VERSION ""

NS_ :

BS_:

BU_: PowertrainControlModule AtmosphericSensor SafetyRestraintSystem2 Aftertreatment_2_GasOutlet Aftertreatment_2_GasIntake DieselParticulateFilterControl Turbocharger SafetyRestraintSystem1 CabDisplay2 Aftertreatment_1_GasOutlet Aftertreatment_1_GasIntake OnBoardDataLogger OffBoardDiagnosticTool2 OffBoardDiagnosticTool1 FileServer ParkingBrakeController SeatController2 FanDriveController SteeringColumnUnit CommunicationUnitRadio CommunicationUnitSatellite CommunicationUnitCellular PropulsionBatteryCharger ChassisController2 ChassisController1 EngineValveControl AuxiliaryHeater2 AuxiliaryHeater1 ClutchUnit RampControl InformationSystem1 SuspensionSystemController2 OilSensor VehicleDynamicStability ExhaustEmissionController TransmissionDisplay2 TransmissionDisplay1 ClimateControl2 WaterPumpController RearAxleSteeringController LightingOperatorControl SeatController1 IgnitionController2 IgnitionController1 TirePressureController CabController2 CabController1 PneumaticSystemController SuspensionSystemController1 HydraulicPumpController EnduranceBrakingSystem RetarderExhaustEngine2 OnBoardDiagnosticUnit HeadwayController RetarderExhaustEngine1 CabDisplay1 ManagementComputer VirtualTerminal OffVehicleGateway PowerTakeOffFront HitchControl AuxiliaryValveControl BodyController TractorTrailerBridge1 StarterSystem ElectricalSystem VehicleSecurity VehicleNavigation AerodynamicControl ElectricalChargingSystem ClimateControl1 TripRecorder InstrumentCluster SuspensionDriveAxle2 SuspensionDriveAxle1 SuspensionSteerAxle SteeringController FuelSystem CruiseControl RetarderDriveline RetarderEngine BrakesDriveAxle2 BrakesDriveAxle1 BrakesSystemController BrakesSteerAxle AxleDrive2 AxleDrive1 AxleSteering PowerTakeOff ShiftConsoleSecondary ShiftConsolePrimary Transmission2 Transmission1 Engine2 Engine1

BO_ 2365400318 BJM10: 8 Vector__XXX
 SG_ Joystick10Button9PressedStatus : 62|2@1+ (1,0) [0|3] "" Vector__XXX
 SG_ Joystick10Button10PressedStatus : 60|2@1+ (1,0) [0|3] "" Vector__XXX
 SG_ Joystick10Button11PressedStatus : 58|2@1+ (1,0) [0|3] "" Vector__XXX
 SG_ Joystick10Button12PressedStatus : 56|2@1+ (1,0) [0|3] "" Vector__XXX
 SG_ Joystick10Button5PressedStatus : 54|2@1+ (1,0) [0|3] "" Vector__XXX
 SG_ Joystick10Button6PressedStatus : 52|2@1+ (1,0) [0|3] "" Vector__XXX
 SG_ Joystick10Button7PressedStatus : 50|2@1+ (1,0) [0|3] "" Vector__XXX
 SG_ Joystick10Button8PressedStatus : 48|2@1+ (1,0) [0|3] "" Vector__XXX
 SG_ Joystick10Button1PressedStatus : 46|2@1+ (1,0) [0|3] "" Vector__XXX
 SG_ Joystick10Button2PressedStatus : 44|2@1+ (1,0) [0|3] "" Vector__XXX
 SG_ Joystick10Button3PressedStatus : 42|2@1+ (1,0) [0|3] "" Vector__XXX
 SG_ Joystick10Button4PressedStatus : 40|2@1+ (1,0) [0|3] "" Vector__XXX
 SG_ Joystick10XAxisDetentPosStatus : 38|2@1+ (1,0) [0|3] "" Vector__XXX
 SG_ Joystick10YAxisDetentPosStatus : 36|2@1+ (1,0) [0|3] "" Vector__XXX
 SG_ Joystick10YAxisPos : 22|10@1+ (0.1,0) [0|102] "%" Vector__XXX
 SG_ Jystck10YAxsLvrFrwrdPstvPsStatus : 20|2@1+ (1,0) [0|3] "" Vector__XXX
 SG_ Jystck10YAxsLvrBckNgtvePosStatus : 18|2@1+ (1,0) [0|3] "" Vector__XXX
 SG_ Joystick10YAxisNeutralPosStatus : 16|2@1+ (1,0) [0|3] "" Vector__XXX
 SG_ Joystick10XAxisPos : 6|10@1+ (0.1,0) [0|102] "%" Vector__XXX
 SG_ Jystck10XAxsLvrRghtPstvPosStatus : 4|2@1+ (1,0) [0|3] "" Vector__XXX
 SG_ Jystck10XAxsLvrLftNgtvePosStatus : 2|2@1+ (1,0) [0|3] "" Vector__XXX
 SG_ Joystick10XAxisNeutralPosStatus : 0|2@1+ (1,0) [0|3] "" Vector__XXX

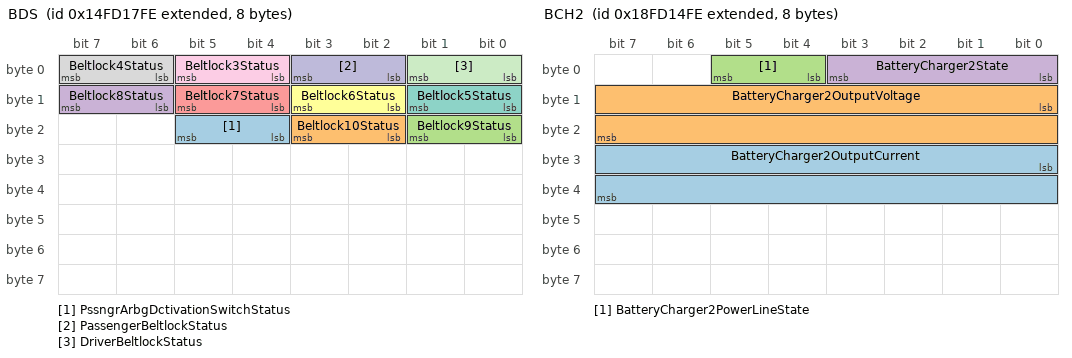
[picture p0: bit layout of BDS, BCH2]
BO_ 2499614718 BDS: 8 Vector__XXX
 SG_ PssngrArbgDctivationSwitchStatus : 20|2@1+ (1,0) [0|3] "" Vector__XXX
 SG_ Beltlock10Status : 18|2@1+ (1,0) [0|3] "" Vector__XXX
 SG_ Beltlock9Status : 16|2@1+ (1,0) [0|3] "" Vector__XXX
 SG_ Beltlock8Status : 14|2@1+ (1,0) [0|3] "" Vector__XXX
 SG_ Beltlock7Status : 12|2@1+ (1,0) [0|3] "" Vector__XXX
 SG_ Beltlock6Status : 10|2@1+ (1,0) [0|3] "" Vector__XXX
 SG_ Beltlock5Status : 8|2@1+ (1,0) [0|3] "" Vector__XXX
 SG_ Beltlock4Status : 6|2@1+ (1,0) [0|3] "" Vector__XXX
 SG_ Beltlock3Status : 4|2@1+ (1,0) [0|3] "" Vector__XXX
 SG_ PassengerBeltlockStatus : 2|2@1+ (1,0) [0|3] "" Vector__XXX
 SG_ DriverBeltlockStatus : 0|2@1+ (1,0) [0|3] "" Vector__XXX

BO_ 2566722814 BCH2: 8 Vector__XXX
 SG_ BatteryCharger2OutputCurrent : 24|16@1+ (0.05,-1600) [-1600|1612.75] "A" Vector__XXX
 SG_ BatteryCharger2OutputVoltage : 8|16@1+ (0.05,0) [0|3212.75] "V" Vector__XXX
 SG_ BatteryCharger2PowerLineState : 4|2@1+ (1,0) [0|3] "" Vector__XXX
 SG_ BatteryCharger2State : 0|4@1+ (1,0) [0|15] "" Vector__XXX

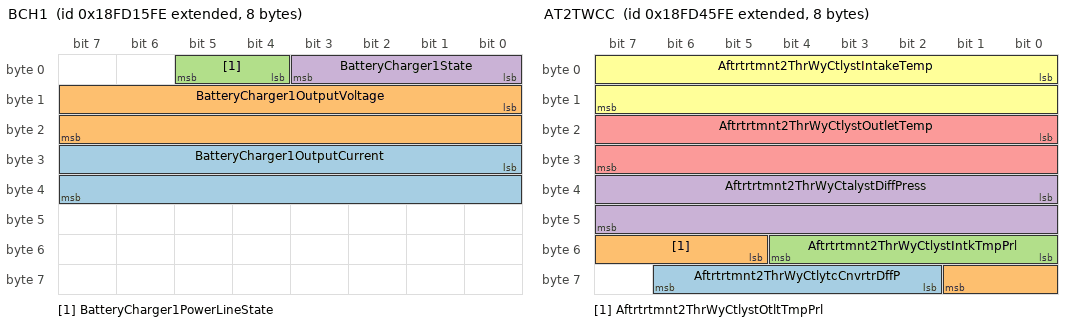
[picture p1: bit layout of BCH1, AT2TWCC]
BO_ 2566723070 BCH1: 8 Vector__XXX
 SG_ BatteryCharger1OutputCurrent : 24|16@1+ (0.05,-1600) [-1600|1612.75] "A" Vector__XXX
 SG_ BatteryCharger1OutputVoltage : 8|16@1+ (0.05,0) [0|3212.75] "V" Vector__XXX
 SG_ BatteryCharger1PowerLineState : 4|2@1+ (1,0) [0|3] "" Vector__XXX
 SG_ BatteryCharger1State : 0|4@1+ (1,0) [0|15] "" Vector__XXX

BO_ 2566725118 ATDT2: 8 Vector__XXX
 SG_ Aftrtrtmnt2ThrWyCtlystDffGasTemp : 16|16@1+ (0.03125,-273) [-273|1734.96875] "°C" Vector__XXX
 SG_ Aftrtrtmnt1ThrWyCtlystDffGasTemp : 0|16@1+ (0.03125,-273) [-273|1734.96875] "°C" Vector__XXX

BO_ 2566725374 ATDT1: 8 Vector__XXX
 SG_ Aftrtrtmnt2GsOxdtnCtlystDffGsTmp : 16|16@1+ (0.03125,-273) [-273|1734.96875] "°C" Vector__XXX
 SG_ Aftrtrtmnt1GsOxdtnCtlystDffGsTmp : 0|16@1+ (0.03125,-273) [-273|1734.96875] "°C" Vector__XXX

BO_ 2566712830 AT2WUDOC: 8 Vector__XXX
 SG_ Aftrtrtmnt2WrmUpDslOxdtnCtlystOt : 16|16@1+ (0.03125,-273) [-273|1734.96875] "°C" Vector__XXX
 SG_ Aftrtrtmnt2WrmUpDslOxdtnCtlystIn : 0|16@1+ (0.03125,-273) [-273|1734.96875] "°C" Vector__XXX

BO_ 2566735358 AT2TWCC: 8 Vector__XXX
 SG_ Aftrtrtmnt2ThrWyCtlytcCnvrtrDffP : 58|5@1+ (1,0) [0|31] "" Vector__XXX
 SG_ Aftrtrtmnt2ThrWyCtlystOtltTmpPrl : 53|5@1+ (1,0) [0|31] "" Vector__XXX
 SG_ Aftrtrtmnt2ThrWyCtlystIntkTmpPrl : 48|5@1+ (1,0) [0|31] "" Vector__XXX
 SG_ Aftrtrtmnt2ThrWyCtalystDiffPress : 32|16@1+ (0.1,0) [0|6425.5] "kPa" Vector__XXX
 SG_ Aftrtrtmnt2ThrWyCtlystOutletTemp : 16|16@1+ (0.03125,-273) [-273|1734.96875] "°C" Vector__XXX
 SG_ Aftrtrtmnt2ThrWyCtlystIntakeTemp : 0|16@1+ (0.03125,-273) [-273|1734.96875] "°C" Vector__XXX

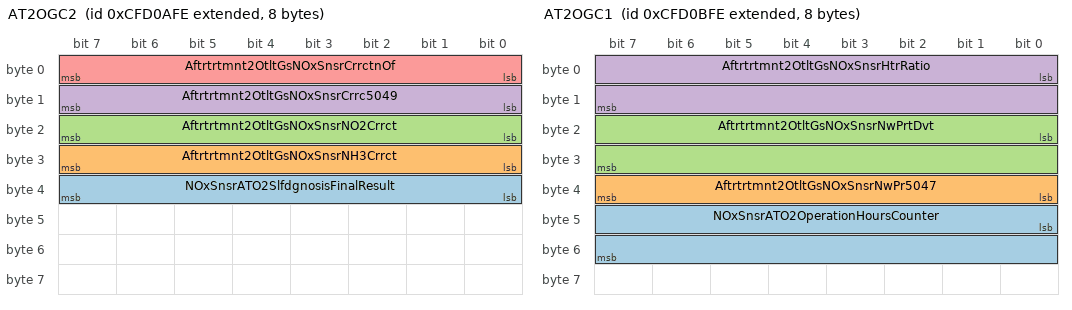
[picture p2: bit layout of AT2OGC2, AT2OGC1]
BO_ 2365393662 AT2OGC2: 8 Vector__XXX
 SG_ NOxSnsrATO2SlfdgnosisFinalResult : 32|8@1+ (1,0) [0|250] "" Vector__XXX
 SG_ Aftrtrtmnt2OtltGsNOxSnsrNH3Crrct : 24|8@1+ (0.5,0) [0|125] "%" Vector__XXX
 SG_ Aftrtrtmnt2OtltGsNOxSnsrNO2Crrct : 16|8@1+ (0.5,0) [0|125] "%" Vector__XXX
 SG_ Aftrtrtmnt2OtltGsNOxSnsrCrrc5049 : 8|8@1+ (0.5,0) [0|125] "%/bar" Vector__XXX
 SG_ Aftrtrtmnt2OtltGsNOxSnsrCrrctnOf : 0|8@1+ (0.5,0) [0|125] "%/bar" Vector__XXX

BO_ 2365393918 AT2OGC1: 8 Vector__XXX
 SG_ NOxSnsrATO2OperationHoursCounter : 40|16@1+ (1,0) [0|64255] "h" Vector__XXX
 SG_ Aftrtrtmnt2OtltGsNOxSnsrNwPr5047 : 32|8@1+ (1,-125) [-125|125] "ppm" Vector__XXX
 SG_ Aftrtrtmnt2OtltGsNOxSnsrNwPrtDvt : 16|16@1+ (0.1,-100) [-100|100] "%" Vector__XXX
 SG_ Aftrtrtmnt2OtltGsNOxSnsrHtrRatio : 0|16@1+ (0.001,0) [0|64.255] "" Vector__XXX

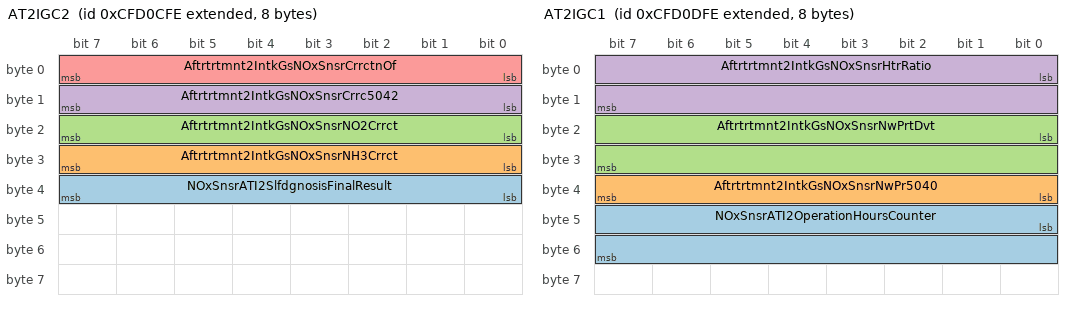
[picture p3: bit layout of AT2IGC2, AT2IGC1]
BO_ 2365394174 AT2IGC2: 8 Vector__XXX
 SG_ NOxSnsrATI2SlfdgnosisFinalResult : 32|8@1+ (1,0) [0|250] "" Vector__XXX
 SG_ Aftrtrtmnt2IntkGsNOxSnsrNH3Crrct : 24|8@1+ (0.5,0) [0|125] "%" Vector__XXX
 SG_ Aftrtrtmnt2IntkGsNOxSnsrNO2Crrct : 16|8@1+ (0.5,0) [0|125] "%" Vector__XXX
 SG_ Aftrtrtmnt2IntkGsNOxSnsrCrrc5042 : 8|8@1+ (0.5,0) [0|125] "%/bar" Vector__XXX
 SG_ Aftrtrtmnt2IntkGsNOxSnsrCrrctnOf : 0|8@1+ (0.5,0) [0|125] "%/bar" Vector__XXX

BO_ 2365394430 AT2IGC1: 8 Vector__XXX
 SG_ NOxSnsrATI2OperationHoursCounter : 40|16@1+ (1,0) [0|64255] "h" Vector__XXX
 SG_ Aftrtrtmnt2IntkGsNOxSnsrNwPr5040 : 32|8@1+ (1,-125) [-125|125] "ppm" Vector__XXX
 SG_ Aftrtrtmnt2IntkGsNOxSnsrNwPrtDvt : 16|16@1+ (0.1,-100) [-100|100] "%" Vector__XXX
 SG_ Aftrtrtmnt2IntkGsNOxSnsrHtrRatio : 0|16@1+ (0.001,0) [0|64.255] "" Vector__XXX

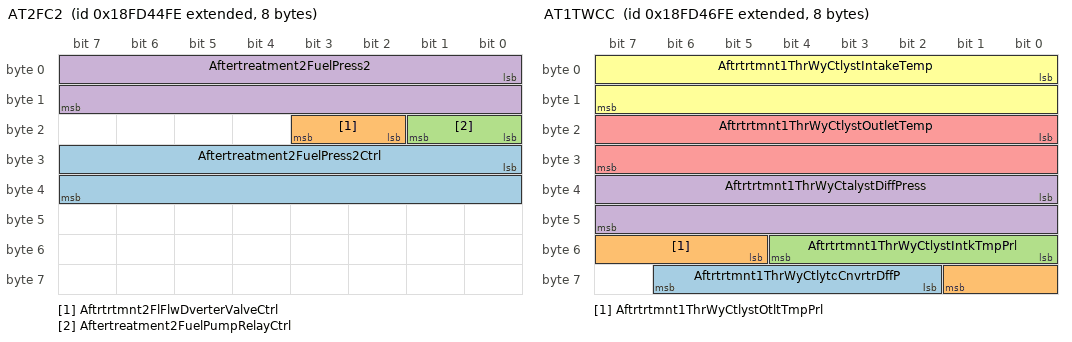
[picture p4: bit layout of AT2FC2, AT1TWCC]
BO_ 2566735102 AT2FC2: 8 Vector__XXX
 SG_ Aftertreatment2FuelPress2Ctrl : 24|16@1+ (0.0025,0) [0|160.6375] "%" Vector__XXX
 SG_ Aftrtrtmnt2FlFlwDverterValveCtrl : 18|2@1+ (1,0) [0|3] "" Vector__XXX
 SG_ Aftertreatment2FuelPumpRelayCtrl : 16|2@1+ (1,0) [0|3] "" Vector__XXX
 SG_ Aftertreatment2FuelPress2 : 0|16@1+ (0.1,0) [0|6425.5] "kPa" Vector__XXX

BO_ 2157313790 AT2DPFSSC: 8 Vector__XXX
 SG_ Aftrtrtmnt2DslPrtcltFltrStStndrd : 16|16@1+ (0.0025,0) [0|160.6375] "%" Vector__XXX
 SG_ Aftrtrtmnt2DslPrtcltFltrStMnClbO : 0|16@1+ (0.0025,0) [0|160.6375] "%" Vector__XXX

BO_ 2566724350 AT1WUDOC: 8 Vector__XXX
 SG_ Aftrtrtmnt1WrmUpDslOxdtnCtlystOt : 16|16@1+ (0.03125,-273) [-273|1734.96875] "°C" Vector__XXX
 SG_ Aftrtrtmnt1WrmUpDslOxdtnCtlystIn : 0|16@1+ (0.03125,-273) [-273|1734.96875] "°C" Vector__XXX

BO_ 2566735614 AT1TWCC: 8 Vector__XXX
 SG_ Aftrtrtmnt1ThrWyCtlytcCnvrtrDffP : 58|5@1+ (1,0) [0|31] "" Vector__XXX
 SG_ Aftrtrtmnt1ThrWyCtlystOtltTmpPrl : 53|5@1+ (1,0) [0|31] "" Vector__XXX
 SG_ Aftrtrtmnt1ThrWyCtlystIntkTmpPrl : 48|5@1+ (1,0) [0|31] "" Vector__XXX
 SG_ Aftrtrtmnt1ThrWyCtalystDiffPress : 32|16@1+ (0.1,0) [0|6425.5] "kPa" Vector__XXX
 SG_ Aftrtrtmnt1ThrWyCtlystOutletTemp : 16|16@1+ (0.03125,-273) [-273|1734.96875] "°C" Vector__XXX
 SG_ Aftrtrtmnt1ThrWyCtlystIntakeTemp : 0|16@1+ (0.03125,-273) [-273|1734.96875] "°C" Vector__XXX

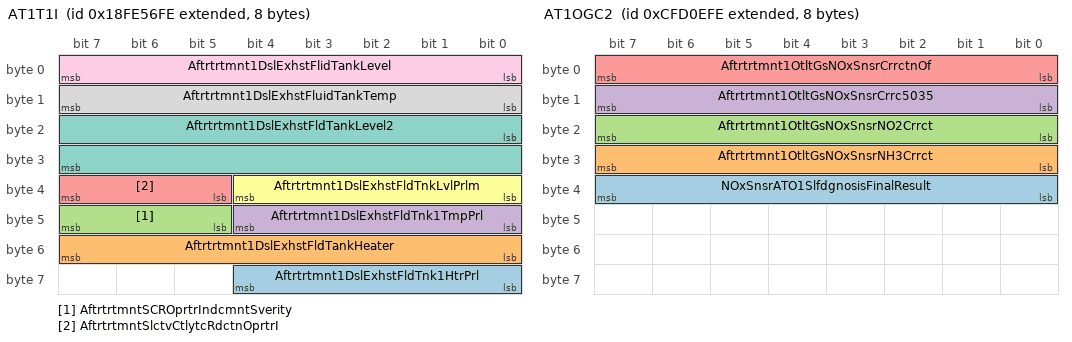
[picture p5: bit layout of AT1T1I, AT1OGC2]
BO_ 2566805246 AT1T1I: 8 Vector__XXX
 SG_ Aftrtrtmnt1DslExhstFldTnk1HtrPrl : 56|5@1+ (1,0) [0|31] "" Vector__XXX
 SG_ Aftrtrtmnt1DslExhstFldTankHeater : 48|8@1+ (0.4,0) [0|100] "%" Vector__XXX
 SG_ AftrtrtmntSCROprtrIndcmntSverity : 45|3@1+ (1,0) [0|7] "" Vector__XXX
 SG_ Aftrtrtmnt1DslExhstFldTnk1TmpPrl : 40|5@1+ (1,0) [0|31] "" Vector__XXX
 SG_ AftrtrtmntSlctvCtlytcRdctnOprtrI : 37|3@1+ (1,0) [0|7] "" Vector__XXX
 SG_ Aftrtrtmnt1DslExhstFldTnkLvlPrlm : 32|5@1+ (1,0) [0|31] "" Vector__XXX
 SG_ Aftrtrtmnt1DslExhstFldTankLevel2 : 16|16@1+ (0.1,0) [0|6425.5] "mm" Vector__XXX
 SG_ Aftrtrtmnt1DslExhstFluidTankTemp : 8|8@1+ (1,-40) [-40|210] "°C" Vector__XXX
 SG_ Aftrtrtmnt1DslExhstFlidTankLevel : 0|8@1+ (0.4,0) [0|100] "%" Vector__XXX

BO_ 2365394686 AT1OGC2: 8 Vector__XXX
 SG_ NOxSnsrATO1SlfdgnosisFinalResult : 32|8@1+ (1,0) [0|250] "" Vector__XXX
 SG_ Aftrtrtmnt1OtltGsNOxSnsrNH3Crrct : 24|8@1+ (0.5,0) [0|125] "%" Vector__XXX
 SG_ Aftrtrtmnt1OtltGsNOxSnsrNO2Crrct : 16|8@1+ (0.5,0) [0|125] "%" Vector__XXX
 SG_ Aftrtrtmnt1OtltGsNOxSnsrCrrc5035 : 8|8@1+ (0.5,0) [0|125] "%/bar" Vector__XXX
 SG_ Aftrtrtmnt1OtltGsNOxSnsrCrrctnOf : 0|8@1+ (0.5,0) [0|125] "%/bar" Vector__XXX

BO_ 2365394942 AT1OGC1: 8 Vector__XXX
 SG_ NOxSnsrATO1OperationHoursCounter : 40|16@1+ (1,0) [0|64255] "h" Vector__XXX
 SG_ Aftrtrtmnt1OtltGsNOxSnsrNwPr5033 : 32|8@1+ (1,-125) [-125|125] "ppm" Vector__XXX
 SG_ Aftrtrtmnt1OtltGsNOxSnsrNwPrtDvt : 16|16@1+ (0.1,-100) [-100|100] "%" Vector__XXX
 SG_ Aftrtrtmnt1OtltGsNOxSnsrHtrRatio : 0|16@1+ (0.001,0) [0|64.255] "" Vector__XXX

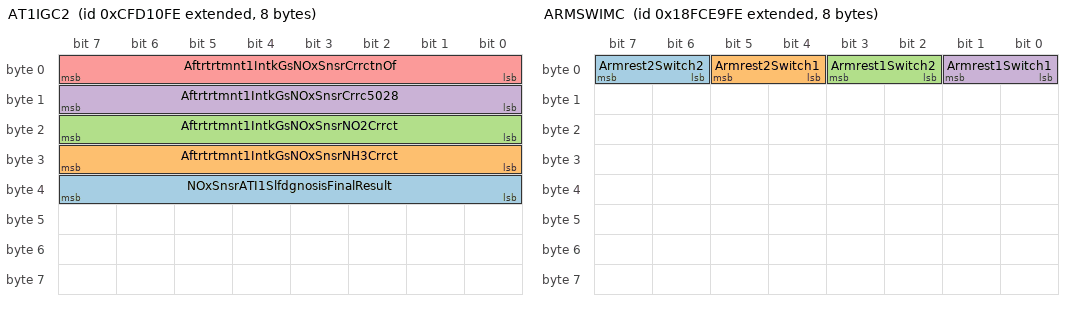
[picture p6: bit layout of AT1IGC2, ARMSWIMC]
BO_ 2365395198 AT1IGC2: 8 Vector__XXX
 SG_ NOxSnsrATI1SlfdgnosisFinalResult : 32|8@1+ (1,0) [0|250] "" Vector__XXX
 SG_ Aftrtrtmnt1IntkGsNOxSnsrNH3Crrct : 24|8@1+ (0.5,0) [0|125] "%" Vector__XXX
 SG_ Aftrtrtmnt1IntkGsNOxSnsrNO2Crrct : 16|8@1+ (0.5,0) [0|125] "%" Vector__XXX
 SG_ Aftrtrtmnt1IntkGsNOxSnsrCrrc5028 : 8|8@1+ (0.5,0) [0|125] "%/bar" Vector__XXX
 SG_ Aftrtrtmnt1IntkGsNOxSnsrCrrctnOf : 0|8@1+ (0.5,0) [0|125] "%/bar" Vector__XXX

BO_ 2365395454 AT1IGC1: 8 Vector__XXX
 SG_ NOxSnsrATI1OperationHoursCounter : 40|16@1+ (1,0) [0|64255] "h" Vector__XXX
 SG_ Aftrtrtmnt1IntkGsNOxSnsrNwPr5026 : 32|8@1+ (1,-125) [-125|125] "ppm" Vector__XXX
 SG_ Aftrtrtmnt1IntkGsNOxSnsrNwPrtDvt : 16|16@1+ (0.1,-100) [-100|100] "%" Vector__XXX
 SG_ Aftrtrtmnt1IntkGsNOxSnsrHtrRatio : 0|16@1+ (0.001,0) [0|64.255] "" Vector__XXX

BO_ 2157248254 AT1DPFSSC: 8 Vector__XXX
 SG_ Aftrtrtmnt1DslPrtcltFltrStStndrd : 16|16@1+ (0.0025,0) [0|160.6375] "%" Vector__XXX
 SG_ Aftrtrtmnt1DslPrtcltFltrStMnClbO : 0|16@1+ (0.0025,0) [0|160.6375] "%" Vector__XXX

BO_ 2566711806 ARMSWIMC: 8 Vector__XXX
 SG_ Armrest2Switch2 : 6|2@1+ (1,0) [0|3] "" Vector__XXX
 SG_ Armrest2Switch1 : 4|2@1+ (1,0) [0|3] "" Vector__XXX
 SG_ Armrest1Switch2 : 2|2@1+ (1,0) [0|3] "" Vector__XXX
 SG_ Armrest1Switch1 : 0|2@1+ (1,0) [0|3] "" Vector__XXX

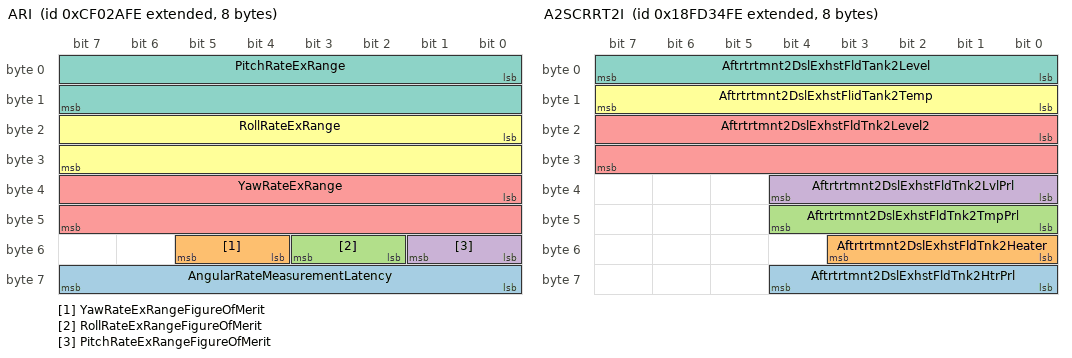
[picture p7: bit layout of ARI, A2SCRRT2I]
BO_ 2364549886 ARI: 8 Vector__XXX
 SG_ AngularRateMeasurementLatency : 56|8@1+ (0.5,0) [0|125] "ms" Vector__XXX
 SG_ YawRateExRangeFigureOfMerit : 52|2@1+ (1,0) [0|3] "" Vector__XXX
 SG_ RollRateExRangeFigureOfMerit : 50|2@1+ (1,0) [0|3] "" Vector__XXX
 SG_ PitchRateExRangeFigureOfMerit : 48|2@1+ (1,0) [0|3] "" Vector__XXX
 SG_ YawRateExRange : 32|16@1+ (0.0078125,-250) [-250|250.992] "deg/sec" Vector__XXX
 SG_ RollRateExRange : 16|16@1+ (0.0078125,-250) [-250|250.992] "deg/sec" Vector__XXX
 SG_ PitchRateExRange : 0|16@1+ (0.0078125,-250) [-250|250.992] "deg/sec" Vector__XXX

BO_ 2566712318 AFT2NAI: 8 Vector__XXX
 SG_ Aftrtrtmnt2NOxAdsrbrDSOxRgnrtnSt : 2|2@1+ (1,0) [0|3] "" Vector__XXX
 SG_ Aftrtrtmnt2NOxAdsrbrDNOxRgnrtnSt : 0|2@1+ (1,0) [0|3] "" Vector__XXX

BO_ 2566712574 AFT1NAI: 8 Vector__XXX
 SG_ Aftrtrtmnt1NOxAdsrbrDSOxRgnrtnSt : 2|2@1+ (1,0) [0|3] "" Vector__XXX
 SG_ Aftrtrtmnt1NOxAdsrbrDNOxRgnrtnSt : 0|2@1+ (1,0) [0|3] "" Vector__XXX

BO_ 2164078590 A2SCRSI: 8 Vector__XXX
 SG_ Aftrtrtmnt2SCRCnvrsionEfficiency : 32|8@1+ (0.4,0) [0|100] "%" Vector__XXX
 SG_ Aftrtrtmnt2SCRCmmnddCtlystDslExh : 16|16@1+ (0.05,0) [0|3212.75] "L/h" Vector__XXX
 SG_ Aftrtrtmnt2DslExhstFldAvrgCnsmpt : 0|16@1+ (0.05,0) [0|3212.75] "L/h" Vector__XXX

BO_ 2566731006 A2SCRRT2I: 8 Vector__XXX
 SG_ Aftrtrtmnt2DslExhstFldTnk2HtrPrl : 56|5@1+ (1,0) [0|31] "" Vector__XXX
 SG_ Aftrtrtmnt2DslExhstFldTnk2Heater : 48|4@1+ (1,0) [0|15] "" Vector__XXX
 SG_ Aftrtrtmnt2DslExhstFldTnk2TmpPrl : 40|5@1+ (1,0) [0|31] "" Vector__XXX
 SG_ Aftrtrtmnt2DslExhstFldTnk2LvlPrl : 32|5@1+ (1,0) [0|31] "" Vector__XXX
 SG_ Aftrtrtmnt2DslExhstFldTnk2Level2 : 16|16@1+ (0.1,0) [0|6425.5] "mm" Vector__XXX
 SG_ Aftrtrtmnt2DslExhstFlidTank2Temp : 8|8@1+ (1,-40) [-40|210] "°C" Vector__XXX
 SG_ Aftrtrtmnt2DslExhstFldTank2Level : 0|8@1+ (0.4,0) [0|100] "%" Vector__XXX

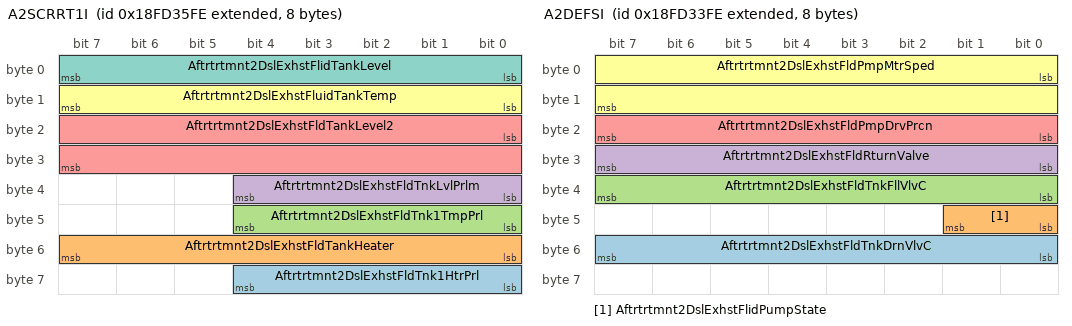
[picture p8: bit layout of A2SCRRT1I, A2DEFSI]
BO_ 2566731262 A2SCRRT1I: 8 Vector__XXX
 SG_ Aftrtrtmnt2DslExhstFldTnk1HtrPrl : 56|5@1+ (1,0) [0|31] "" Vector__XXX
 SG_ Aftrtrtmnt2DslExhstFldTankHeater : 48|8@1+ (0.4,0) [0|100] "%" Vector__XXX
 SG_ Aftrtrtmnt2DslExhstFldTnk1TmpPrl : 40|5@1+ (1,0) [0|31] "" Vector__XXX
 SG_ Aftrtrtmnt2DslExhstFldTnkLvlPrlm : 32|5@1+ (1,0) [0|31] "" Vector__XXX
 SG_ Aftrtrtmnt2DslExhstFldTankLevel2 : 16|16@1+ (0.1,0) [0|6425.5] "mm" Vector__XXX
 SG_ Aftrtrtmnt2DslExhstFluidTankTemp : 8|8@1+ (1,-40) [-40|210] "°C" Vector__XXX
 SG_ Aftrtrtmnt2DslExhstFlidTankLevel : 0|8@1+ (0.4,0) [0|100] "%" Vector__XXX

BO_ 2566730750 A2DEFSI: 8 Vector__XXX
 SG_ Aftrtrtmnt2DslExhstFldTnkDrnVlvC : 48|8@1+ (0.4,0) [0|100] "%" Vector__XXX
 SG_ Aftrtrtmnt2DslExhstFlidPumpState : 40|2@1+ (1,0) [0|3] "" Vector__XXX
 SG_ Aftrtrtmnt2DslExhstFldTnkFllVlvC : 32|8@1+ (0.4,0) [0|100] "%" Vector__XXX
 SG_ Aftrtrtmnt2DslExhstFldRturnValve : 24|8@1+ (0.4,0) [0|100] "%" Vector__XXX
 SG_ Aftrtrtmnt2DslExhstFldPmpDrvPrcn : 16|8@1+ (0.4,0) [0|100] "%" Vector__XXX
 SG_ Aftrtrtmnt2DslExhstFldPmpMtrSped : 0|16@1+ (0.5,0) [0|32127.5] "rpm" Vector__XXX

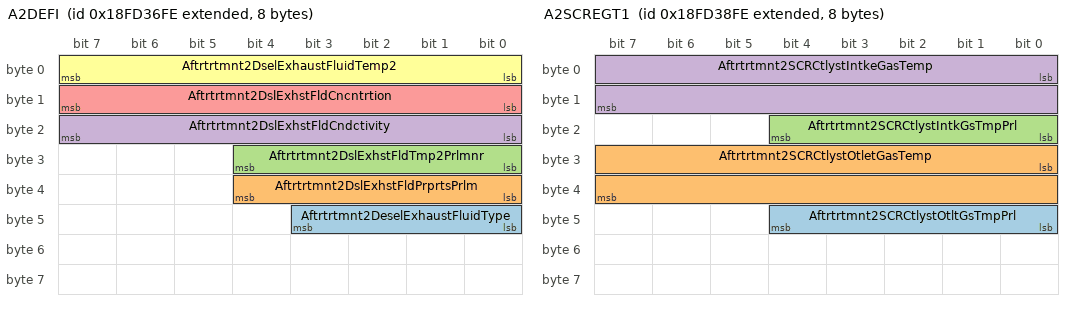
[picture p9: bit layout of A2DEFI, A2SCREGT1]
BO_ 2566731518 A2DEFI: 8 Vector__XXX
 SG_ Aftrtrtmnt2DeselExhaustFluidType : 40|4@1+ (1,0) [0|15] "" Vector__XXX
 SG_ Aftrtrtmnt2DslExhstFldPrprtsPrlm : 32|5@1+ (1,0) [0|31] "" Vector__XXX
 SG_ Aftrtrtmnt2DslExhstFldTmp2Prlmnr : 24|5@1+ (1,0) [0|31] "" Vector__XXX
 SG_ Aftrtrtmnt2DslExhstFldCndctivity : 16|8@1+ (5,0) [0|1250] "microSiemens/mm" Vector__XXX
 SG_ Aftrtrtmnt2DslExhstFldCncntrtion : 8|8@1+ (0.25,0) [0|62.5] "%" Vector__XXX
 SG_ Aftrtrtmnt2DselExhaustFluidTemp2 : 0|8@1+ (1,-40) [-40|210] "°C" Vector__XXX

BO_ 2566732030 A2SCREGT1: 8 Vector__XXX
 SG_ Aftrtrtmnt2SCRCtlystOtltGsTmpPrl : 40|5@1+ (1,0) [0|31] "" Vector__XXX
 SG_ Aftrtrtmnt2SCRCtlystOtletGasTemp : 24|16@1+ (0.03125,-273) [-273|1734.96875] "°C" Vector__XXX
 SG_ Aftrtrtmnt2SCRCtlystIntkGsTmpPrl : 16|5@1+ (1,0) [0|31] "" Vector__XXX
 SG_ Aftrtrtmnt2SCRCtlystIntkeGasTemp : 0|16@1+ (0.03125,-273) [-273|1734.96875] "°C" Vector__XXX

BO_ 2566732286 A2SCREGP: 8 Vector__XXX
 SG_ Aftertreatment2SCRIntakePress : 24|16@1+ (0.1,-3212.7) [-3212.7|3212.8] "kPa" Vector__XXX
 SG_ Aftrtrtmnt2SCRExhstGsDffPrssPrlm : 16|5@1+ (1,0) [0|31] "" Vector__XXX
 SG_ Aftrtrtmnt2SCRExhustGasDiffPress : 0|16@1+ (0.1,0) [0|6425.5] "kPa" Vector__XXX

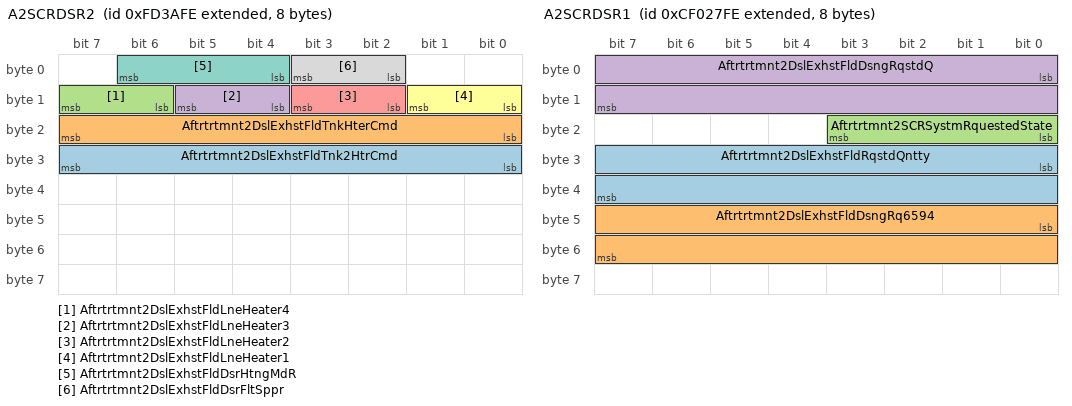
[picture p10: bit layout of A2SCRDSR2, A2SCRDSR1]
BO_ 2164079358 A2SCRDSR2: 8 Vector__XXX
 SG_ Aftrtrtmnt2DslExhstFldTnk2HtrCmd : 24|8@1+ (0.4,0) [0|100] "%" Vector__XXX
 SG_ Aftrtrtmnt2DslExhstFldTnkHterCmd : 16|8@1+ (0.4,0) [0|100] "%" Vector__XXX
 SG_ Aftrtrtmnt2DslExhstFldLneHeater4 : 14|2@1+ (1,0) [0|3] "" Vector__XXX
 SG_ Aftrtrtmnt2DslExhstFldLneHeater3 : 12|2@1+ (1,0) [0|3] "" Vector__XXX
 SG_ Aftrtrtmnt2DslExhstFldLneHeater2 : 10|2@1+ (1,0) [0|3] "" Vector__XXX
 SG_ Aftrtrtmnt2DslExhstFldLneHeater1 : 8|2@1+ (1,0) [0|3] "" Vector__XXX
 SG_ Aftrtrtmnt2DslExhstFldDsrHtngMdR : 4|3@1+ (1,0) [0|7] "" Vector__XXX
 SG_ Aftrtrtmnt2DslExhstFldDsrFltSppr : 2|2@1+ (1,0) [0|3] "" Vector__XXX

BO_ 2364549118 A2SCRDSR1: 8 Vector__XXX
 SG_ Aftrtrtmnt2DslExhstFldRqstdQntty : 24|16@1+ (0.1,0) [0|6425.5] "g" Vector__XXX
 SG_ Aftrtrtmnt2DslExhstFldDsngRq6594 : 40|16@1+ (0.05,0) [0|3212.75] "g/min" Vector__XXX
 SG_ Aftrtrtmnt2SCRSystmRquestedState : 16|4@1+ (1,0) [0|15] "" Vector__XXX
 SG_ Aftrtrtmnt2DslExhstFldDsngRqstdQ : 0|16@1+ (0.3,0) [0|19276.5] "g/h" Vector__XXX

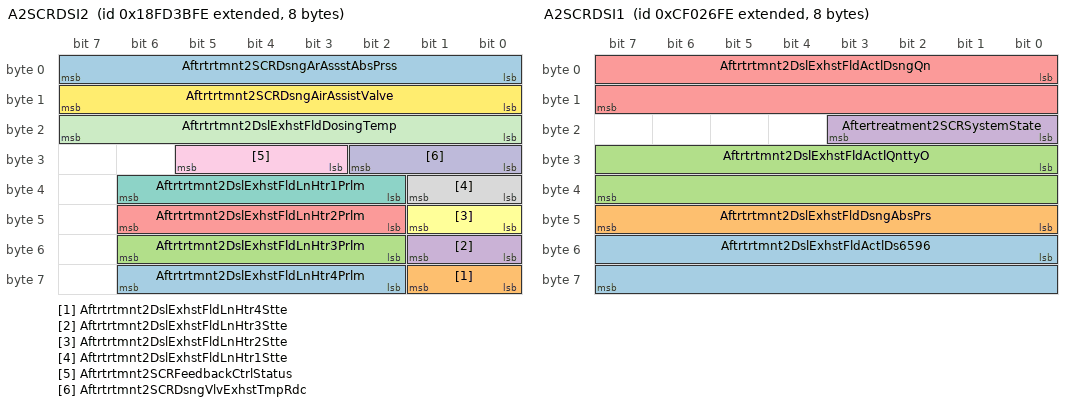
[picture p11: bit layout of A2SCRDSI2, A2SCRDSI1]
BO_ 2566732798 A2SCRDSI2: 8 Vector__XXX
 SG_ Aftrtrtmnt2DslExhstFldLnHtr4Prlm : 58|5@1+ (1,0) [0|31] "" Vector__XXX
 SG_ Aftrtrtmnt2DslExhstFldLnHtr4Stte : 56|2@1+ (1,0) [0|3] "" Vector__XXX
 SG_ Aftrtrtmnt2DslExhstFldLnHtr3Prlm : 50|5@1+ (1,0) [0|31] "" Vector__XXX
 SG_ Aftrtrtmnt2DslExhstFldLnHtr3Stte : 48|2@1+ (1,0) [0|3] "" Vector__XXX
 SG_ Aftrtrtmnt2DslExhstFldLnHtr2Prlm : 42|5@1+ (1,0) [0|31] "" Vector__XXX
 SG_ Aftrtrtmnt2DslExhstFldLnHtr2Stte : 40|2@1+ (1,0) [0|3] "" Vector__XXX
 SG_ Aftrtrtmnt2DslExhstFldLnHtr1Prlm : 34|5@1+ (1,0) [0|31] "" Vector__XXX
 SG_ Aftrtrtmnt2DslExhstFldLnHtr1Stte : 32|2@1+ (1,0) [0|3] "" Vector__XXX
 SG_ Aftrtrtmnt2SCRFeedbackCtrlStatus : 27|3@1+ (1,0) [0|7] "" Vector__XXX
 SG_ Aftrtrtmnt2SCRDsngVlvExhstTmpRdc : 24|3@1+ (1,0) [0|7] "" Vector__XXX
 SG_ Aftrtrtmnt2DslExhstFldDosingTemp : 16|8@1+ (1,-40) [-40|210] "°C" Vector__XXX
 SG_ Aftrtrtmnt2SCRDsngAirAssistValve : 8|8@1+ (0.4,0) [0|100] "%" Vector__XXX
 SG_ Aftrtrtmnt2SCRDsngArAssstAbsPrss : 0|8@1+ (8,0) [0|2000] "kPa" Vector__XXX

BO_ 2364548862 A2SCRDSI1: 8 Vector__XXX
 SG_ Aftrtrtmnt2DslExhstFldActlDs6596 : 48|16@1+ (0.05,0) [0|3212.75] "g/min" Vector__XXX
 SG_ Aftrtrtmnt2DslExhstFldDsngAbsPrs : 40|8@1+ (8,0) [0|2000] "kPa" Vector__XXX
 SG_ Aftrtrtmnt2DslExhstFldActlQnttyO : 24|16@1+ (0.1,0) [0|6425.5] "g" Vector__XXX
 SG_ Aftertreatment2SCRSystemState : 16|4@1+ (1,0) [0|15] "" Vector__XXX
 SG_ Aftrtrtmnt2DslExhstFldActlDsngQn : 0|16@1+ (0.3,0) [0|19276.5] "g/h" Vector__XXX

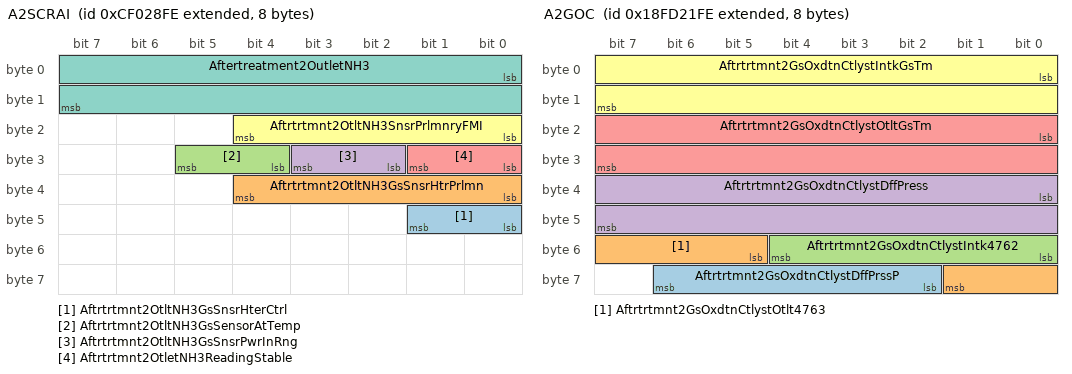
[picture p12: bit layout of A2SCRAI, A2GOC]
BO_ 2364549374 A2SCRAI: 8 Vector__XXX
 SG_ Aftrtrtmnt2OtltNH3GsSnsrHterCtrl : 40|2@1+ (1,0) [0|3] "" Vector__XXX
 SG_ Aftrtrtmnt2OtltNH3GsSnsrHtrPrlmn : 32|5@1+ (1,0) [0|31] "" Vector__XXX
 SG_ Aftrtrtmnt2OtltNH3GsSensorAtTemp : 28|2@1+ (1,0) [0|3] "" Vector__XXX
 SG_ Aftrtrtmnt2OtltNH3GsSnsrPwrInRng : 26|2@1+ (1,0) [0|3] "" Vector__XXX
 SG_ Aftrtrtmnt2OtletNH3ReadingStable : 24|2@1+ (1,0) [0|3] "" Vector__XXX
 SG_ Aftrtrtmnt2OtltNH3SnsrPrlmnryFMI : 16|5@1+ (1,0) [0|31] "" Vector__XXX
 SG_ Aftertreatment2OutletNH3 : 0|16@1+ (0.05,-200) [-200|3012.75] "ppm" Vector__XXX

BO_ 2566726142 A2GOC: 8 Vector__XXX
 SG_ Aftrtrtmnt2GsOxdtnCtlystDffPrssP : 58|5@1+ (1,0) [0|31] "" Vector__XXX
 SG_ Aftrtrtmnt2GsOxdtnCtlystOtlt4763 : 53|5@1+ (1,0) [0|31] "" Vector__XXX
 SG_ Aftrtrtmnt2GsOxdtnCtlystIntk4762 : 48|5@1+ (1,0) [0|31] "" Vector__XXX
 SG_ Aftrtrtmnt2GsOxdtnCtlystDffPress : 32|16@1+ (0.1,0) [0|6425.5] "kPa" Vector__XXX
 SG_ Aftrtrtmnt2GsOxdtnCtlystOtltGsTm : 16|16@1+ (0.03125,-273) [-273|1734.96875] "°C" Vector__XXX
 SG_ Aftrtrtmnt2GsOxdtnCtlystIntkGsTm : 0|16@1+ (0.03125,-273) [-273|1734.96875] "°C" Vector__XXX

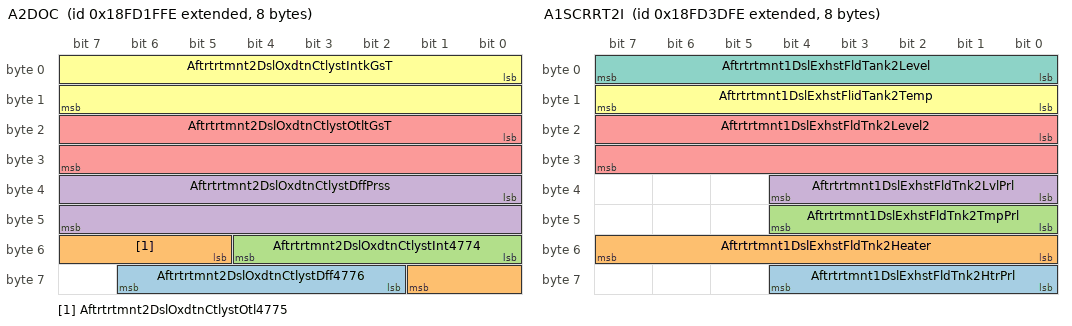
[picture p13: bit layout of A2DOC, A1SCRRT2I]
BO_ 2566725630 A2DOC: 8 Vector__XXX
 SG_ Aftrtrtmnt2DslOxdtnCtlystDff4776 : 58|5@1+ (1,0) [0|31] "" Vector__XXX
 SG_ Aftrtrtmnt2DslOxdtnCtlystOtl4775 : 53|5@1+ (1,0) [0|31] "" Vector__XXX
 SG_ Aftrtrtmnt2DslOxdtnCtlystInt4774 : 48|5@1+ (1,0) [0|31] "" Vector__XXX
 SG_ Aftrtrtmnt2DslOxdtnCtlystDffPrss : 32|16@1+ (0.5,0) [0|32127.5] "kPa" Vector__XXX
 SG_ Aftrtrtmnt2DslOxdtnCtlystOtltGsT : 16|16@1+ (0.03125,-273) [-273|1734.96875] "°C" Vector__XXX
 SG_ Aftrtrtmnt2DslOxdtnCtlystIntkGsT : 0|16@1+ (0.03125,-273) [-273|1734.96875] "°C" Vector__XXX

BO_ 2566733310 A1SCRRT2I: 8 Vector__XXX
 SG_ Aftrtrtmnt1DslExhstFldTnk2HtrPrl : 56|5@1+ (1,0) [0|31] "" Vector__XXX
 SG_ Aftrtrtmnt1DslExhstFldTnk2Heater : 48|8@1+ (0.4,0) [0|100] "%" Vector__XXX
 SG_ Aftrtrtmnt1DslExhstFldTnk2TmpPrl : 40|5@1+ (1,0) [0|31] "" Vector__XXX
 SG_ Aftrtrtmnt1DslExhstFldTnk2LvlPrl : 32|5@1+ (1,0) [0|31] "" Vector__XXX
 SG_ Aftrtrtmnt1DslExhstFldTnk2Level2 : 16|16@1+ (0.1,0) [0|6425.5] "mm" Vector__XXX
 SG_ Aftrtrtmnt1DslExhstFlidTank2Temp : 8|8@1+ (1,-40) [-40|210] "°C" Vector__XXX
 SG_ Aftrtrtmnt1DslExhstFldTank2Level : 0|8@1+ (0.4,0) [0|100] "%" Vector__XXX

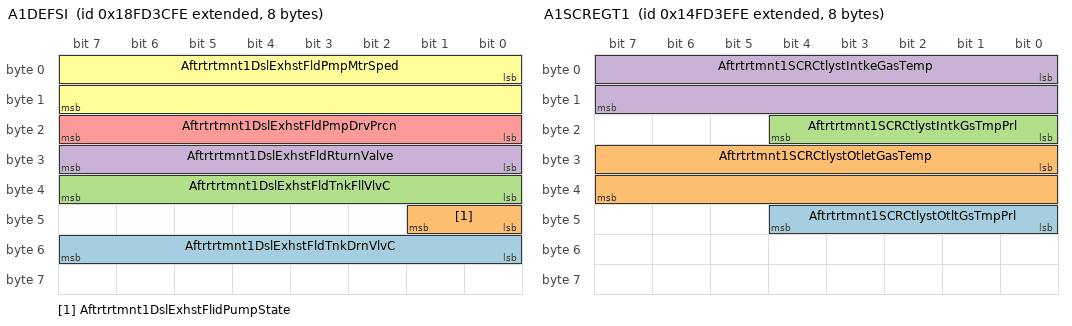
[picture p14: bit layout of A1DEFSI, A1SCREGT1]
BO_ 2566733054 A1DEFSI: 8 Vector__XXX
 SG_ Aftrtrtmnt1DslExhstFldTnkDrnVlvC : 48|8@1+ (0.4,0) [0|100] "%" Vector__XXX
 SG_ Aftrtrtmnt1DslExhstFlidPumpState : 40|2@1+ (1,0) [0|3] "" Vector__XXX
 SG_ Aftrtrtmnt1DslExhstFldTnkFllVlvC : 32|8@1+ (0.4,0) [0|100] "%" Vector__XXX
 SG_ Aftrtrtmnt1DslExhstFldRturnValve : 24|8@1+ (0.4,0) [0|100] "%" Vector__XXX
 SG_ Aftrtrtmnt1DslExhstFldPmpDrvPrcn : 16|8@1+ (0.4,0) [0|100] "%" Vector__XXX
 SG_ Aftrtrtmnt1DslExhstFldPmpMtrSped : 0|16@1+ (0.5,0) [0|32127.5] "rpm" Vector__XXX

BO_ 2499624702 A1SCREGT1: 8 Vector__XXX
 SG_ Aftrtrtmnt1SCRCtlystOtltGsTmpPrl : 40|5@1+ (1,0) [0|31] "" Vector__XXX
 SG_ Aftrtrtmnt1SCRCtlystOtletGasTemp : 24|16@1+ (0.03125,-273) [-273|1734.96875] "°C" Vector__XXX
 SG_ Aftrtrtmnt1SCRCtlystIntkGsTmpPrl : 16|5@1+ (1,0) [0|31] "" Vector__XXX
 SG_ Aftrtrtmnt1SCRCtlystIntkeGasTemp : 0|16@1+ (0.03125,-273) [-273|1734.96875] "°C" Vector__XXX

BO_ 2566733822 A1SCREGP: 8 Vector__XXX
 SG_ Aftertreatment1SCRIntakePress : 24|16@1+ (0.1,-3212.7) [-3212.7|3212.8] "kPa" Vector__XXX
 SG_ Aftrtrtmnt1SCRExhstGsDffPrssPrlm : 16|5@1+ (1,0) [0|31] "" Vector__XXX
 SG_ Aftrtrtmnt1SCRExhustGasDiffPress : 0|16@1+ (0.1,0) [0|6425.5] "kPa" Vector__XXX

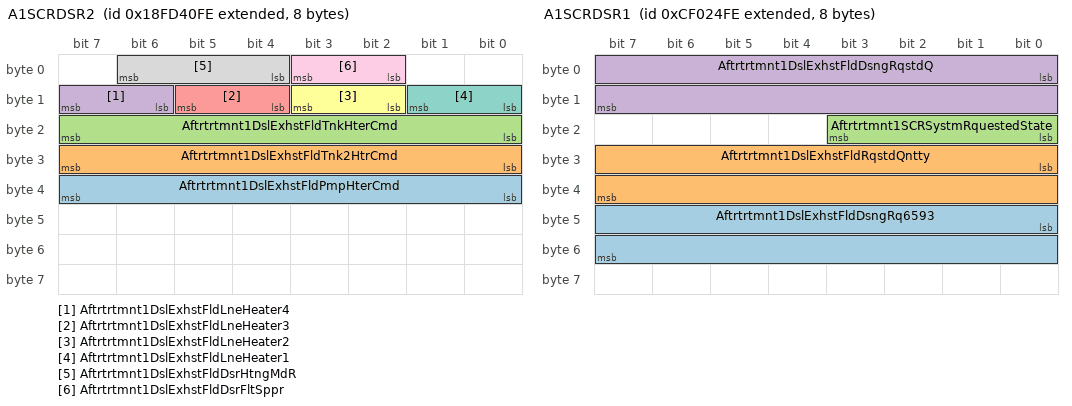
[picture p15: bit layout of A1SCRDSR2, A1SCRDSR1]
BO_ 2566734078 A1SCRDSR2: 8 Vector__XXX
 SG_ Aftrtrtmnt1DslExhstFldPmpHterCmd : 32|8@1+ (0.4,0) [0|100] "%" Vector__XXX
 SG_ Aftrtrtmnt1DslExhstFldTnk2HtrCmd : 24|8@1+ (0.4,0) [0|100] "%" Vector__XXX
 SG_ Aftrtrtmnt1DslExhstFldTnkHterCmd : 16|8@1+ (0.4,0) [0|100] "%" Vector__XXX
 SG_ Aftrtrtmnt1DslExhstFldLneHeater4 : 14|2@1+ (1,0) [0|3] "" Vector__XXX
 SG_ Aftrtrtmnt1DslExhstFldLneHeater3 : 12|2@1+ (1,0) [0|3] "" Vector__XXX
 SG_ Aftrtrtmnt1DslExhstFldLneHeater2 : 10|2@1+ (1,0) [0|3] "" Vector__XXX
 SG_ Aftrtrtmnt1DslExhstFldLneHeater1 : 8|2@1+ (1,0) [0|3] "" Vector__XXX
 SG_ Aftrtrtmnt1DslExhstFldDsrHtngMdR : 4|3@1+ (1,0) [0|7] "" Vector__XXX
 SG_ Aftrtrtmnt1DslExhstFldDsrFltSppr : 2|2@1+ (1,0) [0|3] "" Vector__XXX

BO_ 2364548350 A1SCRDSR1: 8 Vector__XXX
 SG_ Aftrtrtmnt1DslExhstFldDsngRq6593 : 40|16@1+ (0.05,0) [0|3212.75] "g/min" Vector__XXX
 SG_ Aftrtrtmnt1DslExhstFldRqstdQntty : 24|16@1+ (0.1,0) [0|6425.5] "g" Vector__XXX
 SG_ Aftrtrtmnt1SCRSystmRquestedState : 16|4@1+ (1,0) [0|15] "" Vector__XXX
 SG_ Aftrtrtmnt1DslExhstFldDsngRqstdQ : 0|16@1+ (0.3,0) [0|19276.5] "g/h" Vector__XXX

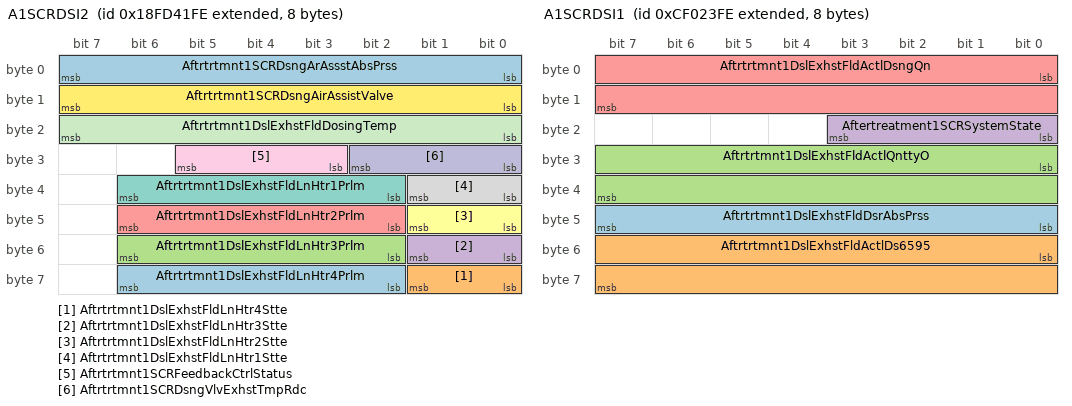
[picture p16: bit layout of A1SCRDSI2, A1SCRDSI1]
BO_ 2566734334 A1SCRDSI2: 8 Vector__XXX
 SG_ Aftrtrtmnt1DslExhstFldLnHtr4Prlm : 58|5@1+ (1,0) [0|31] "" Vector__XXX
 SG_ Aftrtrtmnt1DslExhstFldLnHtr4Stte : 56|2@1+ (1,0) [0|3] "" Vector__XXX
 SG_ Aftrtrtmnt1DslExhstFldLnHtr3Prlm : 50|5@1+ (1,0) [0|31] "" Vector__XXX
 SG_ Aftrtrtmnt1DslExhstFldLnHtr3Stte : 48|2@1+ (1,0) [0|3] "" Vector__XXX
 SG_ Aftrtrtmnt1DslExhstFldLnHtr2Prlm : 42|5@1+ (1,0) [0|31] "" Vector__XXX
 SG_ Aftrtrtmnt1DslExhstFldLnHtr2Stte : 40|2@1+ (1,0) [0|3] "" Vector__XXX
 SG_ Aftrtrtmnt1DslExhstFldLnHtr1Prlm : 34|5@1+ (1,0) [0|31] "" Vector__XXX
 SG_ Aftrtrtmnt1DslExhstFldLnHtr1Stte : 32|2@1+ (1,0) [0|3] "" Vector__XXX
 SG_ Aftrtrtmnt1SCRFeedbackCtrlStatus : 27|3@1+ (1,0) [0|7] "" Vector__XXX
 SG_ Aftrtrtmnt1SCRDsngVlvExhstTmpRdc : 24|3@1+ (1,0) [0|7] "" Vector__XXX
 SG_ Aftrtrtmnt1DslExhstFldDosingTemp : 16|8@1+ (1,-40) [-40|210] "°C" Vector__XXX
 SG_ Aftrtrtmnt1SCRDsngAirAssistValve : 8|8@1+ (0.4,0) [0|100] "%" Vector__XXX
 SG_ Aftrtrtmnt1SCRDsngArAssstAbsPrss : 0|8@1+ (8,0) [0|2000] "kPa" Vector__XXX

BO_ 2364548094 A1SCRDSI1: 8 Vector__XXX
 SG_ Aftrtrtmnt1DslExhstFldDsrAbsPrss : 40|8@1+ (8,0) [0|2000] "kPa" Vector__XXX
 SG_ Aftrtrtmnt1DslExhstFldActlDs6595 : 48|16@1+ (0.05,0) [0|3212.75] "g/min" Vector__XXX
 SG_ Aftrtrtmnt1DslExhstFldActlQnttyO : 24|16@1+ (0.1,0) [0|6425.5] "g" Vector__XXX
 SG_ Aftertreatment1SCRSystemState : 16|4@1+ (1,0) [0|15] "" Vector__XXX
 SG_ Aftrtrtmnt1DslExhstFldActlDsngQn : 0|16@1+ (0.3,0) [0|19276.5] "g/h" Vector__XXX

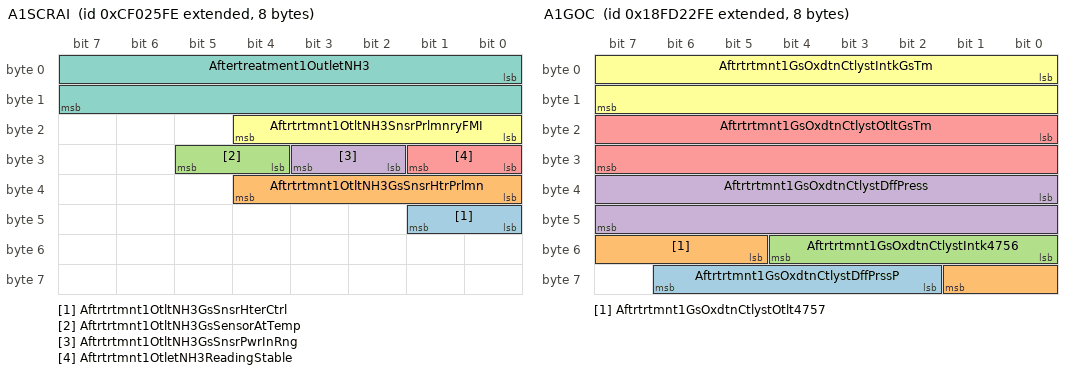
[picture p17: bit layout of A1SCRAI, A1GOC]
BO_ 2364548606 A1SCRAI: 8 Vector__XXX
 SG_ Aftrtrtmnt1OtltNH3GsSnsrHterCtrl : 40|2@1+ (1,0) [0|3] "" Vector__XXX
 SG_ Aftrtrtmnt1OtltNH3GsSnsrHtrPrlmn : 32|5@1+ (1,0) [0|31] "" Vector__XXX
 SG_ Aftrtrtmnt1OtltNH3GsSensorAtTemp : 28|2@1+ (1,0) [0|3] "" Vector__XXX
 SG_ Aftrtrtmnt1OtltNH3GsSnsrPwrInRng : 26|2@1+ (1,0) [0|3] "" Vector__XXX
 SG_ Aftrtrtmnt1OtletNH3ReadingStable : 24|2@1+ (1,0) [0|3] "" Vector__XXX
 SG_ Aftrtrtmnt1OtltNH3SnsrPrlmnryFMI : 16|5@1+ (1,0) [0|31] "" Vector__XXX
 SG_ Aftertreatment1OutletNH3 : 0|16@1+ (0.05,-200) [-200|3012.75] "ppm" Vector__XXX

BO_ 2566726398 A1GOC: 8 Vector__XXX
 SG_ Aftrtrtmnt1GsOxdtnCtlystDffPrssP : 58|5@1+ (1,0) [0|31] "" Vector__XXX
 SG_ Aftrtrtmnt1GsOxdtnCtlystOtlt4757 : 53|5@1+ (1,0) [0|31] "" Vector__XXX
 SG_ Aftrtrtmnt1GsOxdtnCtlystIntk4756 : 48|5@1+ (1,0) [0|31] "" Vector__XXX
 SG_ Aftrtrtmnt1GsOxdtnCtlystDffPress : 32|16@1+ (0.1,0) [0|6425.5] "kPa" Vector__XXX
 SG_ Aftrtrtmnt1GsOxdtnCtlystOtltGsTm : 16|16@1+ (0.03125,-273) [-273|1734.96875] "°C" Vector__XXX
 SG_ Aftrtrtmnt1GsOxdtnCtlystIntkGsTm : 0|16@1+ (0.03125,-273) [-273|1734.96875] "°C" Vector__XXX

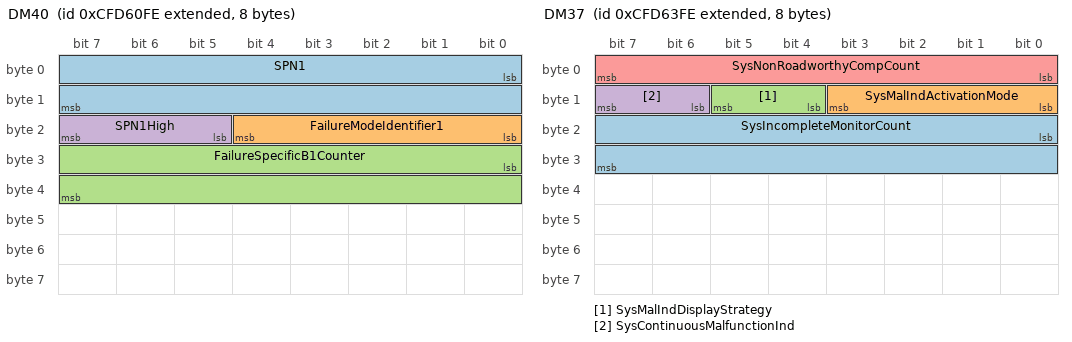
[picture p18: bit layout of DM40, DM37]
BO_ 2365415678 DM40: 8 Vector__XXX
 SG_ SPN1 : 0|16@1+ (1,0) [0|65536] "" Vector__XXX
 SG_ FailureModeIdentifier1 : 16|5@1+ (1,0) [0|0] "" Vector__XXX
 SG_ FailureSpecificB1Counter : 24|16@1+ (0.1,0) [0|6425.5] "hr" Vector__XXX
 SG_ SPN1High : 21|3@1+ (1,0) [0|7] "" Vector__XXX

BO_ 2365415934 DM39: 8 Vector__XXX
 SG_ SysGreatestB1Counter : 32|16@1+ (0.1,0) [0|6425.5] "hr" Vector__XXX
 SG_ SysCumulativeContinuousMITime : 0|32@1+ (0.05,0) [0|210554060.75] "hr" Vector__XXX

BO_ 2365416190 DM38: 8 Vector__XXX
 SG_ RegulationDescription : 0|8@1+ (1,0) [0|255] "" Vector__XXX

BO_ 2365416446 DM37: 8 Vector__XXX
 SG_ SysIncompleteMonitorCount : 16|16@1+ (1,0) [0|64512] "" Vector__XXX
 SG_ SysMalIndActivationMode : 8|4@1+ (1,0) [0|15] "" Vector__XXX
 SG_ SysMalIndDisplayStrategy : 12|2@1+ (1,0) [0|3] "" Vector__XXX
 SG_ SysContinuousMalfunctionInd : 14|2@1+ (1,0) [0|3] "" Vector__XXX
 SG_ SysNonRoadworthyCompCount : 0|8@1+ (1,0) [0|250] "" Vector__XXX

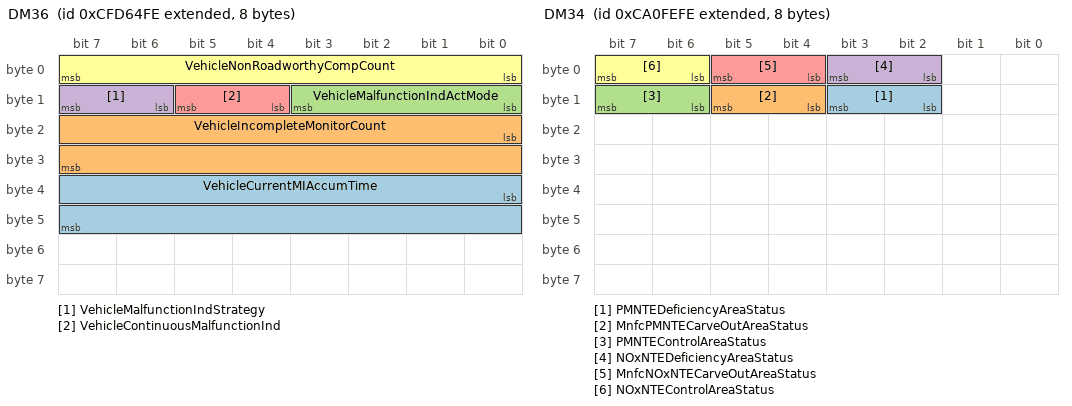
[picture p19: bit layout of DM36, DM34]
BO_ 2365416702 DM36: 8 Vector__XXX
 SG_ VehicleCurrentMIAccumTime : 32|16@1+ (1,0) [0|64255] "min" Vector__XXX
 SG_ VehicleIncompleteMonitorCount : 16|16@1+ (1,0) [0|64255] "" Vector__XXX
 SG_ VehicleMalfunctionIndActMode : 8|4@1+ (1,0) [0|15] "" Vector__XXX
 SG_ VehicleMalfunctionIndStrategy : 14|2@1+ (1,0) [0|3] "" Vector__XXX
 SG_ VehicleContinuousMalfunctionInd : 12|2@1+ (1,0) [0|3] "" Vector__XXX
 SG_ VehicleNonRoadworthyCompCount : 0|8@1+ (1,0) [0|250] "" Vector__XXX

BO_ 2359361278 DM34: 8 Vector__XXX
 SG_ PMNTEDeficiencyAreaStatus : 10|2@1+ (1,0) [0|3] "" Vector__XXX
 SG_ MnfcPMNTECarveOutAreaStatus : 12|2@1+ (1,0) [0|3] "" Vector__XXX
 SG_ PMNTEControlAreaStatus : 14|2@1+ (1,0) [0|3] "" Vector__XXX
 SG_ NOxNTEDeficiencyAreaStatus : 2|2@1+ (1,0) [0|3] "" Vector__XXX
 SG_ MnfcNOxNTECarveOutAreaStatus : 4|2@1+ (1,0) [0|3] "" Vector__XXX
 SG_ NOxNTEControlAreaStatus : 6|2@1+ (1,0) [0|3] "" Vector__XXX

BO_ 2292317950 DM33: 9 Vector__XXX
 SG_ AECDEngineHours1Timer2 : 40|32@1+ (1,0) [0|4294967295] "min" Vector__XXX
 SG_ AECDEngineHours1Timer1 : 8|32@1+ (1,0) [0|4294967295] "min" Vector__XXX
 SG_ AECDNumber1 : 0|8@1+ (1,0) [0|250] "" Vector__XXX

BO_ 2566809342 BM: 8 Vector__XXX
 SG_ BatteryMainSwitchHoldState : 0|2@1+ (1,0) [0|3] "" Vector__XXX

BO_ 2365446910 BJM3: 8 Vector__XXX
 SG_ Joystick3XAxisDetentPosStatus : 38|2@1+ (1,0) [0|3] "" Vector__XXX
 SG_ Joystick3Button9PressedStatus : 62|2@1+ (1,0) [0|3] "" Vector__XXX
 SG_ Joystick3Button10PressedStatus : 60|2@1+ (1,0) [0|3] "" Vector__XXX
 SG_ Joystick3Button11PressedStatus : 58|2@1+ (1,0) [0|3] "" Vector__XXX
 SG_ Joystick3Button12PressedStatus : 56|2@1+ (1,0) [0|3] "" Vector__XXX
 SG_ Joystick3YAxisDetentPosStatus : 36|2@1+ (1,0) [0|3] "" Vector__XXX
 SG_ Joystick3YAxisPos : 22|10@1+ (0.1,0) [0|100] "%" Vector__XXX
 SG_ Jystck3YAxsLvrFrwrdPstvPosStatus : 20|2@1+ (1,0) [0|3] "" Vector__XXX
 SG_ Jystck3YAxsLvrBckNgtivePosStatus : 18|2@1+ (1,0) [0|3] "" Vector__XXX
 SG_ Joystick3YAxisNeutralPosStatus : 16|2@1+ (1,0) [0|3] "" Vector__XXX
 SG_ Joystick3XAxisPos : 6|10@1+ (0.1,0) [0|100] "%" Vector__XXX
 SG_ Jystck3XAxsLvrRghtPstvePosStatus : 4|2@1+ (1,0) [0|3] "" Vector__XXX
 SG_ Jystck3XAxsLvrLftNgtivePosStatus : 2|2@1+ (1,0) [0|3] "" Vector__XXX
 SG_ Joystick3XAxisNeutralPosStatus : 0|2@1+ (1,0) [0|3] "" Vector__XXX
 SG_ Joystick3Button5PressedStatus : 54|2@1+ (1,0) [0|3] "" Vector__XXX
 SG_ Joystick3Button6PressedStatus : 52|2@1+ (1,0) [0|3] "" Vector__XXX
 SG_ Joystick3Button7PressedStatus : 50|2@1+ (1,0) [0|3] "" Vector__XXX
 SG_ Joystick3Button8PressedStatus : 48|2@1+ (1,0) [0|3] "" Vector__XXX
 SG_ Joystick3Button1PressedStatus : 46|2@1+ (1,0) [0|3] "" Vector__XXX
 SG_ Joystick3Button2PressedStatus : 44|2@1+ (1,0) [0|3] "" Vector__XXX
 SG_ Joystick3Button3PressedStatus : 42|2@1+ (1,0) [0|3] "" Vector__XXX
 SG_ Joystick3Button4PressedStatus : 40|2@1+ (1,0) [0|3] "" Vector__XXX

BO_ 2365446398 BJM2: 8 Vector__XXX
 SG_ Joystick2XAxisDetentPosStatus : 38|2@1+ (1,0) [0|3] "" Vector__XXX
 SG_ Joystick2YAxisDetentPosStatus : 36|2@1+ (1,0) [0|3] "" Vector__XXX
 SG_ Joystick2YAxisPos : 22|10@1+ (0.1,0) [0|100] "%" Vector__XXX
 SG_ Jystck2YAxsLvrFrwrdPstvPosStatus : 20|2@1+ (1,0) [0|3] "" Vector__XXX
 SG_ Jystck2YAxsLvrBckNgtivePosStatus : 18|2@1+ (1,0) [0|3] "" Vector__XXX
 SG_ Joystick2YAxisNeutralPosStatus : 16|2@1+ (1,0) [0|3] "" Vector__XXX
 SG_ Joystick2XAxisPos : 6|10@1+ (0.1,0) [0|100] "%" Vector__XXX
 SG_ Jystck2XAxsLvrRghtPstvePosStatus : 4|2@1+ (1,0) [0|3] "" Vector__XXX
 SG_ Jystck2XAxsLvrLftNgtivePosStatus : 2|2@1+ (1,0) [0|3] "" Vector__XXX
 SG_ Joystick2XAxisNeutralPosStatus : 0|2@1+ (1,0) [0|3] "" Vector__XXX
 SG_ Joystick2Button9PressedStatus : 62|2@1+ (1,0) [0|3] "" Vector__XXX
 SG_ Joystick2Button10PressedStatus : 60|2@1+ (1,0) [0|3] "" Vector__XXX
 SG_ Joystick2Button11PressedStatus : 58|2@1+ (1,0) [0|3] "" Vector__XXX
 SG_ Joystick2Button12PressedStatus : 56|2@1+ (1,0) [0|3] "" Vector__XXX
 SG_ Joystick2Button5PressedStatus : 54|2@1+ (1,0) [0|3] "" Vector__XXX
 SG_ Joystick2Button6PressedStatus : 52|2@1+ (1,0) [0|3] "" Vector__XXX
 SG_ Joystick2Button7PressedStatus : 50|2@1+ (1,0) [0|3] "" Vector__XXX
 SG_ Joystick2Button8PressedStatus : 48|2@1+ (1,0) [0|3] "" Vector__XXX
 SG_ Joystick2Button1PressedStatus : 46|2@1+ (1,0) [0|3] "" Vector__XXX
 SG_ Joystick2Button2PressedStatus : 44|2@1+ (1,0) [0|3] "" Vector__XXX
 SG_ Joystick2Button3PressedStatus : 42|2@1+ (1,0) [0|3] "" Vector__XXX
 SG_ Joystick2Button4PressedStatus : 40|2@1+ (1,0) [0|3] "" Vector__XXX

BO_ 2365445886 BJM1: 8 Vector__XXX
 SG_ Joystick1XAxisDetentPosStatus : 38|2@1+ (1,0) [0|3] "" Vector__XXX
 SG_ Joystick1YAxisDetentPosStatus : 36|2@1+ (1,0) [0|3] "" Vector__XXX
 SG_ Joystick1YAxisPos : 22|10@1+ (0.1,0) [0|100] "%" Vector__XXX
 SG_ Jystck1YAxsLvrFrwrdPstvPosStatus : 20|2@1+ (1,0) [0|3] "" Vector__XXX
 SG_ Jystck1YAxsLvrBckNgtivePosStatus : 18|2@1+ (1,0) [0|3] "" Vector__XXX
 SG_ Joystick1YAxisNeutralPosStatus : 16|2@1+ (1,0) [0|3] "" Vector__XXX
 SG_ Joystick1XAxisPos : 6|10@1+ (0.1,0) [0|100] "%" Vector__XXX
 SG_ Joystick1Button9PressedStatus : 62|2@1+ (1,0) [0|3] "" Vector__XXX
 SG_ Joystick1Button10PressedStatus : 60|2@1+ (1,0) [0|3] "" Vector__XXX
 SG_ Joystick1Button11PressedStatus : 58|2@1+ (1,0) [0|3] "" Vector__XXX
 SG_ Joystick1Button12PressedStatus : 56|2@1+ (1,0) [0|3] "" Vector__XXX
 SG_ Joystick1Button5PressedStatus : 54|2@1+ (1,0) [0|3] "" Vector__XXX
 SG_ Joystick1Button6PressedStatus : 52|2@1+ (1,0) [0|3] "" Vector__XXX
 SG_ Joystick1Button7PressedStatus : 50|2@1+ (1,0) [0|3] "" Vector__XXX
 SG_ Joystick1Button8PressedStatus : 48|2@1+ (1,0) [0|3] "" Vector__XXX
 SG_ Joystick1Button1PressedStatus : 46|2@1+ (1,0) [0|3] "" Vector__XXX
 SG_ Joystick1Button2PressedStatus : 44|2@1+ (1,0) [0|3] "" Vector__XXX
 SG_ Joystick1Button3PressedStatus : 42|2@1+ (1,0) [0|3] "" Vector__XXX
 SG_ Joystick1Button4PressedStatus : 40|2@1+ (1,0) [0|3] "" Vector__XXX
 SG_ Jystck1XAxsLvrRghtPstvePosStatus : 4|2@1+ (1,0) [0|3] "" Vector__XXX
 SG_ Jystck1XAxsLvrLftNgtivePosStatus : 2|2@1+ (1,0) [0|3] "" Vector__XXX
 SG_ Joystick1XAxisNeutralPosStatus : 0|2@1+ (1,0) [0|3] "" Vector__XXX

CM_ BO_ 2365400318 "Used to transfer information about the measured status of the 1st 2 axes and up to 12 buttons of a joystick.  Additional handle information is available in the Expanded Joystick Message.
10-bit position parameters are broadcast over 2 bytes.  The ...";
CM_ SG_ 2365400318 Joystick10Button9PressedStatus "Reports when the joystick button has been pressed.

00 Button not pressed
01 Button pressed
10 Error Indicator
11 Not Available";
CM_ SG_ 2365400318 Joystick10Button10PressedStatus "Reports when the joystick button has been pressed.

00 Button not pressed
01 Button pressed
10 Error Indicator
11 Not Available";
CM_ SG_ 2365400318 Joystick10Button11PressedStatus "Reports when the joystick button has been pressed.

00 Button not pressed
01 Button pressed
10 Error Indicator
11 Not Available";
CM_ SG_ 2365400318 Joystick10Button12PressedStatus "Reports when the joystick button has been pressed.

00 Button not pressed
01 Button pressed
10 Error Indicator
11 Not Available";
CM_ SG_ 2365400318 Joystick10Button5PressedStatus "Reports when the joystick button has been pressed.

00 Button not pressed
01 Button pressed
10 Error Indicator
11 Not Available";
CM_ SG_ 2365400318 Joystick10Button6PressedStatus "Reports when the joystick button has been pressed.

00 Button not pressed
01 Button pressed
10 Error Indicator
11 Not Available";
CM_ SG_ 2365400318 Joystick10Button7PressedStatus "Reports when the joystick button has been pressed.

00 Button not pressed
01 Button pressed
10 Error Indicator
11 Not Available";
CM_ SG_ 2365400318 Joystick10Button8PressedStatus "Reports when the joystick button has been pressed.

00 Button not pressed
01 Button pressed
10 Error Indicator
11 Not Available";
CM_ SG_ 2365400318 Joystick10Button1PressedStatus "Reports when the joystick button has been pressed.

00 Button not pressed
01 Button pressed
10 Error Indicator
11 Not Available";
CM_ SG_ 2365400318 Joystick10Button2PressedStatus "Reports when the joystick button has been pressed.

00 Button not pressed
01 Button pressed
10 Error Indicator
11 Not Available";
CM_ SG_ 2365400318 Joystick10Button3PressedStatus "Reports when the joystick button has been pressed.

00 Button not pressed
01 Button pressed
10 Error Indicator
11 Not Available";
CM_ SG_ 2365400318 Joystick10Button4PressedStatus "Reports when the joystick button has been pressed.

00 Button not pressed
01 Button pressed
10 Error Indicator
11 Not Available";
CM_ SG_ 2365400318 Joystick10XAxisDetentPosStatus "Reports when the current joystick position is in the detent position for that axis of travel.

00 Not in the Detent Position
01 In the Detent Position
10 Error Indicator
11 Not Available";
CM_ SG_ 2365400318 Joystick10YAxisDetentPosStatus "Reports when the current joystick position is in the detent position for that axis of travel.

00 Not in the Detent Position
01 In the Detent Position
10 Error Indicator
11 Not Available";
CM_ SG_ 2365400318 Joystick10YAxisPos "The position of the joystick in the relative motion of travel from the neutral position.  Position value of 0 is Neutral and position value 1000 (100%) is the end of linear zone.  Value of 1022 indicates an error has occurred.";
CM_ SG_ 2365400318 Jystck10YAxsLvrFrwrdPstvPsStatus "Reports when the current joystick position is on the positive travel side (forward, right, clockwise, up) relative to the neutral position for that axis of travel.
00 Not on Positive side of Neutral
01 On positive side of Neutral
10 Error ...";
CM_ SG_ 2365400318 Jystck10YAxsLvrBckNgtvePosStatus "Reports when the current joystick position is on the negative travel side (back, left, counterclockwise, down) relative to the neutral position for that axis of travel.
00 Not on negative side of Neutral
01 On negative side of Neutral
10 Error ...";
CM_ SG_ 2365400318 Joystick10YAxisNeutralPosStatus "Reports when the current joystick position is in the neutral position for that axis of travel.  The neutral position measurement must be determined from some mechanism other than the axis position measurement device.
00 Not in Neutral Position
01 ...";
CM_ SG_ 2365400318 Joystick10XAxisPos "The position of the joystick in the relative motion of travel from the neutral position.  Position value of 0 is Neutral and position value 1000 (100%) is the end of linear zone.  Value of 1022 indicates an error has occurred.";
CM_ SG_ 2365400318 Jystck10XAxsLvrRghtPstvPosStatus "Reports when the current joystick position is on the positive travel side (forward, right, clockwise, up) relative to the neutral position for that axis of travel.
00 Not on Positive side of Neutral
01 On positive side of Neutral
10 Error ...";
CM_ SG_ 2365400318 Jystck10XAxsLvrLftNgtvePosStatus "Reports when the current joystick position is on the negative travel side (back, left, counterclockwise, down) relative to the neutral position for that axis of travel.
00 Not on negative side of Neutral
01 On negative side of Neutral
10 Error ...";
CM_ SG_ 2365400318 Joystick10XAxisNeutralPosStatus "Reports when the current joystick position is in the neutral position for that axis of travel.  The neutral position measurement must be determined from some mechanism other than the axis position measurement device.
00 Not in Neutral Position
01 ...";
CM_ BO_ 2499614718 "Message containing Beltlock States and the Passener Airbag Deactivation Switch State.";
CM_ SG_ 2499614718 PssngrArbgDctivationSwitchStatus "State of switch used to deactivate Passenger Airbag manually.

00 = passenger airbag activated
01 = passenger airbag deactivated
10 = Error - State of deactivation switch cannot be determined
11 = not available";
CM_ SG_ 2499614718 Beltlock10Status "State of switch used to determine if Beltlock 10 is buckled.

00 = unlocked
01 = locked
10 = Error - Beltlock state cannot be determined
11 = not available";
CM_ SG_ 2499614718 Beltlock9Status "State of switch used to determine if Beltlock 9 is buckled.

00 = unlocked
01 = locked
10 = Error - Beltlock state cannot be determined
11 = not available";
CM_ SG_ 2499614718 Beltlock8Status "State of switch used to determine if Beltlock 8 is buckled.

00 = unlocked
01 = locked
10 = Error - Beltlock state cannot be determined
11 = not available";
CM_ SG_ 2499614718 Beltlock7Status "State of switch used to determine if Beltlock 7 is buckled.

00 = unlocked
01 = locked
10 = Error - Beltlock state cannot be determined
11 = not available";
CM_ SG_ 2499614718 Beltlock6Status "State of switch used to determine if Beltlock 6 is buckled.

00 = unlocked
01 = locked
10 = Error - Beltlock state cannot be determined
11 = not available";
CM_ SG_ 2499614718 Beltlock5Status "State of switch used to determine if Beltlock 5 is buckled.

00 = unlocked
01 = locked
10 = Error - Beltlock state cannot be determined
11 = not available";
CM_ SG_ 2499614718 Beltlock4Status "State of switch used to determine if Beltlock 4 is buckled.

00 = unlocked
01 = locked
10 = Error - Beltlock state cannot be determined
11 = not available";
CM_ SG_ 2499614718 Beltlock3Status "State of switch used to determine if Beltlock 3 is buckled.

00 = unlocked
01 = locked
10 = Error - Beltlock state cannot be determined
11 = not available";
CM_ SG_ 2499614718 PassengerBeltlockStatus "State of switch used to determine if Passenger Beltlock is buckled.

00 = unlocked
01 = locked
10 = Error - Beltlock state cannot be determined
11 = not available";
CM_ SG_ 2499614718 DriverBeltlockStatus "State of switch used to determine if Driver Beltlock is buckled.

00 = unlocked
01 = locked
10 = Error - Beltlock state cannot be determined
11 = not available";
CM_ BO_ 2566722814 "Parameters for the battery charger connected to the auxiliary battery.";
CM_ SG_ 2566722814 BatteryCharger2OutputCurrent "Output current of the battery charger connected to the main battery. If positive, this parameter shows the charging current of the battery charger connected to the main battery.  Otherwise, if the charger hardware permits, this parameter represents ...";
CM_ SG_ 2566722814 BatteryCharger2OutputVoltage "Output voltage measured on the battery terminals of the offline battery charger connected to the auxiliary battery.";
CM_ SG_ 2566722814 BatteryCharger2PowerLineState "A state of the battery charger connection to the power line for the charger connected to the auxiliary battery.
0 - Disconnected. The power line is disconnected from the charger.
1 - Connected. The power line is connected to the charger.
2 - ...";
CM_ SG_ 2566722814 BatteryCharger2State "A state of the offline battery charger connected to the auxiliary battery.
0 - Idling. The power line or the battery is disconnected from the charger.
1 - Charging the battery.
2 - Stand-by or maintaining the battery charge.
3 to 12 - Reserved
 ...";
CM_ BO_ 2566723070 "Parameters for the battery charger connected to the main battery.";
CM_ SG_ 2566723070 BatteryCharger1OutputCurrent "Output current of the battery charger connected to the main battery. If positive, this parameter shows the charging current of the battery charger connected to the main battery.  Otherwise, if the charger hardware permits, this parameter represents ...";
CM_ SG_ 2566723070 BatteryCharger1OutputVoltage "Output voltage measured on the battery terminals of the battery charger connected to the main battery.";
CM_ SG_ 2566723070 BatteryCharger1PowerLineState "A state of the battery charger connection to the power line for the charger connected to the main battery.
0 - Disconnected. The power line is disconnected from the charger.
1 - Connected. The power line is connected to the charger.
2 - Error
3 ...";
CM_ SG_ 2566723070 BatteryCharger1State "A state of the battery charger connected to the main battery.
0 - Idling. The power line or the battery is disconnected from the charger.
1 - Charging the battery.
2 - Stand-by or maintaining the battery charge.
3 to 12 - Reserved
13 - Battery ...";
CM_ BO_ 2566725118 "The purpose of this PGN is to group the aftertreatment differential temperature data. These values include the differential temperature measure between the intake and outlet of aftertreatment components.";
CM_ SG_ 2566725118 Aftrtrtmnt2ThrWyCtlystDffGasTemp "The differential engine combustion byproducts gas temperature measured between the intake and outlet of the three way catalyst for exhaust bank 2.";
CM_ SG_ 2566725118 Aftrtrtmnt1ThrWyCtlystDffGasTemp "The differential engine combustion byproducts gas temperature measured between the intake and outlet of the three way catalyst for exhaust bank 1.";
CM_ BO_ 2566725374 "The purpose of this PGN is to group the aftertreatment differential temperature data. These values include the differential temperature measure between the intake and outlet of aftertreatment components.";
CM_ SG_ 2566725374 Aftrtrtmnt2GsOxdtnCtlystDffGsTmp "The differential engine combustion byproducts gas temperature measured between the intake and outlet of the gas oxidation catalyst for exhaust bank 2.  This parameter should be used with engine fueled by gaseous fuel like natural gas or propane ...";
CM_ SG_ 2566725374 Aftrtrtmnt1GsOxdtnCtlystDffGsTmp "The differential engine combustion byproducts gas temperature measured between the intake and outlet of the gas oxidation catalyst for exhaust bank 1.  This parameter should be used with engine fueled by gaseous fuel like natural gas or propane ...";
CM_ BO_ 2566712830 "This PGN contains information for the warm up oxidation catalytic converter in exhaust bank 2.";
CM_ SG_ 2566712830 Aftrtrtmnt2WrmUpDslOxdtnCtlystOt "Temperature of engine combustion byproducts leaving the warm up Diesel Oxidation Catalyst in exhaust bank 2.  This diesel parameter should be used with engines fueled by diesel fuel (not gaseous fuel like natural gas or propane).  A separate ...";
CM_ SG_ 2566712830 Aftrtrtmnt2WrmUpDslOxdtnCtlystIn "Temperature of engine combustion byproducts entering the warm up Diesel Oxidation Catalyst in exhaust bank 2.  This diesel parameter should be used with engines fueled by diesel fuel (not gaseous fuel like natural gas or propane).  A separate ...";
CM_ BO_ 2566735358 "The purpose of this PGN is to group the aftertreatment Three Way Catalyst data for bank 2. These values include the intake temperature, outlet temperature and differential pressure as well as the associated preliminary FMIs.
Note: The 5 bits of SPN ...";
CM_ SG_ 2566735358 Aftrtrtmnt2ThrWyCtlytcCnvrtrDffP "Used to identify the applicable J1939-73 FMI detected in the Three Way Catalytic Converter differential pressure sensor by the manufacturer’s sensor control software in exhaust bank 2. When there is no failure FMI 31 is sent. In the case of multiple ...";
CM_ SG_ 2566735358 Aftrtrtmnt2ThrWyCtlystOtltTmpPrl "Used to identify the applicable J1939-73 FMI detected in the Three Way Catalyst outlet temperature sensor by the manufacturer’s sensor control software in exhaust bank 2. When there is no failure FMI 31 is sent. In the case of multiple failures the ...";
CM_ SG_ 2566735358 Aftrtrtmnt2ThrWyCtlystIntkTmpPrl "Used to identify the applicable J1939-73 FMI detected in the Three Way Catalyst intake temperature sensor by the manufacturer’s sensor control software in exhaust bank 2. When there is no failure FMI 31 is sent. In the case of multiple failures the ...";
CM_ SG_ 2566735358 Aftrtrtmnt2ThrWyCtalystDiffPress "Exhaust differential pressure measured between the intake and exhaust of a Three Way Catalyst in exhaust bank 2.

(For a single exhaust bank system, refer to parameters in PGN 64838.)";
CM_ SG_ 2566735358 Aftrtrtmnt2ThrWyCtlystOutletTemp "Temperature of engine combustion byproducts leaving the Three Way Catalyst in exhaust bank 2. 
 
(For a single exhaust bank system, refer to parameters in PGN 64838.)";
CM_ SG_ 2566735358 Aftrtrtmnt2ThrWyCtlystIntakeTemp "Temperature of engine combustion byproducts entering the Three Way Catalyst in exhaust bank 2.

(For a single exhaust bank system, refer to parameters in PGN 64838.)";
CM_ SG_ 2365393662 NOxSnsrATO2SlfdgnosisFinalResult "Self-diagnosis result for NOx sensor ATO2 (Aftertreatment Outlet Bank 2) as a ratio of detected value to reference value defined by supplier.
This result is used to determine if the signal resulting from the self-diagnosis test (as represented as a ...";
CM_ SG_ 2365393662 Aftrtrtmnt2OtltGsNOxSnsrNH3Crrct "Correction of NH3 at the NOx-signal to correct (recalculate) sensor signal on the Engine ECU side.";
CM_ SG_ 2365393662 Aftrtrtmnt2OtltGsNOxSnsrNO2Crrct "Correction of NO2 at the NOx-signal to correct (recalculate) sensor signal on the Engine ECU side.";
CM_ SG_ 2365393662 Aftrtrtmnt2OtltGsNOxSnsrCrrc5049 "Correction of pressure NOx-signal to correct (recalculate) sensor signal on the Engine ECU side.";
CM_ SG_ 2365393662 Aftrtrtmnt2OtltGsNOxSnsrCrrctnOf "Correction of pressure Lambda-signal to correct (recalculate) sensor signal on the Engine ECU side.";
CM_ SG_ 2365393918 NOxSnsrATO2OperationHoursCounter "Counted hours that the NOx-sensor was operated with status \"dewpoint reached\"";
CM_ SG_ 2365393918 Aftrtrtmnt2OtltGsNOxSnsrNwPr5047 "New part deviation NOx_Offset to correct (recalculate) sensor signal on the Engine ECU side.";
CM_ SG_ 2365393918 Aftrtrtmnt2OtltGsNOxSnsrNwPrtDvt "New part deviation NOx_Gain to correct (recalculate) sensor signal on the Engine ECU side.";
CM_ SG_ 2365393918 Aftrtrtmnt2OtltGsNOxSnsrHtrRatio "Heater ratio to determine temperature at sensor tip.";
CM_ SG_ 2365394174 NOxSnsrATI2SlfdgnosisFinalResult "Self-diagnosis result for NOx sensor ATI2 (Aftertreatment Intake Bank 2) as a ratio of detected value to reference value defined by supplier.
This result is used to determine if the signal resulting from the self-diagnosis test (as represented as a ...";
CM_ SG_ 2365394174 Aftrtrtmnt2IntkGsNOxSnsrNH3Crrct "Correction of NH3 at the NOx-signal to correct (recalculate) sensor signal on the Engine ECU side.";
CM_ SG_ 2365394174 Aftrtrtmnt2IntkGsNOxSnsrNO2Crrct "Correction of NO2 at the NOx-signal to correct (recalculate) sensor signal on the Engine ECU side.";
CM_ SG_ 2365394174 Aftrtrtmnt2IntkGsNOxSnsrCrrc5042 "Correction of pressure NOx-signal to correct (recalculate) sensor signal on the Engine ECU side.";
CM_ SG_ 2365394174 Aftrtrtmnt2IntkGsNOxSnsrCrrctnOf "Correction of pressure Lambda-signal to correct (recalculate) sensor signal on the Engine ECU side.";
CM_ SG_ 2365394430 NOxSnsrATI2OperationHoursCounter "Counted hours that the NOx-sensor was operated with status \"dewpoint reached\"";
CM_ SG_ 2365394430 Aftrtrtmnt2IntkGsNOxSnsrNwPr5040 "New part deviation NOx_Offset to correct (recalculate) sensor signal on the Engine ECU side.";
CM_ SG_ 2365394430 Aftrtrtmnt2IntkGsNOxSnsrNwPrtDvt "New part deviation NOx_Gain to correct (recalculate) sensor signal on the Engine ECU side.";
CM_ SG_ 2365394430 Aftrtrtmnt2IntkGsNOxSnsrHtrRatio "Heater ratio to determine temperature at sensor tip.";
CM_ BO_ 2566735102 "Contains information about the aftertreatment 2 fuel system. See also PGN 64928.";
CM_ SG_ 2566735102 Aftertreatment2FuelPress2Ctrl "Indicates how the device is controlling the aftertreatment 2 fuel pressure 2 regulating control valve.   0% = fully closed, 100%=fully open.";
CM_ SG_ 2566735102 Aftrtrtmnt2FlFlwDverterValveCtrl "Indicates how the device is controlling the aftertreatment 2 fuel flow diverter valve. When this valve is on it diverts fuel flow from the Aftertreatment 2 Regeneration Device.

00 off
01 on
10 reserved for SAE assignment
11 not available";
CM_ SG_ 2566735102 Aftertreatment2FuelPumpRelayCtrl "Indicates how the device is controlling the aftertreatment 2 fuel pump relay.

00 off
01 on
10 reserved for SAE assignment
11 not available";
CM_ SG_ 2566735102 Aftertreatment2FuelPress2 "Second fuel pressure measurement for the aftertreatment 2 system.";
CM_ BO_ 2157313790 "The purpose of this PGN is to group the Aftertreatment 2 DPF soot measurement calibration parameters. These values include soot sensor signal mean and standard deviation calibration levels. These calibration levels are associated with Diesel ...";
CM_ SG_ 2157313790 Aftrtrtmnt2DslPrtcltFltrStStndrd "Calibration offset for the soot standard deviation for Aftertreatment 2 Diesel Particulate Filter soot sensor.";
CM_ SG_ 2157313790 Aftrtrtmnt2DslPrtcltFltrStMnClbO "Calibration offset for the soot Mean for Aftertreatment 2 Diesel Particulate Filter soot sensor.";
CM_ BO_ 2566724350 "This PGN contains information for the warm up oxidation catalytic converter in exhaust bank 1.";
CM_ SG_ 2566724350 Aftrtrtmnt1WrmUpDslOxdtnCtlystOt "This is the temperature measured at the outlet of the warm up oxidation catalytic converter in exhaust bank 1.";
CM_ SG_ 2566724350 Aftrtrtmnt1WrmUpDslOxdtnCtlystIn "This is the temperature measured at the intake of the warm up oxidation catalytic converter in exhaust bank 1.";
CM_ BO_ 2566735614 "The purpose of this PGN is to group the aftertreatment Three Way Catalyst data for bank 1. These values include the intake temperature, outlet temperature and differential pressure as well as the associated preliminary FMIs.
Note: The 5 bits of SPN ...";
CM_ SG_ 2566735614 Aftrtrtmnt1ThrWyCtlytcCnvrtrDffP "Used to identify the applicable J1939-73 FMI detected in the Three Way Catalytic Converter differential pressure sensor by the manufacturer’s sensor control software in exhaust bank 1. When there is no failure FMI 31 is sent. In the case of multiple ...";
CM_ SG_ 2566735614 Aftrtrtmnt1ThrWyCtlystOtltTmpPrl "Used to identify the applicable J1939-73 FMI detected in the Three Way Catalyst outlet temperature sensor by the manufacturer’s sensor control software in exhaust bank 1. When there is no failure FMI 31 is sent. In the case of multiple failures the ...";
CM_ SG_ 2566735614 Aftrtrtmnt1ThrWyCtlystIntkTmpPrl "Used to identify the applicable J1939-73 FMI detected in the Three Way Catalyst intake temperature sensor by the manufacturer’s sensor control software in exhaust bank 1. When there is no failure FMI 31 is sent. In the case of multiple failures the ...";
CM_ SG_ 2566735614 Aftrtrtmnt1ThrWyCtalystDiffPress "Exhaust differential pressure measured between the intake and exhaust of a Three Way Catalyst in exhaust bank 1.";
CM_ SG_ 2566735614 Aftrtrtmnt1ThrWyCtlystOutletTemp "Temperature of engine combustion byproducts leaving the Three Way Catalyst in exhaust bank 1.";
CM_ SG_ 2566735614 Aftrtrtmnt1ThrWyCtlystIntakeTemp "Temperature of engine combustion byproducts entering the Three Way Catalyst in exhaust bank 1.";
CM_ BO_ 2566805246 "Contains information on various tank levels";
CM_ SG_ 2566805246 Aftrtrtmnt1DslExhstFldTnk1HtrPrl "Used to identify the applicable J1939-73 FMI detected in the diesel exhaust fluid tank 1 heater, by the manufacturer’s control software in exhaust bank 1. When there is no failure FMI 31 is sent. In the case of multiple failures the most severe is ...";
CM_ SG_ 2566805246 Aftrtrtmnt1DslExhstFldTankHeater "Percentage of heating applied to the aftertreatment 1 diesel exhaust fluid tank heater.  A value of 0% means no heating applied, a value of 100% means full heating applied.  The diesel exhaust fluid tank heater warms the diesel exhaust fluid in the ...";
CM_ SG_ 2566805246 AftrtrtmntSCROprtrIndcmntSverity "Severity status of the operator inducement system for anomalies with the SCR system, such as tampering, low DEF quality, and DEF tank level.  Higher numerical levels indicate more severe levels of inducement.  Level 1 is the least severe.
000 - ...";
CM_ SG_ 2566805246 Aftrtrtmnt1DslExhstFldTnk1TmpPrl "Used to identify the applicable J1939-73 FMI detected in the diesel exhaust fluid tank 1 temperature, by the manufacturer’s control software in exhaust bank 1. When there is no failure FMI 31 is sent. In the case of multiple failures the most severe ...";
CM_ SG_ 2566805246 AftrtrtmntSlctvCtlytcRdctnOprtrI "The desired illumination of the driver's warning indicator for diesel exhaust fluid (DEF) tank low level.
000 - Off -  indicates adequate DEF level
e.g., for Euro VI this is used to indicate the driver warning system is non-active for diesel ...";
CM_ SG_ 2566805246 Aftrtrtmnt1DslExhstFldTnkLvlPrlm "Used to identify the applicable J1939-73 FMI detected in the diesel exhaust fluid tank level sensor by the manufacturer's sensor control software.  This FMI is applicable to either the diesel exhaust fluid tank level 1 or diesel exhaust fluid tank ...";
CM_ SG_ 2566805246 Aftrtrtmnt1DslExhstFldTankLevel2 "The measure of the diesel exhaust fluid level in the diesel exhaust fluid tank.

Parameter Specific Indicator:
A value of 0xFB indicates conditions are not acceptable for a valid measurement.";
CM_ SG_ 2566805246 Aftrtrtmnt1DslExhstFluidTankTemp "Temperature of the diesel exhaust fluid in the storage tank.";
CM_ SG_ 2566805246 Aftrtrtmnt1DslExhstFlidTankLevel "Ratio of volume of diesel exhaust fluid to the total volume of diesel exhaust fluid storage container. 

0 % = Empty
100% = Full

Parameter Specific Indicator:
A value of 0xFB indicates conditions are not acceptable for a valid measurement.";
CM_ SG_ 2365394686 NOxSnsrATO1SlfdgnosisFinalResult "Self-diagnosis result for NOx sensor ATO1 (Aftertreatment Outlet Bank 1) as a ratio of detected value to reference value defined by supplier.
This result is used to determine if the signal resulting from the self-diagnosis test (as represented as a ...";
CM_ SG_ 2365394686 Aftrtrtmnt1OtltGsNOxSnsrNH3Crrct "Correction of NH3 at the NOx-signal to correct (recalculate) sensor signal on the Engine ECU side.";
CM_ SG_ 2365394686 Aftrtrtmnt1OtltGsNOxSnsrNO2Crrct "Correction of NO2 at the NOx-signal to correct (recalculate) sensor signal on the Engine ECU side.";
CM_ SG_ 2365394686 Aftrtrtmnt1OtltGsNOxSnsrCrrc5035 "Correction of pressure NOx-signal to correct (recalculate) sensor signal on the Engine ECU side.";
CM_ SG_ 2365394686 Aftrtrtmnt1OtltGsNOxSnsrCrrctnOf "Correction of pressure Lambda-signal to correct (recalculate) sensor signal on the Engine ECU side.";
CM_ SG_ 2365394942 NOxSnsrATO1OperationHoursCounter "Counted hours that the NOx-sensor was operated with status \"dewpoint reached\"";
CM_ SG_ 2365394942 Aftrtrtmnt1OtltGsNOxSnsrNwPr5033 "New part deviation NOx_Offset to correct (recalculate) sensor signal on the Engine ECU side.";
CM_ SG_ 2365394942 Aftrtrtmnt1OtltGsNOxSnsrNwPrtDvt "New part deviation NOx_Gain to correct (recalculate) sensor signal on the Engine ECU side.";
CM_ SG_ 2365394942 Aftrtrtmnt1OtltGsNOxSnsrHtrRatio "Heater ratio to determine temperature at sensor tip.";
CM_ SG_ 2365395198 NOxSnsrATI1SlfdgnosisFinalResult "Self-diagnosis result for NOx sensor ATI1 (Aftertreatment Intake Bank 1) as a ratio of detected value to reference value defined by supplier.
This result is used to determine if the signal resulting from the self-diagnosis test (as represented as a ...";
CM_ SG_ 2365395198 Aftrtrtmnt1IntkGsNOxSnsrNH3Crrct "Correction of NH3 at the NOx-signal to correct (recalculate) sensor signal on the Engine ECU side.";
CM_ SG_ 2365395198 Aftrtrtmnt1IntkGsNOxSnsrNO2Crrct "Correction of NO2 at the NOx-signal to correct (recalculate) sensor signal on the Engine ECU side.";
CM_ SG_ 2365395198 Aftrtrtmnt1IntkGsNOxSnsrCrrc5028 "Correction of pressure NOx-signal to correct (recalculate) sensor signal on the Engine ECU side.";
CM_ SG_ 2365395198 Aftrtrtmnt1IntkGsNOxSnsrCrrctnOf "Correction of pressure Lambda-signal to correct (recalculate) sensor signal on the Engine ECU side.";
CM_ SG_ 2365395454 NOxSnsrATI1OperationHoursCounter "Counted hours that the NOx-sensor was operated with status \"dewpoint reached\"";
CM_ SG_ 2365395454 Aftrtrtmnt1IntkGsNOxSnsrNwPr5026 "New part deviation NOx_Offset to correct (recalculate) sensor signal on the Engine ECU side.";
CM_ SG_ 2365395454 Aftrtrtmnt1IntkGsNOxSnsrNwPrtDvt "New part deviation NOx_Gain to correct (recalculate) sensor signal on the Engine ECU side.";
CM_ SG_ 2365395454 Aftrtrtmnt1IntkGsNOxSnsrHtrRatio "Heater ratio to determine temperature at sensor tip.";
CM_ BO_ 2157248254 "The purpose of this PGN is to group the Aftertreatment 1 DPF soot measurement calibration parameters. These values include soot sensor signal mean and standard deviation calibration levels. These calibration levels are associated with Diesel ...";
CM_ SG_ 2157248254 Aftrtrtmnt1DslPrtcltFltrStStndrd "Calibration offset for the soot standard deviation for Aftertreatment 1 Diesel Particulate Filter soot sensor.";
CM_ SG_ 2157248254 Aftrtrtmnt1DslPrtcltFltrStMnClbO "Calibration offset for the soot Mean for Aftertreatment 1 Diesel Particulate Filter soot sensor.";
CM_ BO_ 2566711806 "Operator commands sent via the Armrest Switch Matrices.";
CM_ SG_ 2566711806 Armrest2Switch2 "Status of the second switch located in armrest 2.

00: Off
01: On
10: Reserved
11: Don't care/take no action";
CM_ SG_ 2566711806 Armrest2Switch1 "Status of the first switch located in armrest 2.

00: Off
01: On
10: Reserved
11: Don't care/take no action";
CM_ SG_ 2566711806 Armrest1Switch2 "Status of the second switch located in armrest 1.

00: Off
01: On
10: Reserved
11: Don't care/take no action";
CM_ SG_ 2566711806 Armrest1Switch1 "Status of the first switch located in armrest 1.

00: Off
01: On
10: Reserved
11: Don't care/take no action";
CM_ BO_ 2364549886 "The Angular Rate Information message shall provide a measurement of the vehicle's pitch rate, roll rate, and yaw rate measurements.  The vehicle dynamics measurements in this message shall be according to a Z-Down axis system as referenced in SAE ...";
CM_ SG_ 2364549886 AngularRateMeasurementLatency "The estimated measurement latency of the measurement.
NOTE: This is only the sensor latency and does not include any additional latencies that might exist because of the CAN Bus or overall system implementation. Latency is the time from sensor ...";
CM_ SG_ 2364549886 YawRateExRangeFigureOfMerit "Figure of merit for yaw angle measurement.

00 = Yaw rate fully functional. Data is within sensor specification.
01 = Yaw rate degraded. Data is suspect due to environmental conditions.
10 = Error
11 = Not available";
CM_ SG_ 2364549886 RollRateExRangeFigureOfMerit "Figure of merit for roll rate measurement.

00 = Roll rate fully functional. Data is within sensor specification.
01 = Roll rate degraded. Data is suspect due to environmental conditions.
10 = Error
11 = Not available";
CM_ SG_ 2364549886 PitchRateExRangeFigureOfMerit "Figure of merit for pitch rate measurement.

00 = Pitch rate fully functional. Data is within sensor specification.
01 = Pitch rate degraded. Data is suspect due to environmental conditions.
10 = Error
11 = Not available";
CM_ SG_ 2364549886 YawRateExRange "Yaw rate is the rate-of-change of the yaw angle over time.  A positive yaw rate signal results when the object turns clockwise.  This parameter is defined according to a Z-Down axis system and the sign of the value is in accordance to the right-hand ...";
CM_ SG_ 2364549886 RollRateExRange "Roll rate is the rate-of-change of the roll angle over time.  The roll rate for increasing roll to the right is reported with a positive value. Roll angle is the same for both Z-Down and Z-Up axis systems, since both systems have positive X axis ...";
CM_ SG_ 2364549886 PitchRateExRange "Pitch rate is the rate-of-change of the pitch angle over time, where the pitch angle vector is in the direction of travel of the vehicle. The pitch rate for increasing ascent over time is reported with a positive value. This parameter is defined ...";
CM_ BO_ 2566712318 "This message contains NOx adsorber information for aftertreatment system 2 (or bank 2).";
CM_ SG_ 2566712318 Aftrtrtmnt2NOxAdsrbrDSOxRgnrtnSt "Indicates whether the NOx adsorber desulfation regeneration in the second aftertreatment system is active or inactive

00  Inactive
01  Active
10  Error indicator
11  Not available";
CM_ SG_ 2566712318 Aftrtrtmnt2NOxAdsrbrDNOxRgnrtnSt "Indicates whether the NOx adsorber regeneration in the second aftertreatment system is active or inactive

00  Inactive
01  Active
10  Error indicator
11  Not available";
CM_ BO_ 2566712574 "This message contains NOx adsorber information for aftertreatment system 1 (or bank 1).";
CM_ SG_ 2566712574 Aftrtrtmnt1NOxAdsrbrDSOxRgnrtnSt "Indicates whether the NOx adsorber desulfation regeneration in the first aftertreatment system is active or inactive

00  Inactive
01  Active
10  Error indicator
11  Not available";
CM_ SG_ 2566712574 Aftrtrtmnt1NOxAdsrbrDNOxRgnrtnSt "Indicates whether the NOx adsorber regeneration in the first aftertreatment system is active or inactive

00  Inactive
01  Active
10  Error indicator
11  Not available";
CM_ BO_ 2164078590 "This message contains SCR service information for aftertreatment system 2 (or bank 2).";
CM_ SG_ 2164078590 Aftrtrtmnt2SCRCnvrsionEfficiency "The SCR conversion efficiency percentage.  Calculated as 100 times the catalyst intake NOx minus the catalyst outlet NOx divided by the catalyst intake NOx.  The catalyst conversion efficiency number in itself does not imply emissions compliance or ...";
CM_ SG_ 2164078590 Aftrtrtmnt2SCRCmmnddCtlystDslExh "This parameter transmits the amount of diesel exhaust fluid that the emissions control system has requested to be used, averaged over the past 15 hours of engine operation.
Used to determine whether the SCR system is using an appropriate amount of ...";
CM_ SG_ 2164078590 Aftrtrtmnt2DslExhstFldAvrgCnsmpt "Measured use of diesel exhaust fluid by a Selective Catalytic Reduction system for exhaust emission control, averaged over the previous 15 hours of engine operation.
Used to determine whether the SCR system is using an appropriate amount of diesel ...";
CM_ BO_ 2566731006 "This message contains SCR reagent tank 2 information for aftertreatment system 2 (or bank 2).  The second tank for the aftertreatment system is usually a smaller quick-thaw reagent tank located in series with tank 1.";
CM_ SG_ 2566731006 Aftrtrtmnt2DslExhstFldTnk2HtrPrl "Used to identify the applicable J1939-73 FMI detected in the diesel exhaust fluid tank 2 heater by the manufacturer’s control software in exhaust bank 2. When there is no failure FMI 31 is sent. In the case of multiple failures the most severe is ...";
CM_ SG_ 2566731006 Aftrtrtmnt2DslExhstFldTnk2Heater "The diesel exhaust fluid tank 2 heater percentage for aftertreatment system 1 (exhaust bank 1). 0% is off.  See SPN 5415 for the command for this tank heater.";
CM_ SG_ 2566731006 Aftrtrtmnt2DslExhstFldTnk2TmpPrl "Used to identify the applicable J1939-73 FMI detected in the diesel exhaust fluid tank 2 temperature, by the manufacturer’s control software in exhaust bank 2. When there is no failure FMI 31 is sent. In the case of multiple failures the most severe ...";
CM_ SG_ 2566731006 Aftrtrtmnt2DslExhstFldTnk2LvlPrl "Used to identify the applicable J1939-73 FMI detected in the diesel exhaust fluid tank 2 level, by the manufacturer’s control software in exhaust bank 2. When there is no failure FMI 31 is sent. In the case of multiple failures the most severe is ...";
CM_ SG_ 2566731006 Aftrtrtmnt2DslExhstFldTnk2Level2 "The diesel exhaust fluid tank 2 level height in mm for aftertreatment system 2 (exhaust bank 2).  Tank 2 is used as a quick thaw diesel exhaust fluid tank.";
CM_ SG_ 2566731006 Aftrtrtmnt2DslExhstFlidTank2Temp "The diesel exhaust fluid tank 2 temperature for aftertreatment system 2 (exhaust bank 2).  Tank 2 is used as a quick thaw diesel exhaust fluid tank.";
CM_ SG_ 2566731006 Aftrtrtmnt2DslExhstFldTank2Level "The diesel exhaust fluid tank 2 level percentage for aftertreatment system 2 (exhaust bank 2).  0% is empty and 100% is full.  Tank 2 is used as a quick thaw diesel exhaust fluid tank.";
CM_ BO_ 2566731262 "This message contains SCR reagent tank 1 information for aftertreatment system 2 (or bank 2).  The first tank for the aftertreatment sytem is primary reagent storage tank.";
CM_ SG_ 2566731262 Aftrtrtmnt2DslExhstFldTnk1HtrPrl "Used to identify the applicable J1939-73 FMI detected in the diesel exhaust fluid tank 1 heater, by the manufacturer’s control software in exhaust bank 2. When there is no failure FMI 31 is sent. In the case of multiple failures the most severe is ...";
CM_ SG_ 2566731262 Aftrtrtmnt2DslExhstFldTankHeater "Percentage of heating applied to the aftertreatment 2 diesel exhaust fluid tank heater.  A value of 0% means no heating applied, a value of 100% means full heating applied.  The diesel exhaust fluid tank heater warms the diesel exhaust fluid in the ...";
CM_ SG_ 2566731262 Aftrtrtmnt2DslExhstFldTnk1TmpPrl "Used to identify the applicable J1939-73 FMI detected in the diesel exhaust fluid tank 1 temperature by the manufacturer’s control software in exhaust bank 2.  When there is no failure FMI 31 is sent. In the case of multiple failures the most severe ...";
CM_ SG_ 2566731262 Aftrtrtmnt2DslExhstFldTnkLvlPrlm "Used to identify the applicable J1939-73 FMI detected in the diesel exhaust fluid tank level sensor by the manufacturer's sensor control software.  This FMI is applicable to either the diesel exhaust fluid tank level 1 or diesel exhaust fluid tank ...";
CM_ SG_ 2566731262 Aftrtrtmnt2DslExhstFldTankLevel2 "The measure of the diesel exhaust fluid level in the diesel exhaust fluid tank.

Parameter Specific Indicator:
A value of 0xFB indicates conditions are not acceptable for a valid measurement.";
CM_ SG_ 2566731262 Aftrtrtmnt2DslExhstFluidTankTemp "Temperature of the diesel exhaust fluid in the storage tank.";
CM_ SG_ 2566731262 Aftrtrtmnt2DslExhstFlidTankLevel "Ratio of volume of diesel exhaust fluid to the total volume of diesel exhaust fluid storage container.

0 % = Empty
100% = Full

Parameter Specific Indicator:
A value of 0xFB indicates conditions are not acceptable for a valid measurement.";
CM_ BO_ 2566730750 "This message contains diesel exhaust fluid supply information for aftertreatment system 2 (or bank 2).";
CM_ SG_ 2566730750 Aftrtrtmnt2DslExhstFldTnkDrnVlvC "Commanded percentage of maximum Aftertreatment 2 Diesel Exhaust Fluid Tank Drain Valve opening. 100% means the the drain valve is fully open providing maximum flow of diesel exhaust fluid out of  the diesel exhaust fluid tank.";
CM_ SG_ 2566730750 Aftrtrtmnt2DslExhstFlidPumpState "State of Aftertreatment 2 Diesel Exhaust Fluid dosing pump.

00  pump operational
01  pump error
10  reserved for SAE assignment
11 not available";
CM_ SG_ 2566730750 Aftrtrtmnt2DslExhstFldTnkFllVlvC "Commanded percentage of maximum Aftertreatment 2 Diesel Exhaust Fluid Tank Fill Valve opening. 100% means the fill valve is fully open providing maximum flow of diesel exhaust fluid into the diesel exhaust fluid tank.";
CM_ SG_ 2566730750 Aftrtrtmnt2DslExhstFldRturnValve "Command to the valve which determines whether the diesel exhaust fluid is delivered to the injector or is routed back to the diesel exhaust fluid tank. Zero directs all diesel exhaust fluid flow  to the injector, 100% sends all diesel exhaust fluid ...";
CM_ SG_ 2566730750 Aftrtrtmnt2DslExhstFldPmpDrvPrcn "The percent (command) sent to the motor to control the speed of  the diesel exhaust fluid pump.";
CM_ SG_ 2566730750 Aftrtrtmnt2DslExhstFldPmpMtrSped "Rotational speed of the motor driving a pump for diesel exhaust fluid used in an aftertreatment system.";
CM_ BO_ 2566731518 "Sensor Information which measures temperature, concentration, and conductivity of the diesel exhaust fluid of the aftertreatment 2 system.";
CM_ SG_ 2566731518 Aftrtrtmnt2DeselExhaustFluidType "This parameter indicates the property of the fluid compound in the tank.  A value of 0011 indicates uncontaminated Diesel Exhaust Fluid.
0000 - Urea concentration too high
0001 - Urea concentration too low
0010 - Fluid is diesel
0011 - Diesel ...";
CM_ SG_ 2566731518 Aftrtrtmnt2DslExhstFldPrprtsPrlm "Used to identify the applicable J1939-73 FMI that applies to the most significant failure of the diesel exhaust fluid properties sensor.  This may be used for indicating failures of the diesel exhaust fluid concentration, diesel exhaust fluid ...";
CM_ SG_ 2566731518 Aftrtrtmnt2DslExhstFldTmp2Prlmnr "Used to identify the applicable J1939-73 FMI that applies to the most significant failure of the diesel exhaust fluid temperature sensor.  When there is no failure FMI 31 is sent. In the case of multiple failures the most severe is communicated.";
CM_ SG_ 2566731518 Aftrtrtmnt2DslExhstFldCndctivity "A measure of the conductivity of the diesel exhaust fluid at the sensor.  The conductivity is an indication of the diesel exhaust fluid's chemical make up.";
CM_ SG_ 2566731518 Aftrtrtmnt2DslExhstFldCncntrtion "A measure of the concentration of urea in water.  Zero percent means that the tank contains no urea.  A 32.5% value indicates that the reagent is of the proper concentration.  The 32.5% value indicates that the concentration is highest quality.
 ...";
CM_ SG_ 2566731518 Aftrtrtmnt2DselExhaustFluidTemp2 "Temperature of the diesel exhaust fluid at the device measuring diesel exhaust fluid quality";
CM_ BO_ 2566732030 "This message contains SCR catalyst intake and outlet exhaust gas temperature information for aftertreatment system 2 (or bank 2).";
CM_ SG_ 2566732030 Aftrtrtmnt2SCRCtlystOtltGsTmpPrl "Used to identify the applicable J1939-73 FMI detected in the SCR outlet temperature sensor by the manufacturer’s sensor control software in exhaust bank 2. When there is no failure FMI 31 is sent. In the case of multiple failures the most severe is ...";
CM_ SG_ 2566732030 Aftrtrtmnt2SCRCtlystOtletGasTemp "Temperature of engine combustion byproducts leaving the SCR exhaust in exhaust bank 2.";
CM_ SG_ 2566732030 Aftrtrtmnt2SCRCtlystIntkGsTmpPrl "Used to identify the applicable J1939-73 FMI detected in the SCR intake temperature sensor by the manufacturer’s sensor control software in exhaust bank 2. When there is no failure FMI 31 is sent. In the case of multiple failures the most severe is ...";
CM_ SG_ 2566732030 Aftrtrtmnt2SCRCtlystIntkeGasTemp "Temperature of engine combustion byproducts entering the SCR in exhaust bank 2.";
CM_ BO_ 2566732286 "This message contains SCR catalyst exhaust gas pressure information for aftertreatment system 2 (or bank 2).";
CM_ SG_ 2566732286 Aftertreatment2SCRIntakePress "The gage pressure at the intake of the selective catalytic reduction system of Aftertreatment 2.";
CM_ SG_ 2566732286 Aftrtrtmnt2SCRExhstGsDffPrssPrlm "Used to identify the applicable J1939-73 FMI detected in the SCR differential pressure sensor by the manufacturer’s sensor control software in exhaust bank 2. When there is no failure FMI 31 is sent. In the case of multiple failures the most severe ...";
CM_ SG_ 2566732286 Aftrtrtmnt2SCRExhustGasDiffPress "Differential pressure measured between the intake and exhaust of an SCR component in exhaust bank 2.";
CM_ BO_ 2164079358 "This message contains SCR dosing system request information for aftertreatment system 2 (or bank 2).";
CM_ SG_ 2164079358 Aftrtrtmnt2DslExhstFldTnk2HtrCmd "This is the command for the Aftertreatment 2 Diesel Exhaust Fluid Tank 2 Heater.  See SPN 4438 for the measured value of the Aftertreatment 2 Diesel Exhaust Fluid Tank 2 Heater.";
CM_ SG_ 2164079358 Aftrtrtmnt2DslExhstFldTnkHterCmd "Command for the Aftertreatment 2 Diesel Exhaust Fluid Tank Heater.  A value of 0% means no heating applied, a value of 100% means full heating applied.  See SPN 4431 for the measured value of the Aftertreatment 2 Diesel Exhaust Fluid Tank Heater.";
CM_ SG_ 2164079358 Aftrtrtmnt2DslExhstFldLneHeater4 "The diesel exhaust fluid line heater 4 request for aftertreatment system 2 (exhaust bank 2). 
 
00 request for heater to be inactive 
01 request for heater to be active 
10 reserved for future assignment by SAE 
11 not available";
CM_ SG_ 2164079358 Aftrtrtmnt2DslExhstFldLneHeater3 "The diesel exhaust fluid line heater 3 request for aftertreatment system 2 (exhaust bank 2). 

00 request for heater to be inactive 
01 request for heater to be active 
10 reserved for future assignment by SAE 
11 not available";
CM_ SG_ 2164079358 Aftrtrtmnt2DslExhstFldLneHeater2 "The diesel exhaust fluid line heater 2 request for aftertreatment system 2 (exhaust bank 2). 

00 request for heater to be inactive 
01 request for heater to be active 
10 reserved for future assignment by SAE 
11 not available";
CM_ SG_ 2164079358 Aftrtrtmnt2DslExhstFldLneHeater1 "The diesel exhaust fluid line heater 1 request for aftertreatment system 2 (exhaust bank 2). 

00 request for heater to be inactive 
01 request for heater to be active 
10 reserved for future assignment by SAE 
11 not available";
CM_ SG_ 2164079358 Aftrtrtmnt2DslExhstFldDsrHtngMdR "Used if multiple heater modes are available in the Doser.

000   Heater off
001   Heater economy mode
010   Heater automatic mode
011   Heater on
100 - 110    Reserved
111   Not available";
CM_ SG_ 2164079358 Aftrtrtmnt2DslExhstFldDsrFltSppr "Used if external devices can warn of conditions that require suppression of potential faults in the doser due to environmental conditions.

00    Error suppression off
01    Error suppression on
10    Reserved
11    Not available";
CM_ BO_ 2364549118 "This message contains SCR dosing system request information for aftertreatment system 2 (or bank 2).";
CM_ SG_ 2364549118 Aftrtrtmnt2DslExhstFldRqstdQntty "Represents the command for the diesel exhaust fluid quantity integrator in the dosing control unit";
CM_ SG_ 2364549118 Aftrtrtmnt2DslExhstFldDsngRq6594 "Requested dosing quantity of diesel exhaust fluid. This SPN is a high range measurement. See SPN 4401 if high range is not needed.";
CM_ SG_ 2364549118 Aftrtrtmnt2SCRSystmRquestedState "Requested state of SCR system for aftertreatment system 2 (exhaust bank 2).
0000 Dormant (sleep mode)
0001 Preparing dosing readiness (wake up; prepare to operate; wait for start)
0010 Normal dosing operation
0011 System error pending
0100 ...";
CM_ SG_ 2364549118 Aftrtrtmnt2DslExhstFldDsngRqstdQ "Actual requested dosing quantity of diesel exhaust fluid.";
CM_ BO_ 2566732798 "This message contains SCR dosing system information for aftertreatment system 2 (or bank 2).  See PGN 61478 for more information.";
CM_ SG_ 2566732798 Aftrtrtmnt2DslExhstFldLnHtr4Prlm "Used to identify the applicable J1939-73 FMI detected in the diesel exhaust fluid line heater 4, by the manufacturer’s control software in exhaust bank 2. When there is no failure FMI 31 is sent. In the case of multiple failures the most severe is ...";
CM_ SG_ 2566732798 Aftrtrtmnt2DslExhstFldLnHtr4Stte "The diesel exhaust fluid line heater 4 state for aftertreatment system 2 (exhaust bank 2).

00 heater inactive 
01 heater active 
10 error 
11 not available";
CM_ SG_ 2566732798 Aftrtrtmnt2DslExhstFldLnHtr3Prlm "Used to identify the applicable J1939-73 FMI detected in the diesel exhaust fluid line heater 3, by the manufacturer’s control software in exhaust bank 2. When there is no failure FMI 31 is sent. In the case of multiple failures the most severe is ...";
CM_ SG_ 2566732798 Aftrtrtmnt2DslExhstFldLnHtr3Stte "The diesel exhaust fluid line heater 3 state for aftertreatment system 2 (exhaust bank 2).

00 heater inactive 
01 heater active 
10 error 
11 not available";
CM_ SG_ 2566732798 Aftrtrtmnt2DslExhstFldLnHtr2Prlm "Used to identify the applicable J1939-73 FMI detected in the diesel exhaust fluid line heater 2, by the manufacturer’s control software in exhaust bank 2. When there is no failure FMI 31 is sent. In the case of multiple failures the most severe is ...";
CM_ SG_ 2566732798 Aftrtrtmnt2DslExhstFldLnHtr2Stte "The diesel exhaust fluid line heater 2 state for aftertreatment system 2 (exhaust bank 2).

00 heater inactive 
01 heater active 
10 error 
11 not available";
CM_ SG_ 2566732798 Aftrtrtmnt2DslExhstFldLnHtr1Prlm "Used to identify the applicable J1939-73 FMI detected in the diesel exhaust fluid line heater 1, by the manufacturer’s control software in exhaust bank 2. When there is no failure FMI 31 is sent. In the case of multiple failures the most severe is ...";
CM_ SG_ 2566732798 Aftrtrtmnt2DslExhstFldLnHtr1Stte "The diesel exhaust fluid line heater 1 state for aftertreatment system 2 (exhaust bank 2).

00 heater inactive 
01 heater active 
10 error 
11 not available";
CM_ SG_ 2566732798 Aftrtrtmnt2SCRFeedbackCtrlStatus "The SCR feedback control status (open/closed loop) for aftertreatment system 2 (exhaust bank 2).
000 open loop control active
001 closed loop control active
010 reserved for future assignment by SAE
011 reserved for future assignment by SAE
100 ...";
CM_ SG_ 2566732798 Aftrtrtmnt2SCRDsngVlvExhstTmpRdc "Protection request for the dosing valve of the SCR-system to prevent overheating
000:    no request
001:    reduction request stage 1
010:    reduction request stage 2
011:    reserved for future assignment by SAE
100:    reserved for future ...";
CM_ SG_ 2566732798 Aftrtrtmnt2DslExhstFldDosingTemp "The diesel exhaust fluid dosing temperature (measured closest to dosing valve) for aftertreatment system 2 (exhaust bank 2).";
CM_ SG_ 2566732798 Aftrtrtmnt2SCRDsngAirAssistValve "The position of the valve used to regulate the air supply of an air assist SCR dosing system for an engine. 0% represents no supply and 100% is full supply.";
CM_ SG_ 2566732798 Aftrtrtmnt2SCRDsngArAssstAbsPrss "The SCR dosing system air assist absolute pressure for aftertreatment system 2 (exhaust bank 2).  The air assist system is used to improve the dosed reagent atomization.";
CM_ BO_ 2364548862 "This message contains SCR dosing system information for aftertreatment system 2 (or bank 2).  See PGN 64827 for more information.";
CM_ SG_ 2364548862 Aftrtrtmnt2DslExhstFldActlDs6596 "Actual dosing quantity of diesel exhaust fluid. See SPN 4384 if high range measurement is not needed.";
CM_ SG_ 2364548862 Aftrtrtmnt2DslExhstFldDsngAbsPrs "The SCR dosing diesel exhaust fluid absolute pressure (measured closest to dosing valve) for aftertreatment system 2 (exhaust bank 2).";
CM_ SG_ 2364548862 Aftrtrtmnt2DslExhstFldActlQnttyO "The SCR requested diesel exhaust fluid integrator total quantity for aftertreatment system 2 (exhaust bank 2).";
CM_ SG_ 2364548862 Aftertreatment2SCRSystemState "Actual state of SCR system
0000    Dormant (sleep mode)
0001    Preparing dosing readiness (wake up; prepare to operate; wait for start)
0010    Normal dosing operation
0011    System error pending
0100    Reserved for future assignment by SAE
 ...";
CM_ SG_ 2364548862 Aftrtrtmnt2DslExhstFldActlDsngQn "Actual reducing agent quantity of SCR system.";
CM_ BO_ 2364549374 "This message contains outlet ammonia information for aftertreatment system 2 (or bank 2).";
CM_ SG_ 2364549374 Aftrtrtmnt2OtltNH3GsSnsrHterCtrl "Indicates the heater status in the warm-up process. Upon receiving a power-up command, the NH3 gas sensor ramps up according to a manufacturer defined profile. The Preheat 1, Preheat 2, and Automatic messages are regions within this profile in ...";
CM_ SG_ 2364549374 Aftrtrtmnt2OtltNH3GsSnsrHtrPrlmn "Used to identify the applicable J1939-73 FMI detected in the heater of the outlet NH3 exhaust gas sensor by the manufacturer’s sensor control software in exhaust bank 2. When there is no failure FMI 31 is sent. In the case of multiple failures the ...";
CM_ SG_ 2364549374 Aftrtrtmnt2OtltNH3GsSensorAtTemp "Indicates that the heater element of the aftertreatment outlet NH3 gas sensor is within the manufacturer’s specified range for accurate measurements in exhaust bank 2.
00 - Heater element is not in range
01 - Heater element is in range
10 - Error
 ...";
CM_ SG_ 2364549374 Aftrtrtmnt2OtltNH3GsSnsrPwrInRng "Indicates that the power supplied to the aftertreatment outlet NH3 gas sensor is within the manufacturer’s specification in exhaust bank 2.

00 - Heater element is not in range
01 - Heater element is in range
10 - Error
11 - Not available";
CM_ SG_ 2364549374 Aftrtrtmnt2OtletNH3ReadingStable "Indicates that the NH3 reading of the aftertreatment outlet NH3 sensor is stable as determined by the manufacturer’s control software in exhaust bank 2.

00 - Reading is not stable
01 - Reading is stable
10 - Error
11 - Not available";
CM_ SG_ 2364549374 Aftrtrtmnt2OtltNH3SnsrPrlmnryFMI "Used to identify the applicable J1939-73 FMI detected in the aftertreatment outlet NH3 sensor by the manufacturer’s sensor control software in exhaust bank 2. When there is no failure FMI 31 is sent. In the case of multiple failures the most severe ...";
CM_ SG_ 2364549374 Aftertreatment2OutletNH3 "The amount of NH3 in the exhaust exiting the aftertreatment system measured by a NH3 sensor at the aftertreatment outlet, represented in NH3 molecule parts per million non-NH3 molecules in exhaust bank 2.";
CM_ BO_ 2566726142 "The purpose of this PGN is to group the aftertreatment gas oxidation catalyst data for bank 2. These values include the intake temperature, outlet temperature and differential pressure as well as the associated preliminary FMIs.  The gas parameters ...";
CM_ SG_ 2566726142 Aftrtrtmnt2GsOxdtnCtlystDffPrssP "Used to identify the applicable J1939-73 FMI detected in the gas oxidation catalyst differential pressure sensor by the manufacturer’s sensor control software in exhaust bank 2. When there is no failure FMI 31 is sent. In the case of multiple ...";
CM_ SG_ 2566726142 Aftrtrtmnt2GsOxdtnCtlystOtlt4763 "Used to identify the applicable J1939-73 FMI detected in the gas oxidation catalyst outlet gas temperature sensor by the manufacturer’s sensor control software in exhaust bank 2. When there is no failure FMI 31 is sent. In the case of multiple ...";
CM_ SG_ 2566726142 Aftrtrtmnt2GsOxdtnCtlystIntk4762 "Used to identify the applicable J1939-73 FMI detected in the gas oxidation catalyst intake gas temperature sensor by the manufacturer’s sensor control software in exhaust bank 2. When there is no failure FMI 31 is sent. In the case of multiple ...";
CM_ SG_ 2566726142 Aftrtrtmnt2GsOxdtnCtlystDffPress "Exhaust differential pressure measured between the intake and exhaust of the gas oxidation catalyst in exhaust bank 2.  This parameter should be used with engines fueled by gaseous fuel like natural gas or propane.  A separate parameter has been ...";
CM_ SG_ 2566726142 Aftrtrtmnt2GsOxdtnCtlystOtltGsTm "Temperature of engine combustion byproducts leaving the gas oxidation catalyst in exhaust bank 2.  This parameter should be used with engines fueled by gaseous fuel like natural gas or propane.  A separate parameter has been defined for diesel ...";
CM_ SG_ 2566726142 Aftrtrtmnt2GsOxdtnCtlystIntkGsTm "Temperature of engine combustion byproducts entering the gas oxidation catalyst in exhaust bank 2.  This parameter should be used with engines fueled by gaseous fuel like natural gas or propane.  A separate parameter has been defined for diesel ...";
CM_ BO_ 2566725630 "The purpose of this PGN is to group the aftertreatment diesel oxidation catalyst data for bank 2. These values include the intake temperature, outlet temperature and differential pressure as well as the associated preliminary FMIs.  The diesel ...";
CM_ SG_ 2566725630 Aftrtrtmnt2DslOxdtnCtlystDff4776 "Used to identify the applicable J1939-73 FMI detected in the diesel oxidation catalyst differential pressure sensor by the manufacturer’s sensor control software in exhaust bank 2. When there is no failure FMI 31 is sent. In the case of multiple ...";
CM_ SG_ 2566725630 Aftrtrtmnt2DslOxdtnCtlystOtl4775 "Used to identify the applicable J1939-73 FMI detected in the diesel oxidation catalyst outlet gas temperature sensor by the manufacturer’s sensor control software in exhaust bank 2. When there is no failure FMI 31 is sent. In the case of multiple ...";
CM_ SG_ 2566725630 Aftrtrtmnt2DslOxdtnCtlystInt4774 "Used to identify the applicable J1939-73 FMI detected in the diesel oxidation catalyst intake temperature sensor by the manufacturer’s sensor control software in exhaust bank 2. When there is no failure FMI 31 is sent. In the case of multiple ...";
CM_ SG_ 2566725630 Aftrtrtmnt2DslOxdtnCtlystDffPrss "Exhaust differential pressure measured between the intake and exhaust of a diesel oxidation catalyst in exhaust bank 2.  This parameter should be used with engines fueled by diesel fuel (not gaseous fuel like natural gas or propane).  A separate ...";
CM_ SG_ 2566725630 Aftrtrtmnt2DslOxdtnCtlystOtltGsT "Temperature of engine combustion byproducts leaving the diesel oxidation catalyst exhaust in exhaust bank 2.  This parameter should be used with engines fueled by diesel fuel (not gaseous fuel like natural gas or propane).  A separate parameter has ...";
CM_ SG_ 2566725630 Aftrtrtmnt2DslOxdtnCtlystIntkGsT "Temperature of engine combustion byproducts entering the diesel oxidation catalyst in exhaust bank 2.  This parameter should be used with engines fueled by diesel fuel (not gaseous fuel like natural gas or propane).  A separate parameter has been ...";
CM_ BO_ 2566733310 "This message contains SCR reagent tank 2 information for aftertreatment system 1 (or bank 1).  The second tank for the aftertreatment system is usually a smaller quick-thaw reagent tank located in series with tank 1.";
CM_ SG_ 2566733310 Aftrtrtmnt1DslExhstFldTnk2HtrPrl "Used to identify the applicable J1939-73 FMI detected in the diesel exhaust fluid tank 2 heater, by the manufacturer’s control software in exhaust bank 1. When there is no failure FMI 31 is sent. In the case of multiple failures the most severe is ...";
CM_ SG_ 2566733310 Aftrtrtmnt1DslExhstFldTnk2Heater "The diesel exhaust fluid tank 2 heater percentage for aftertreatment system 1 (exhaust bank 1).  0% is off.  See SPN 5414 for the command for this tank heater.";
CM_ SG_ 2566733310 Aftrtrtmnt1DslExhstFldTnk2TmpPrl "Used to identify the applicable J1939-73 FMI detected in the diesel exhaust fluid tank 2 temperature, by the manufacturer’s control software in exhaust bank 1. When there is no failure FMI 31 is sent. In the case of multiple failures the most severe ...";
CM_ SG_ 2566733310 Aftrtrtmnt1DslExhstFldTnk2LvlPrl "Used to identify the applicable J1939-73 FMI detected in the diesel exhaust fluid tank 2 level, by the manufacturer’s control software in exhaust bank 1. When there is no failure FMI 31 is sent. In the case of multiple failures the most severe is ...";
CM_ SG_ 2566733310 Aftrtrtmnt1DslExhstFldTnk2Level2 "The diesel exhaust fluid tank 2 level height in mm for aftertreatment system 1 (exhaust bank 1).  Tank 2 is used as a quick thaw diesel exhaust fluid tank.";
CM_ SG_ 2566733310 Aftrtrtmnt1DslExhstFlidTank2Temp "The diesel exhaust fluid tank 2 temperature for aftertreatment system 1 (exhaust bank 1).  Tank 2 is used as a quick thaw diesel exhaust fluid tank.";
CM_ SG_ 2566733310 Aftrtrtmnt1DslExhstFldTank2Level "The diesel exhaust fluid tank 2 level percentage for aftertreatment system 1 (exhaust bank 1).  0% is empty and 100% is full.  Tank 2 is used as a quick thaw diesel exhaust fluid tank.";
CM_ BO_ 2566733054 "This message contains diesel exhaust fluid supply information for aftertreatment system 1 (or bank 1).";
CM_ SG_ 2566733054 Aftrtrtmnt1DslExhstFldTnkDrnVlvC "Commanded percentage of maximum Aftertreatment 1 Diesel Exhaust Fluid Tank Drain Valve opening. 100% means the drain valve is fully open providing maximum flow of diesel exhaust fluid out of the diesel exhaust fluid tank.";
CM_ SG_ 2566733054 Aftrtrtmnt1DslExhstFlidPumpState "State of Aftertreatment 1 Diesel Exhaust Fluid dosing pump.

00  pump operational
01  pump error
10  reserved for SAE assignment
11 not available";
CM_ SG_ 2566733054 Aftrtrtmnt1DslExhstFldTnkFllVlvC "Commanded percentage of maximum Aftertreatment 1 Diesel Exhaust Fluid Tank Fill Valve opening. 100% means the fill valve is fully open providing maximum flow of diesel exhaust fluid into the diesel exhaust fluid tank.";
CM_ SG_ 2566733054 Aftrtrtmnt1DslExhstFldRturnValve "Command to the valve which determines whether the diesel exhaust fluid is delivered to the injector or is routed back to the diesel exhaust fluid tank. Zero directs all diesel exhaust fluid flow  to the injector, 100% sends all diesel exhaust fluid ...";
CM_ SG_ 2566733054 Aftrtrtmnt1DslExhstFldPmpDrvPrcn "The percent (command) sent to the motor to control the speed of the diesel exhaust fluid pump.";
CM_ SG_ 2566733054 Aftrtrtmnt1DslExhstFldPmpMtrSped "Rotational speed of the motor driving a pump for diesel exhaust fluid used in an aftertreatment system.";
CM_ BO_ 2499624702 "This message contains SCR catalyst intake and outlet exhaust gas temperature information for aftertreatment system 1 (or bank 1).";
CM_ SG_ 2499624702 Aftrtrtmnt1SCRCtlystOtltGsTmpPrl "Used to identify the applicable J1939-73 FMI detected in the SCR outlet temperature sensor by the manufacturer’s sensor control software in exhaust bank 1. When there is no failure FMI 31 is sent. In the case of multiple failures the most severe is ...";
CM_ SG_ 2499624702 Aftrtrtmnt1SCRCtlystOtletGasTemp "Temperature of engine combustion byproducts leaving the SCR outlet in exhaust bank 1.";
CM_ SG_ 2499624702 Aftrtrtmnt1SCRCtlystIntkGsTmpPrl "Used to identify the applicable J1939-73 FMI detected in the SCR intake temperature sensor by the manufacturer’s sensor control software in exhaust bank 1. When there is no failure FMI 31 is sent. In the case of multiple failures the most severe is ...";
CM_ SG_ 2499624702 Aftrtrtmnt1SCRCtlystIntkeGasTemp "Temperature of engine combustion byproducts entering the SCR in exhaust bank 1.";
CM_ BO_ 2566733822 "This message contains SCR catalyst exhaust gas pressure information for aftertreatment system 1 (or bank 1).";
CM_ SG_ 2566733822 Aftertreatment1SCRIntakePress "The gage pressure at the intake of the selective catalytic reduction system of Aftertreatment 1.";
CM_ SG_ 2566733822 Aftrtrtmnt1SCRExhstGsDffPrssPrlm "Used to identify the applicable J1939-73 FMI detected in the SCR differential pressure sensor by the manufacturer’s sensor control software in exhaust bank 1. When there is no failure FMI 31 is sent. In the case of multiple failures the most severe ...";
CM_ SG_ 2566733822 Aftrtrtmnt1SCRExhustGasDiffPress "Differential pressure measured between the intake and outlet of an SCR component in exhaust bank 1.";
CM_ BO_ 2566734078 "This message contains SCR dosing system request information for aftertreatment system 1 (or bank 1).  See PGN 61476 for more information.";
CM_ SG_ 2566734078 Aftrtrtmnt1DslExhstFldPmpHterCmd "Command for the Aftertreatment 1 Diesel Exhaust Fluid Pump Heater. A value of 0% means no heating commanded, a value of 100% means full heating commanded. See SPN 5706 for the measured value of the Aftertreatment 1 Diesel Exhaust Fluid Heater.";
CM_ SG_ 2566734078 Aftrtrtmnt1DslExhstFldTnk2HtrCmd "This is the command for the Aftertreatment 1 Diesel Exhaust Fluid Tank 2 Heater.  See SPN 4372 for the measured value of the Aftertreatment 1 Diesel Exhaust Fluid Tank 2 Heater.";
CM_ SG_ 2566734078 Aftrtrtmnt1DslExhstFldTnkHterCmd "Command for the Aftertreatment 1 Diesel Exhaust Fluid Tank Heater.  A value of 0% means no heating applied, a value of 100% means full heating applied.  See SPN 3363 for the measured value of the Aftertreatment 1 Diesel Exhaust Fluid Tank Heater.";
CM_ SG_ 2566734078 Aftrtrtmnt1DslExhstFldLneHeater4 "The diesel exhaust fluid line heater 4 request for aftertreatment system 1 (exhaust bank 1).
 
00 request for heater to be inactive 
01 request for heater to be active 
10 reserved for future assignment by SAE 
11 not available";
CM_ SG_ 2566734078 Aftrtrtmnt1DslExhstFldLneHeater3 "The diesel exhaust fluid line heater 3 request for aftertreatment system 1 (exhaust bank 1).
 
00 request for heater to be inactive 
01 request for heater to be active 
10 reserved for future assignment by SAE 
11 not available";
CM_ SG_ 2566734078 Aftrtrtmnt1DslExhstFldLneHeater2 "The diesel exhaust fluid line heater 2 request for aftertreatment system 1 (exhaust bank 1).
 
00 request for heater to be inactive 
01 request for heater to be active 
10 reserved for future assignment by SAE 
11 not available";
CM_ SG_ 2566734078 Aftrtrtmnt1DslExhstFldLneHeater1 "The diesel exhaust fluid line heater 1 request for aftertreatment system 1 (exhaust bank 1).
 
00 request for heater to be inactive 
01 request for heater to be active 
10 reserved for future assignment by SAE 
11 not available";
CM_ SG_ 2566734078 Aftrtrtmnt1DslExhstFldDsrHtngMdR "Used if multiple heater modes are available in the Doser.

000   Heater off
001   Heater economy mode
010   Heater automatic mode
011   Heater on
100 - 110    Reserved
111   Not available";
CM_ SG_ 2566734078 Aftrtrtmnt1DslExhstFldDsrFltSppr "Used if external devices can warn of conditions that require suppression of potential faults in the doser due to environmental conditions.

00    Error suppression off
01    Error suppression on
10    Reserved
11    Not available";
CM_ BO_ 2364548350 "This message contains SCR dosing system request information for aftertreatment system 1 (or bank 1).  See PGN 64832 for more information.";
CM_ SG_ 2364548350 Aftrtrtmnt1DslExhstFldDsngRq6593 "Requested dosing quantity of diesel exhaust fluid. This SPN is a high range measurement. See SPN 4348 if high range is not needed.";
CM_ SG_ 2364548350 Aftrtrtmnt1DslExhstFldRqstdQntty "Represents the command for the diesel exhaust fluid quantity integrator in the dosing control unit";
CM_ SG_ 2364548350 Aftrtrtmnt1SCRSystmRquestedState "Requested state of SCR system for aftertreatment system 1 (exhaust bank 1).
0000 Dormant (sleep mode)
0001 Preparing dosing readiness (wake up; prepare to operate; wait for start)
0010 Normal dosing operation
0011 System error pending
0100 ...";
CM_ SG_ 2364548350 Aftrtrtmnt1DslExhstFldDsngRqstdQ "Actual requested dosing quantity of diesel exhaust fluid.";
CM_ BO_ 2566734334 "This message contains SCR dosing system information for aftertreatment system 1 (or bank 1).  See PGN 61475 for more information.";
CM_ SG_ 2566734334 Aftrtrtmnt1DslExhstFldLnHtr4Prlm "Used to identify the applicable J1939-73 FMI detected in the diesel exhaust fluid line heater 4, by the manufacturer’s control software in exhaust bank 1. When there is no failure FMI 31 is sent. In the case of multiple failures the most severe is ...";
CM_ SG_ 2566734334 Aftrtrtmnt1DslExhstFldLnHtr4Stte "The diesel exhaust fluid line heater 4 state for aftertreatment system 1 (exhaust bank 1). 

00 heater inactive 
01 heater active 
10 error 
11 not available";
CM_ SG_ 2566734334 Aftrtrtmnt1DslExhstFldLnHtr3Prlm "Used to identify the applicable J1939-73 FMI detected in the diesel exhaust fluid line heater 3, by the manufacturer’s control software in exhaust bank 1. When there is no failure FMI 31 is sent. In the case of multiple failures the most severe is ...";
CM_ SG_ 2566734334 Aftrtrtmnt1DslExhstFldLnHtr3Stte "The diesel exhaust fluid line heater 3 state for aftertreatment system 1 (exhaust bank 1). 

00 heater inactive 
01 heater active 
10 error 
11 not available";
CM_ SG_ 2566734334 Aftrtrtmnt1DslExhstFldLnHtr2Prlm "Used to identify the applicable J1939-73 FMI detected in the diesel exhaust fluid line heater 2, by the manufacturer’s control software in exhaust bank 1. When there is no failure FMI 31 is sent. In the case of multiple failures the most severe is ...";
CM_ SG_ 2566734334 Aftrtrtmnt1DslExhstFldLnHtr2Stte "The diesel exhaust fluid line heater 2 state for aftertreatment system 1 (exhaust bank 1). 
 
00 heater inactive 
01 heater active 
10 error 
11 not available";
CM_ SG_ 2566734334 Aftrtrtmnt1DslExhstFldLnHtr1Prlm "Used to identify the applicable J1939-73 FMI detected in the diesel exhaust fluid line heater 1, by the manufacturer’s control software in exhaust bank 1. When there is no failure FMI 31 is sent. In the case of multiple failures the most severe is ...";
CM_ SG_ 2566734334 Aftrtrtmnt1DslExhstFldLnHtr1Stte "The diesel exhaust fluid line heater 1 state for aftertreatment system 1 (exhaust bank 1). 

00 heater inactive 
01 heater active 
10 error 
11 not available";
CM_ SG_ 2566734334 Aftrtrtmnt1SCRFeedbackCtrlStatus "The SCR feedback control status (open/closed loop) for aftertreatment system 1 (exhaust bank 1).
000 open loop control active
001 closed loop control active
010 reserved for future assignment by SAE
011 reserved for future assignment by SAE
100 ...";
CM_ SG_ 2566734334 Aftrtrtmnt1SCRDsngVlvExhstTmpRdc "Protection request for the dosing valve of the SCR-system to prevent overheating
000:    no request
001:    reduction request stage 1
010:    reduction request stage 2
011:    reserved for future assignment by SAE
100:    reserved for future ...";
CM_ SG_ 2566734334 Aftrtrtmnt1DslExhstFldDosingTemp "The diesel exhaust fluid dosing temperature (measured closest to dosing valve) for aftertreatment system 1 (exhaust bank 1).";
CM_ SG_ 2566734334 Aftrtrtmnt1SCRDsngAirAssistValve "The position of the valve used to regulate the air supply of an air assist SCR dosing system for an engine. 0% represents no supply and 100% is full supply.";
CM_ SG_ 2566734334 Aftrtrtmnt1SCRDsngArAssstAbsPrss "The SCR dosing system air assist absolute pressure for aftertreatment system 1 (exhaust bank 1).  The air assist system is used to improve the dosed reagent atomization.";
CM_ BO_ 2364548094 "This message contains SCR dosing system information for aftertreatment system 1 (or bank 1).  See PGN 64833 for more information.";
CM_ SG_ 2364548094 Aftrtrtmnt1DslExhstFldDsrAbsPrss "The SCR dosing diesel exhaust fluid absolute pressure (measured closest to dosing valve) for aftertreatment system 1 (exhaust bank 1).";
CM_ SG_ 2364548094 Aftrtrtmnt1DslExhstFldActlDs6595 "Actual dosing quantity of diesel exhaust fluid. See SPN 4331 if high range measurement is not needed.";
CM_ SG_ 2364548094 Aftrtrtmnt1DslExhstFldActlQnttyO "The SCR requested diesel exhaust fluid integrator total quantity for aftertreatment system 1 (exhaust bank 1).";
CM_ SG_ 2364548094 Aftertreatment1SCRSystemState "Actual state of SCR system
0000    Dormant (sleep mode)
0001    Preparing dosing readiness (wake up; prepare to operate; wait for start)
0010    Normal dosing operation
0011    System error pending
0100    Purging (SCR dosing system is removing ...";
CM_ SG_ 2364548094 Aftrtrtmnt1DslExhstFldActlDsngQn "Actual reducing agent quantity of SCR-system";
CM_ BO_ 2364548606 "This message contains aftertreatment outlet ammonia information for aftertreatment system 1 (or bank 1).";
CM_ SG_ 2364548606 Aftrtrtmnt1OtltNH3GsSnsrHterCtrl "Indicates the heater status in the warm-up process. Upon receiving a power-up command, the NH3 gas sensor ramps up according to a manufacturer defined profile. The Preheat 1, Preheat 2, and Automatic messages are regions within this profile in ...";
CM_ SG_ 2364548606 Aftrtrtmnt1OtltNH3GsSnsrHtrPrlmn "Used to identify the applicable J1939-73 FMI detected in the heater of the outlet NH3 exhaust gas sensor by the manufacturer’s sensor control software in exhaust bank 1. When there is no failure FMI 31 is sent. In the case of multiple failures the ...";
CM_ SG_ 2364548606 Aftrtrtmnt1OtltNH3GsSensorAtTemp "Indicates that the heater element of the aftertreatment outlet NH3 gas sensor is within the manufacturer’s specified range for accurate measurements in exhaust bank 1.
00 - Heater element is not in range
01 - Heater element is in range
10 - Error
 ...";
CM_ SG_ 2364548606 Aftrtrtmnt1OtltNH3GsSnsrPwrInRng "Indicates that the power supplied to the aftertreatment outlet NH3 gas sensor is within the manufacturer’s specification in exhaust bank 1.

00 - Power is not in range
01 - Power is in range
10 - Error
11 - Not available";
CM_ SG_ 2364548606 Aftrtrtmnt1OtletNH3ReadingStable "Indicates that the NH3 reading of the aftertreatment outlet NH3 sensor is stable as determined by the manufacturer’s control software in exhaust bank 1.

00 - Reading is not stable
01 - Reading is stable
10 - Error
11 - Not available";
CM_ SG_ 2364548606 Aftrtrtmnt1OtltNH3SnsrPrlmnryFMI "Used to identify the applicable J1939-73 FMI detected in the aftertreatment outlet NH3 sensor by the manufacturer’s sensor control software in exhaust bank 1. When there is no failure FMI 31 is sent. In the case of multiple failures the most severe ...";
CM_ SG_ 2364548606 Aftertreatment1OutletNH3 "The amount of NH3 in the exhaust exiting the aftertreatment system measured by a NH3 sensor at the aftertreatment outlet, represented in NH3 molecule parts per million non-NH3 molecules in exhaust bank 1.";
CM_ BO_ 2566726398 "The purpose of this PGN is to group the aftertreatment gas oxidation catalyst data for bank 1. These values include the intake temperature, outlet temperature and differential pressure as well as the associated preliminary FMIs.  The gas parameters ...";
CM_ SG_ 2566726398 Aftrtrtmnt1GsOxdtnCtlystDffPrssP "Used to identify the applicable J1939-73 FMI detected in the gas oxidation catalyst differential pressure sensor by the manufacturer’s sensor control software in exhaust bank 1. When there is no failure FMI 31 is sent. In the case of multiple ...";
CM_ SG_ 2566726398 Aftrtrtmnt1GsOxdtnCtlystOtlt4757 "Used to identify the applicable J1939-73 FMI detected in the gas oxidation catalyst outlet temperature sensor by the manufacturer’s sensor control software in exhaust bank 1. When there is no failure FMI 31 is sent. In the case of multiple failures ...";
CM_ SG_ 2566726398 Aftrtrtmnt1GsOxdtnCtlystIntk4756 "Used to identify the applicable J1939-73 FMI detected in the gas oxidation catalyst intake temperature sensor by the manufacturer’s sensor control software in exhaust bank 1. When there is no failure FMI 31 is sent. In the case of multiple failures ...";
CM_ SG_ 2566726398 Aftrtrtmnt1GsOxdtnCtlystDffPress "Exhaust differential pressure measured between the intake and exhaust of the gas oxidation catalyst in exhaust bank 1.  This parameter should be used with engines fueled by gaseous fuel like natural gas or propane.  A separate parameter has been ...";
CM_ SG_ 2566726398 Aftrtrtmnt1GsOxdtnCtlystOtltGsTm "Temperature of engine combustion byproducts leaving the gas oxidation catalyst in exhaust bank 1.  This parameter should be used with engines fueled by gaseous fuel like natural gas or propane.  A separate parameter has been defined for diesel ...";
CM_ SG_ 2566726398 Aftrtrtmnt1GsOxdtnCtlystIntkGsTm "Temperature of engine combustion byproducts entering the gas oxidation catalyst in exhaust bank 1.  This parameter should be used with engines fueled by gaseous fuel like natural gas or propane.  A separate parameter has been defined for diesel ...";
CM_ BO_ 2365415678 "HB1C provides the system specific individual B1 failure counters, when supported by the system.";
CM_ SG_ 2365415678 SPN1 "This 19-bit number is used to identify the item for which diagnostics are being reported.";
CM_ SG_ 2365415678 FailureModeIdentifier1 "The FMI defines the type of failure detected in the subsystem identified by an SPN.";
CM_ SG_ 2365415678 FailureSpecificB1Counter "The Failure Specific B1 Counter provides an individual B1 counter";
CM_ SG_ 2365415678 SPN1High "SPN #1 (Conversion Version 4)";
CM_ BO_ 2365415934 "HCMI provides the system specific cumulative.";
CM_ SG_ 2365415934 SysGreatestB1Counter "System Greatest B1 Counter";
CM_ SG_ 2365415934 SysCumulativeContinuousMITime "System Cumulative Continuous MI Time";
CM_ BO_ 2365416190 "HGRD provides a description of the UN/ECE WWH OBD Global Technical Regulation (GTR) to which the sub-system or
component complies.";
CM_ SG_ 2365416190 RegulationDescription "Global Technical Regulation Description";
CM_ BO_ 2365416446 "HRWS reports subsystem (or component) roadworthiness to the VOBD function to aggregate in the HRWV message.";
CM_ SG_ 2365416446 SysIncompleteMonitorCount "System Incomplete Monitor Count";
CM_ SG_ 2365416446 SysMalIndActivationMode "System Malfunction Indicator Status";
CM_ SG_ 2365416446 SysMalIndDisplayStrategy "System Malfunction Indicator Display";
CM_ SG_ 2365416446 SysContinuousMalfunctionInd "System Continuous Malfunction Indicator";
CM_ SG_ 2365416446 SysNonRoadworthyCompCount "System Non-Roadworthy Component Count";
CM_ BO_ 2365416702 "HRWV provides the aggregated roadworthiness from the VOBD (Vehicle On-Board Diagnostics) to a scan tool or similar inquiry device.";
CM_ SG_ 2365416702 VehicleCurrentMIAccumTime "Vehicle current malfunction indicator accumulated time reports the accumulated count (in minutes) that the malfunction indicator lamp (MIL) is activated (on) for the current malfunction indicator (MI) activation (or the last MI activation).";
CM_ SG_ 2365416702 VehicleIncompleteMonitorCount "Vehicle Incomplete Monitor Count";
CM_ SG_ 2365416702 VehicleMalfunctionIndActMode "Vehicle Malfunction Indicator Status ";
CM_ SG_ 2365416702 VehicleMalfunctionIndStrategy "Vehicle Malfunction Indicator Display Strategy ";
CM_ SG_ 2365416702 VehicleContinuousMalfunctionInd "Vehicle Continuous Malfunction Indicator";
CM_ SG_ 2365416702 VehicleNonRoadworthyCompCount "Vehicle Non-Roadworthy Component Count";
CM_ BO_ 2359361278 "The status of engine operating in the NTE control areas for given pollutants, such as NOx and PM.";
CM_ SG_ 2359361278 PMNTEDeficiencyAreaStatus "Status of engine operation within the PM NTE Deficiency Area.";
CM_ SG_ 2359361278 MnfcPMNTECarveOutAreaStatus "Status of engine operation within the manufacturer specific PM NTE  limited testing region.";
CM_ SG_ 2359361278 PMNTEControlAreaStatus "Status of engine operation within the bounded region of the engine’s torque and speed map where emissions must not exceed a specific emission cap for PM under the NTE requirement.";
CM_ SG_ 2359361278 NOxNTEDeficiencyAreaStatus "Status of engine operation within the NOx NTE Deficiency Area.";
CM_ SG_ 2359361278 MnfcNOxNTECarveOutAreaStatus "Status of engine operation within the manufacturer specific NOx NTE limited testing region.";
CM_ SG_ 2359361278 NOxNTEControlAreaStatus "Status of engine operation within the bounded region of the engine’s torque and speed map where emissions must not exceed a specific emission cap for NOx under the NTE requirement.";
CM_ BO_ 2292317950 "The total engine run time while each of the Emission Increasing Auxiliary Emission Control Devices (EI-AECDs) is active.";
CM_ SG_ 2292317950 AECDEngineHours1Timer2 "The total engine running hours recorded in the second timer for the EI-AECD";
CM_ SG_ 2292317950 AECDEngineHours1Timer1 "The total engine running hours recorded in the first timer for the EI-AECD";
CM_ SG_ 2292317950 AECDNumber1 "The manufacturer assigned number for the specific EI-AECD";
CM_ SG_ 2566809342 BatteryMainSwitchHoldState "Parameter indicating whether the battery main switch is held due to an external request or not. The state battery main switch held indicates that the battery main switch is about to switch off.
00 Battery main switch not held
01 Battery main ...";
CM_ BO_ 2365446910 "Used to transfer information about the measured status of the 1st 2 axes and up to 12 buttons of a joystick.  Additional handle information is available in the Expanded Joystick Message.
10-bit position parameters are broadcast over 2 bytes.  The ...";
CM_ SG_ 2365446910 Joystick3XAxisDetentPosStatus "Reports when the current joystick position is in the detent position for that axis of travel.

00 Not in the Detent Position
01 In the Detent Position
10 Error Indicator
11 Not Available";
CM_ SG_ 2365446910 Joystick3Button9PressedStatus "Reports when the joystick button has been pressed.

00 Button not pressed
01 Button pressed
10 Error Indicator
11 Not Available";
CM_ SG_ 2365446910 Joystick3Button10PressedStatus "Reports when the joystick button has been pressed.

00 Button not pressed
01 Button pressed
10 Error Indicator
11 Not Available";
CM_ SG_ 2365446910 Joystick3Button11PressedStatus "Reports when the joystick button has been pressed.

00 Button not pressed
01 Button pressed
10 Error Indicator
11 Not Available";
CM_ SG_ 2365446910 Joystick3Button12PressedStatus "Reports when the joystick button has been pressed.

00 Button not pressed
01 Button pressed
10 Error Indicator
11 Not Available";
CM_ SG_ 2365446910 Joystick3YAxisDetentPosStatus "Reports when the current joystick position is in the detent position for that axis of travel.

00 Not in the Detent Position
01 In the Detent Position
10 Error Indicator
11 Not Available";
CM_ SG_ 2365446910 Joystick3YAxisPos "The position of the joystick in the relative motion of travel from the neutral position.  Position value of 0 is Neutral and position value 1000 (100%) is the end of linear zone.  Value of 1022 indicates an error has occurred.";
CM_ SG_ 2365446910 Jystck3YAxsLvrFrwrdPstvPosStatus "Reports when the current joystick position is on the positive travel side (forward, right, clockwise, up) relative to the neutral position for that axis of travel.
00 Not on Positive side of Neutral
01 On positive side of Neutral
10 Error ...";
CM_ SG_ 2365446910 Jystck3YAxsLvrBckNgtivePosStatus "Reports when the current joystick position is on the negative travel side (back, left, counterclockwise, down) relative to the neutral position for that axis of travel.
00 Not on negative side of Neutral
01 On negative side of Neutral
10 Error ...";
CM_ SG_ 2365446910 Joystick3YAxisNeutralPosStatus "Reports when the current joystick position is in the neutral position for that axis of travel.  The neutral position measurement must be determined from some mechanism other than the axis position measurement device.
00 Not in Neutral Position
01 ...";
CM_ SG_ 2365446910 Joystick3XAxisPos "The position of the joystick in the relative motion of travel from the neutral position.  Position value of 0 is Neutral and position value 1000 (100%) is the end of linear zone.  Value of 1022 indicates an error has occurred.";
CM_ SG_ 2365446910 Jystck3XAxsLvrRghtPstvePosStatus "Reports when the current joystick position is on the positive travel side (forward, right, clockwise, up) relative to the neutral position for that axis of travel.
00 Not on Positive side of Neutral
01 On positive side of Neutral
10 Error ...";
CM_ SG_ 2365446910 Jystck3XAxsLvrLftNgtivePosStatus "Reports when the current joystick position is on the negative travel side (back, left, counterclockwise, down) relative to the neutral position for that axis of travel.
00 Not on negative side of Neutral
01 On negative side of Neutral
10 Error ...";
CM_ SG_ 2365446910 Joystick3XAxisNeutralPosStatus "Reports when the current joystick position is in the neutral position for that axis of travel.  The neutral position measurement must be determined from some mechanism other than the axis position measurement device.
00 Not in Neutral Position
01 ...";
CM_ SG_ 2365446910 Joystick3Button5PressedStatus "Reports when the joystick button has been pressed.

00 Button not pressed
01 Button pressed
10 Error Indicator
11 Not Available";
CM_ SG_ 2365446910 Joystick3Button6PressedStatus "Reports when the joystick button has been pressed.

00 Button not pressed
01 Button pressed
10 Error Indicator
11 Not Available";
CM_ SG_ 2365446910 Joystick3Button7PressedStatus "Reports when the joystick button has been pressed.

00 Button not pressed
01 Button pressed
10 Error Indicator
11 Not Available";
CM_ SG_ 2365446910 Joystick3Button8PressedStatus "Reports when the joystick button has been pressed.

00 Button not pressed
01 Button pressed
10 Error Indicator
11 Not Available";
CM_ SG_ 2365446910 Joystick3Button1PressedStatus "Reports when the joystick button has been pressed.

00 Button not pressed
01 Button pressed
10 Error Indicator
11 Not Available";
CM_ SG_ 2365446910 Joystick3Button2PressedStatus "Reports when the joystick button has been pressed.

00 Button not pressed
01 Button pressed
10 Error Indicator
11 Not Available";
CM_ SG_ 2365446910 Joystick3Button3PressedStatus "Reports when the joystick button has been pressed.

00 Button not pressed
01 Button pressed
10 Error Indicator
11 Not Available";
CM_ SG_ 2365446910 Joystick3Button4PressedStatus "Reports when the joystick button has been pressed.

00 Button not pressed
01 Button pressed
10 Error Indicator
11 Not Available";
CM_ BO_ 2365446398 "Used to transfer information about the measured status of the 1st 2 axes and up to 12 buttons of a joystick.  Additional handle information is available in the Expanded Joystick Message.
10-bit position parameters are broadcast over 2 bytes.  The ...";
CM_ SG_ 2365446398 Joystick2XAxisDetentPosStatus "Reports when the current joystick position is in the detent position for that axis of travel.

00 Not in the Detent Position
01 In the Detent Position
10 Error Indicator
11 Not Available";
CM_ SG_ 2365446398 Joystick2YAxisDetentPosStatus "Reports when the current joystick position is in the detent position for that axis of travel.

00 Not in the Detent Position
01 In the Detent Position
10 Error Indicator
11 Not Available";
CM_ SG_ 2365446398 Joystick2YAxisPos "The position of the joystick in the relative motion of travel from the neutral position.  Position value of 0 is Neutral and position value 1000 (100%) is the end of linear zone.  Value of 1022 indicates an error has occurred.";
CM_ SG_ 2365446398 Jystck2YAxsLvrFrwrdPstvPosStatus "Reports when the current joystick position is on the positive travel side (forward, right, clockwise, up) relative to the neutral position for that axis of travel.
00 Not on Positive side of Neutral
01 On positive side of Neutral
10 Error ...";
CM_ SG_ 2365446398 Jystck2YAxsLvrBckNgtivePosStatus "Reports when the current joystick position is on the negative travel side (back, left, counterclockwise, down) relative to the neutral position for that axis of travel.
00 Not on negative side of Neutral
01 On negative side of Neutral
10 Error ...";
CM_ SG_ 2365446398 Joystick2YAxisNeutralPosStatus "Reports when the current joystick position is in the neutral position for that axis of travel.  The neutral position measurement must be determined from some mechanism other than the axis position measurement device.
00 Not in Neutral Position
01 ...";
CM_ SG_ 2365446398 Joystick2XAxisPos "The position of the joystick in the relative motion of travel from the neutral position.  Position value of 0 is Neutral and position value 1000 (100%) is the end of linear zone.  Value of 1022 indicates an error has occurred.";
CM_ SG_ 2365446398 Jystck2XAxsLvrRghtPstvePosStatus "Reports when the current joystick position is on the positive travel side (forward, right, clockwise, up) relative to the neutral position for that axis of travel.
00 Not on Positive side of Neutral
01 On positive side of Neutral
10 Error ...";
CM_ SG_ 2365446398 Jystck2XAxsLvrLftNgtivePosStatus "Reports when the current joystick position is on the negative travel side (back, left, counterclockwise, down) relative to the neutral position for that axis of travel.
00 Not on negative side of Neutral
01 On negative side of Neutral
10 Error ...";
CM_ SG_ 2365446398 Joystick2XAxisNeutralPosStatus "Reports when the current joystick position is in the neutral position for that axis of travel.  The neutral position measurement must be determined from some mechanism other than the axis position measurement device.
00 Not in Neutral Position
01 ...";
CM_ SG_ 2365446398 Joystick2Button9PressedStatus "Reports when the joystick button has been pressed.

00 Button not pressed
01 Button pressed
10 Error Indicator
11 Not Available";
CM_ SG_ 2365446398 Joystick2Button10PressedStatus "Reports when the joystick button has been pressed.

00 Button not pressed
01 Button pressed
10 Error Indicator
11 Not Available";
CM_ SG_ 2365446398 Joystick2Button11PressedStatus "Reports when the joystick button has been pressed.

00 Button not pressed
01 Button pressed
10 Error Indicator
11 Not Available";
CM_ SG_ 2365446398 Joystick2Button12PressedStatus "Reports when the joystick button has been pressed.

00 Button not pressed
01 Button pressed
10 Error Indicator
11 Not Available";
CM_ SG_ 2365446398 Joystick2Button5PressedStatus "Reports when the joystick button has been pressed.

00 Button not pressed
01 Button pressed
10 Error Indicator
11 Not Available";
CM_ SG_ 2365446398 Joystick2Button6PressedStatus "Reports when the joystick button has been pressed.

00 Button not pressed
01 Button pressed
10 Error Indicator
11 Not Available";
CM_ SG_ 2365446398 Joystick2Button7PressedStatus "Reports when the joystick button has been pressed.

00 Button not pressed
01 Button pressed
10 Error Indicator
11 Not Available";
CM_ SG_ 2365446398 Joystick2Button8PressedStatus "Reports when the joystick button has been pressed.

00 Button not pressed
01 Button pressed
10 Error Indicator
11 Not Available";
CM_ SG_ 2365446398 Joystick2Button1PressedStatus "Reports when the joystick button has been pressed.

00 Button not pressed
01 Button pressed
10 Error Indicator
11 Not Available";
CM_ SG_ 2365446398 Joystick2Button2PressedStatus "Reports when the joystick button has been pressed.

00 Button not pressed
01 Button pressed
10 Error Indicator
11 Not Available";
CM_ SG_ 2365446398 Joystick2Button3PressedStatus "Reports when the joystick button has been pressed.

00 Button not pressed
01 Button pressed
10 Error Indicator
11 Not Available";
CM_ SG_ 2365446398 Joystick2Button4PressedStatus "Reports when the joystick button has been pressed.

00 Button not pressed
01 Button pressed
10 Error Indicator
11 Not Available";
CM_ BO_ 2365445886 "Used to transfer information about the measured status of the 1st 2 axes and up to 12 buttons of a joystick.  Additional handle information is available in the Expanded Joystick Message.
10-bit position parameters are broadcast over 2 bytes.  The ...";
CM_ SG_ 2365445886 Joystick1XAxisDetentPosStatus "Reports when the current joystick position is in the detent position for that axis of travel.

00 Not in the Detent Position
01 In the Detent Position
10 Error Indicator
11 Not Available";
CM_ SG_ 2365445886 Joystick1YAxisDetentPosStatus "Reports when the current joystick position is in the detent position for that axis of travel.

00 Not in the Detent Position
01 In the Detent Position
10 Error Indicator
11 Not Available";
CM_ SG_ 2365445886 Joystick1YAxisPos "The position of the joystick in the relative motion of travel from the neutral position.  Position value of 0 is Neutral and position value 1000 (100%) is the end of linear zone.  Value of 1022 indicates an error has occurred.";
CM_ SG_ 2365445886 Jystck1YAxsLvrFrwrdPstvPosStatus "Reports when the current joystick position is on the positive travel side (forward, right, clockwise, up) relative to the neutral position for that axis of travel.
00 Not on Positive side of Neutral
01 On positive side of Neutral
10 Error ...";
CM_ SG_ 2365445886 Jystck1YAxsLvrBckNgtivePosStatus "Reports when the current joystick position is on the negative travel side (back, left, counterclockwise, down) relative to the neutral position for that axis of travel.
00 Not on negative side of Neutral
01 On negative side of Neutral
10 Error ...";
CM_ SG_ 2365445886 Joystick1YAxisNeutralPosStatus "Reports when the current joystick position is in the neutral position for that axis of travel.  The neutral position measurement must be determined from some mechanism other than the axis position measurement device.
00 Not in Neutral Position
01 ...";
CM_ SG_ 2365445886 Joystick1XAxisPos "The position of the joystick in the relative motion of travel from the neutral position.  Position value of 0 is Neutral and position value 1000 (100%) is the end of linear zone.  Value of 1022 indicates an error has occurred.";
CM_ SG_ 2365445886 Joystick1Button9PressedStatus "Reports when the joystick button has been pressed.

00 Button not pressed
01 Button pressed
10 Error Indicator
11 Not Available";
CM_ SG_ 2365445886 Joystick1Button10PressedStatus "Reports when the joystick button has been pressed.

00 Button not pressed
01 Button pressed
10 Error Indicator
11 Not Available";
CM_ SG_ 2365445886 Joystick1Button11PressedStatus "Reports when the joystick button has been pressed.

00 Button not pressed
01 Button pressed
10 Error Indicator
11 Not Available";
CM_ SG_ 2365445886 Joystick1Button12PressedStatus "Reports when the joystick button has been pressed.

00 Button not pressed
01 Button pressed
10 Error Indicator
11 Not Available";
CM_ SG_ 2365445886 Joystick1Button5PressedStatus "Reports when the joystick button has been pressed.

00 Button not pressed
01 Button pressed
10 Error Indicator
11 Not Available";
CM_ SG_ 2365445886 Joystick1Button6PressedStatus "Reports when the joystick button has been pressed.

00 Button not pressed
01 Button pressed
10 Error Indicator
11 Not Available";
CM_ SG_ 2365445886 Joystick1Button7PressedStatus "Reports when the joystick button has been pressed.

00 Button not pressed
01 Button pressed
10 Error Indicator
11 Not Available";
CM_ SG_ 2365445886 Joystick1Button8PressedStatus "Reports when the joystick button has been pressed.

00 Button not pressed
01 Button pressed
10 Error Indicator
11 Not Available";
CM_ SG_ 2365445886 Joystick1Button1PressedStatus "Reports when the joystick button has been pressed.

00 Button not pressed
01 Button pressed
10 Error Indicator
11 Not Available";
CM_ SG_ 2365445886 Joystick1Button2PressedStatus "Reports when the joystick button has been pressed.

00 Button not pressed
01 Button pressed
10 Error Indicator
11 Not Available";
CM_ SG_ 2365445886 Joystick1Button3PressedStatus "Reports when the joystick button has been pressed.

00 Button not pressed
01 Button pressed
10 Error Indicator
11 Not Available";
CM_ SG_ 2365445886 Joystick1Button4PressedStatus "Reports when the joystick button has been pressed.

00 Button not pressed
01 Button pressed
10 Error Indicator
11 Not Available";
CM_ SG_ 2365445886 Jystck1XAxsLvrRghtPstvePosStatus "Reports when the current joystick position is on the positive travel side (forward, right, clockwise, up) relative to the neutral position for that axis of travel.
00 Not on Positive side of Neutral
01 On positive side of Neutral
10 Error ...";
CM_ SG_ 2365445886 Jystck1XAxsLvrLftNgtivePosStatus "Reports when the current joystick position is on the negative travel side (back, left, counterclockwise, down) relative to the neutral position for that axis of travel.
00 Not on negative side of Neutral
01 On negative side of Neutral
10 Error ...";
CM_ SG_ 2365445886 Joystick1XAxisNeutralPosStatus "Reports when the current joystick position is in the neutral position for that axis of travel.  The neutral position measurement must be determined from some mechanism other than the axis position measurement device.
00 Not in Neutral Position
01 ...";
BA_DEF_ SG_  "SigType" ENUM  "Default","Range","RangeSigned","ASCII","Discrete","Control","ReferencePGN","DTC","StringDelimiter","StringLength","StringLengthControl","MessageCounter","MessageChecksum";
BA_DEF_ SG_  "GenSigStartValue" INT 0 10000;
BA_DEF_ SG_  "GenSigSendType" ENUM  "Cyclic","OnWrite","OnWriteWithRepetition","OnChange","OnChangeWithRepetition","IfActive","IfActiveWithRepetition","NoSigSendType";
BA_DEF_ SG_  "GenSigILSupport" ENUM  "No","Yes";
BA_DEF_ SG_  "GenSigEVName" STRING ;
BA_DEF_ SG_  "SPN" INT 0 524287;
BA_DEF_ BO_  "GenMsgStartDelayTime" INT 0 100000;
BA_DEF_ BO_  "GenMsgILSupport" ENUM  "No","Yes";
BA_DEF_ BO_  "GenMsgRequestable" INT 0 1;
BA_DEF_ BO_  "GenMsgSendType" ENUM  "cyclic","NotUsed","NotUsed","NotUsed","NotUsed","NotUsed","NotUsed","IfActive","noMsgSendType";
BA_DEF_ BO_  "VFrameFormat" ENUM  "StandardCAN","ExtendedCAN","reserved","J1939PG";
BA_DEF_ BO_  "GenMsgCycleTime" INT 0 3600000;
BA_DEF_ SG_  "SystemSignalLongSymbol" STRING ;
BA_DEF_DEF_  "SigType" "Default";
BA_DEF_DEF_  "GenSigStartValue" 0;
BA_DEF_DEF_  "GenSigSendType" "NoSigSendType";
BA_DEF_DEF_  "GenSigILSupport" "Yes";
BA_DEF_DEF_  "GenSigEVName" "Env@Nodename_@Signame";
BA_DEF_DEF_  "SPN" 0;
BA_DEF_DEF_  "GenMsgStartDelayTime" 0;
BA_DEF_DEF_  "GenMsgILSupport" "Yes";
BA_DEF_DEF_  "GenMsgRequestable" 1;
BA_DEF_DEF_  "GenMsgSendType" "noMsgSendType";
BA_DEF_DEF_  "VFrameFormat" "J1939PG";
BA_DEF_DEF_  "GenMsgCycleTime" 0;
BA_DEF_DEF_  "SystemSignalLongSymbol" "";
BA_ "GenMsgSendType" BO_ 2365400318 0;
BA_ "GenMsgCycleTime" BO_ 2365400318 100;
BA_ "GenMsgSendType" BO_ 2499614718 0;
BA_ "GenMsgCycleTime" BO_ 2499614718 250;
BA_ "GenMsgSendType" BO_ 2566722814 0;
BA_ "GenMsgCycleTime" BO_ 2566722814 1000;
BA_ "GenMsgSendType" BO_ 2566723070 0;
BA_ "GenMsgCycleTime" BO_ 2566723070 1000;
BA_ "GenMsgSendType" BO_ 2566712830 0;
BA_ "GenMsgCycleTime" BO_ 2566712830 500;
BA_ "GenMsgSendType" BO_ 2566735358 0;
BA_ "GenMsgCycleTime" BO_ 2566735358 500;
BA_ "GenMsgSendType" BO_ 2566735102 0;
BA_ "GenMsgCycleTime" BO_ 2566735102 500;
BA_ "GenMsgSendType" BO_ 2566724350 0;
BA_ "GenMsgCycleTime" BO_ 2566724350 500;
BA_ "GenMsgSendType" BO_ 2566735614 0;
BA_ "GenMsgCycleTime" BO_ 2566735614 500;
BA_ "GenMsgSendType" BO_ 2566805246 0;
BA_ "GenMsgCycleTime" BO_ 2566805246 1000;
BA_ "GenMsgSendType" BO_ 2566711806 0;
BA_ "GenMsgCycleTime" BO_ 2566711806 100;
BA_ "GenMsgSendType" BO_ 2364549886 0;
BA_ "GenMsgCycleTime" BO_ 2364549886 10;
BA_ "GenMsgSendType" BO_ 2566712318 0;
BA_ "GenMsgCycleTime" BO_ 2566712318 1000;
BA_ "GenMsgSendType" BO_ 2566712574 0;
BA_ "GenMsgCycleTime" BO_ 2566712574 1000;
BA_ "GenMsgSendType" BO_ 2566731006 0;
BA_ "GenMsgCycleTime" BO_ 2566731006 1000;
BA_ "GenMsgSendType" BO_ 2566731262 0;
BA_ "GenMsgCycleTime" BO_ 2566731262 1000;
BA_ "GenMsgSendType" BO_ 2566730750 0;
BA_ "GenMsgCycleTime" BO_ 2566730750 1000;
BA_ "GenMsgSendType" BO_ 2566731518 0;
BA_ "GenMsgCycleTime" BO_ 2566731518 1000;
BA_ "GenMsgSendType" BO_ 2566732030 0;
BA_ "GenMsgCycleTime" BO_ 2566732030 500;
BA_ "GenMsgSendType" BO_ 2566732286 0;
BA_ "GenMsgCycleTime" BO_ 2566732286 500;
BA_ "GenMsgSendType" BO_ 2164079358 0;
BA_ "GenMsgCycleTime" BO_ 2164079358 500;
BA_ "GenMsgSendType" BO_ 2364549118 0;
BA_ "GenMsgCycleTime" BO_ 2364549118 50;
BA_ "GenMsgSendType" BO_ 2566732798 0;
BA_ "GenMsgCycleTime" BO_ 2566732798 500;
BA_ "GenMsgSendType" BO_ 2364548862 0;
BA_ "GenMsgCycleTime" BO_ 2364548862 50;
BA_ "GenMsgSendType" BO_ 2364549374 0;
BA_ "GenMsgCycleTime" BO_ 2364549374 50;
BA_ "GenMsgSendType" BO_ 2566726142 0;
BA_ "GenMsgCycleTime" BO_ 2566726142 500;
BA_ "GenMsgSendType" BO_ 2566725630 0;
BA_ "GenMsgCycleTime" BO_ 2566725630 500;
BA_ "GenMsgSendType" BO_ 2566733310 0;
BA_ "GenMsgCycleTime" BO_ 2566733310 1000;
BA_ "GenMsgSendType" BO_ 2566733054 0;
BA_ "GenMsgCycleTime" BO_ 2566733054 1000;
BA_ "GenMsgSendType" BO_ 2499624702 0;
BA_ "GenMsgCycleTime" BO_ 2499624702 500;
BA_ "GenMsgSendType" BO_ 2566733822 0;
BA_ "GenMsgCycleTime" BO_ 2566733822 500;
BA_ "GenMsgSendType" BO_ 2566734078 0;
BA_ "GenMsgCycleTime" BO_ 2566734078 500;
BA_ "GenMsgSendType" BO_ 2364548350 0;
BA_ "GenMsgCycleTime" BO_ 2364548350 50;
BA_ "GenMsgSendType" BO_ 2566734334 0;
BA_ "GenMsgCycleTime" BO_ 2566734334 500;
BA_ "GenMsgSendType" BO_ 2364548094 0;
BA_ "GenMsgCycleTime" BO_ 2364548094 50;
BA_ "GenMsgSendType" BO_ 2364548606 0;
BA_ "GenMsgCycleTime" BO_ 2364548606 50;
BA_ "GenMsgSendType" BO_ 2566726398 0;
BA_ "GenMsgCycleTime" BO_ 2566726398 500;
BA_ "GenMsgSendType" BO_ 2566809342 0;
BA_ "GenMsgCycleTime" BO_ 2566809342 1000;
BA_ "GenMsgSendType" BO_ 2365446910 0;
BA_ "GenMsgCycleTime" BO_ 2365446910 100;
BA_ "GenMsgSendType" BO_ 2365446398 0;
BA_ "GenMsgCycleTime" BO_ 2365446398 100;
BA_ "GenMsgSendType" BO_ 2365445886 0;
BA_ "GenMsgCycleTime" BO_ 2365445886 100;
BA_ "SigType" SG_ 2365400318 Joystick10Button9PressedStatus 4;
BA_ "SPN" SG_ 2365400318 Joystick10Button9PressedStatus 4734;
BA_ "SigType" SG_ 2365400318 Joystick10Button10PressedStatus 4;
BA_ "SPN" SG_ 2365400318 Joystick10Button10PressedStatus 4733;
BA_ "SigType" SG_ 2365400318 Joystick10Button11PressedStatus 4;
BA_ "SPN" SG_ 2365400318 Joystick10Button11PressedStatus 4732;
BA_ "SigType" SG_ 2365400318 Joystick10Button12PressedStatus 4;
BA_ "SPN" SG_ 2365400318 Joystick10Button12PressedStatus 4731;
BA_ "SigType" SG_ 2365400318 Joystick10Button5PressedStatus 4;
BA_ "SPN" SG_ 2365400318 Joystick10Button5PressedStatus 4730;
BA_ "SigType" SG_ 2365400318 Joystick10Button6PressedStatus 4;
BA_ "SPN" SG_ 2365400318 Joystick10Button6PressedStatus 4729;
BA_ "SigType" SG_ 2365400318 Joystick10Button7PressedStatus 4;
BA_ "SPN" SG_ 2365400318 Joystick10Button7PressedStatus 4728;
BA_ "SigType" SG_ 2365400318 Joystick10Button8PressedStatus 4;
BA_ "SPN" SG_ 2365400318 Joystick10Button8PressedStatus 4727;
BA_ "SigType" SG_ 2365400318 Joystick10Button1PressedStatus 4;
BA_ "SPN" SG_ 2365400318 Joystick10Button1PressedStatus 4726;
BA_ "SigType" SG_ 2365400318 Joystick10Button2PressedStatus 4;
BA_ "SPN" SG_ 2365400318 Joystick10Button2PressedStatus 4725;
BA_ "SigType" SG_ 2365400318 Joystick10Button3PressedStatus 4;
BA_ "SPN" SG_ 2365400318 Joystick10Button3PressedStatus 4724;
BA_ "SigType" SG_ 2365400318 Joystick10Button4PressedStatus 4;
BA_ "SPN" SG_ 2365400318 Joystick10Button4PressedStatus 4723;
BA_ "SigType" SG_ 2365400318 Joystick10XAxisDetentPosStatus 4;
BA_ "SPN" SG_ 2365400318 Joystick10XAxisDetentPosStatus 4722;
BA_ "SigType" SG_ 2365400318 Joystick10YAxisDetentPosStatus 4;
BA_ "SPN" SG_ 2365400318 Joystick10YAxisDetentPosStatus 4721;
BA_ "SPN" SG_ 2365400318 Joystick10YAxisPos 4720;
BA_ "SigType" SG_ 2365400318 Jystck10YAxsLvrFrwrdPstvPsStatus 4;
BA_ "SPN" SG_ 2365400318 Jystck10YAxsLvrFrwrdPstvPsStatus 4719;
BA_ "SigType" SG_ 2365400318 Jystck10YAxsLvrBckNgtvePosStatus 4;
BA_ "SPN" SG_ 2365400318 Jystck10YAxsLvrBckNgtvePosStatus 4718;
BA_ "SigType" SG_ 2365400318 Joystick10YAxisNeutralPosStatus 4;
BA_ "SPN" SG_ 2365400318 Joystick10YAxisNeutralPosStatus 4717;
BA_ "SPN" SG_ 2365400318 Joystick10XAxisPos 4716;
BA_ "SigType" SG_ 2365400318 Jystck10XAxsLvrRghtPstvPosStatus 4;
BA_ "SPN" SG_ 2365400318 Jystck10XAxsLvrRghtPstvPosStatus 4715;
BA_ "SigType" SG_ 2365400318 Jystck10XAxsLvrLftNgtvePosStatus 4;
BA_ "SPN" SG_ 2365400318 Jystck10XAxsLvrLftNgtvePosStatus 4714;
BA_ "SigType" SG_ 2365400318 Joystick10XAxisNeutralPosStatus 4;
BA_ "SPN" SG_ 2365400318 Joystick10XAxisNeutralPosStatus 4713;
BA_ "SigType" SG_ 2499614718 PssngrArbgDctivationSwitchStatus 5;
BA_ "SPN" SG_ 2499614718 PssngrArbgDctivationSwitchStatus 4962;
BA_ "SigType" SG_ 2499614718 Beltlock10Status 5;
BA_ "SPN" SG_ 2499614718 Beltlock10Status 4961;
BA_ "SigType" SG_ 2499614718 Beltlock9Status 5;
BA_ "SPN" SG_ 2499614718 Beltlock9Status 4960;
BA_ "SigType" SG_ 2499614718 Beltlock8Status 5;
BA_ "SPN" SG_ 2499614718 Beltlock8Status 4959;
BA_ "SigType" SG_ 2499614718 Beltlock7Status 5;
BA_ "SPN" SG_ 2499614718 Beltlock7Status 4958;
BA_ "SigType" SG_ 2499614718 Beltlock6Status 5;
BA_ "SPN" SG_ 2499614718 Beltlock6Status 4957;
BA_ "SigType" SG_ 2499614718 Beltlock5Status 5;
BA_ "SPN" SG_ 2499614718 Beltlock5Status 4956;
BA_ "SigType" SG_ 2499614718 Beltlock4Status 5;
BA_ "SPN" SG_ 2499614718 Beltlock4Status 4955;
BA_ "SigType" SG_ 2499614718 Beltlock3Status 5;
BA_ "SPN" SG_ 2499614718 Beltlock3Status 4954;
BA_ "SigType" SG_ 2499614718 PassengerBeltlockStatus 5;
BA_ "SPN" SG_ 2499614718 PassengerBeltlockStatus 4953;
BA_ "SigType" SG_ 2499614718 DriverBeltlockStatus 5;
BA_ "SPN" SG_ 2499614718 DriverBeltlockStatus 4952;
BA_ "SigType" SG_ 2566722814 BatteryCharger2OutputCurrent 1;
BA_ "SPN" SG_ 2566722814 BatteryCharger2OutputCurrent 4997;
BA_ "SigType" SG_ 2566722814 BatteryCharger2OutputVoltage 1;
BA_ "SPN" SG_ 2566722814 BatteryCharger2OutputVoltage 4996;
BA_ "SigType" SG_ 2566722814 BatteryCharger2PowerLineState 4;
BA_ "SPN" SG_ 2566722814 BatteryCharger2PowerLineState 4995;
BA_ "SPN" SG_ 2566722814 BatteryCharger2State 4994;
BA_ "SigType" SG_ 2566723070 BatteryCharger1OutputCurrent 1;
BA_ "SPN" SG_ 2566723070 BatteryCharger1OutputCurrent 4993;
BA_ "SigType" SG_ 2566723070 BatteryCharger1OutputVoltage 1;
BA_ "SPN" SG_ 2566723070 BatteryCharger1OutputVoltage 4992;
BA_ "SigType" SG_ 2566723070 BatteryCharger1PowerLineState 4;
BA_ "SPN" SG_ 2566723070 BatteryCharger1PowerLineState 4991;
BA_ "SPN" SG_ 2566723070 BatteryCharger1State 4990;
BA_ "SigType" SG_ 2566725118 Aftrtrtmnt2ThrWyCtlystDffGasTemp 1;
BA_ "SPN" SG_ 2566725118 Aftrtrtmnt2ThrWyCtlystDffGasTemp 4780;
BA_ "SigType" SG_ 2566725118 Aftrtrtmnt1ThrWyCtlystDffGasTemp 1;
BA_ "SPN" SG_ 2566725118 Aftrtrtmnt1ThrWyCtlystDffGasTemp 4779;
BA_ "SigType" SG_ 2566725374 Aftrtrtmnt2GsOxdtnCtlystDffGsTmp 1;
BA_ "SPN" SG_ 2566725374 Aftrtrtmnt2GsOxdtnCtlystDffGsTmp 4778;
BA_ "SigType" SG_ 2566725374 Aftrtrtmnt1GsOxdtnCtlystDffGsTmp 1;
BA_ "SPN" SG_ 2566725374 Aftrtrtmnt1GsOxdtnCtlystDffGsTmp 4777;
BA_ "SigType" SG_ 2566712830 Aftrtrtmnt2WrmUpDslOxdtnCtlystOt 1;
BA_ "SPN" SG_ 2566712830 Aftrtrtmnt2WrmUpDslOxdtnCtlystOt 5316;
BA_ "SigType" SG_ 2566712830 Aftrtrtmnt2WrmUpDslOxdtnCtlystIn 1;
BA_ "SPN" SG_ 2566712830 Aftrtrtmnt2WrmUpDslOxdtnCtlystIn 5315;
BA_ "SPN" SG_ 2566735358 Aftrtrtmnt2ThrWyCtlytcCnvrtrDffP 4300;
BA_ "SPN" SG_ 2566735358 Aftrtrtmnt2ThrWyCtlystOtltTmpPrl 4299;
BA_ "SPN" SG_ 2566735358 Aftrtrtmnt2ThrWyCtlystIntkTmpPrl 4298;
BA_ "SigType" SG_ 2566735358 Aftrtrtmnt2ThrWyCtalystDiffPress 1;
BA_ "SPN" SG_ 2566735358 Aftrtrtmnt2ThrWyCtalystDiffPress 4297;
BA_ "SigType" SG_ 2566735358 Aftrtrtmnt2ThrWyCtlystOutletTemp 1;
BA_ "SPN" SG_ 2566735358 Aftrtrtmnt2ThrWyCtlystOutletTemp 4296;
BA_ "SigType" SG_ 2566735358 Aftrtrtmnt2ThrWyCtlystIntakeTemp 1;
BA_ "SPN" SG_ 2566735358 Aftrtrtmnt2ThrWyCtlystIntakeTemp 4295;
BA_ "SigType" SG_ 2365393662 NOxSnsrATO2SlfdgnosisFinalResult 1;
BA_ "SPN" SG_ 2365393662 NOxSnsrATO2SlfdgnosisFinalResult 5719;
BA_ "SigType" SG_ 2365393662 Aftrtrtmnt2OtltGsNOxSnsrNH3Crrct 1;
BA_ "SPN" SG_ 2365393662 Aftrtrtmnt2OtltGsNOxSnsrNH3Crrct 5051;
BA_ "SigType" SG_ 2365393662 Aftrtrtmnt2OtltGsNOxSnsrNO2Crrct 1;
BA_ "SPN" SG_ 2365393662 Aftrtrtmnt2OtltGsNOxSnsrNO2Crrct 5050;
BA_ "SigType" SG_ 2365393662 Aftrtrtmnt2OtltGsNOxSnsrCrrc5049 1;
BA_ "SPN" SG_ 2365393662 Aftrtrtmnt2OtltGsNOxSnsrCrrc5049 5049;
BA_ "SigType" SG_ 2365393662 Aftrtrtmnt2OtltGsNOxSnsrCrrctnOf 1;
BA_ "SPN" SG_ 2365393662 Aftrtrtmnt2OtltGsNOxSnsrCrrctnOf 5048;
BA_ "SigType" SG_ 2365393918 NOxSnsrATO2OperationHoursCounter 1;
BA_ "SPN" SG_ 2365393918 NOxSnsrATO2OperationHoursCounter 5723;
BA_ "SigType" SG_ 2365393918 Aftrtrtmnt2OtltGsNOxSnsrNwPr5047 1;
BA_ "SPN" SG_ 2365393918 Aftrtrtmnt2OtltGsNOxSnsrNwPr5047 5047;
BA_ "SigType" SG_ 2365393918 Aftrtrtmnt2OtltGsNOxSnsrNwPrtDvt 1;
BA_ "SPN" SG_ 2365393918 Aftrtrtmnt2OtltGsNOxSnsrNwPrtDvt 5046;
BA_ "SigType" SG_ 2365393918 Aftrtrtmnt2OtltGsNOxSnsrHtrRatio 1;
BA_ "SPN" SG_ 2365393918 Aftrtrtmnt2OtltGsNOxSnsrHtrRatio 5045;
BA_ "SigType" SG_ 2365394174 NOxSnsrATI2SlfdgnosisFinalResult 1;
BA_ "SPN" SG_ 2365394174 NOxSnsrATI2SlfdgnosisFinalResult 5720;
BA_ "SigType" SG_ 2365394174 Aftrtrtmnt2IntkGsNOxSnsrNH3Crrct 1;
BA_ "SPN" SG_ 2365394174 Aftrtrtmnt2IntkGsNOxSnsrNH3Crrct 5044;
BA_ "SigType" SG_ 2365394174 Aftrtrtmnt2IntkGsNOxSnsrNO2Crrct 1;
BA_ "SPN" SG_ 2365394174 Aftrtrtmnt2IntkGsNOxSnsrNO2Crrct 5043;
BA_ "SigType" SG_ 2365394174 Aftrtrtmnt2IntkGsNOxSnsrCrrc5042 1;
BA_ "SPN" SG_ 2365394174 Aftrtrtmnt2IntkGsNOxSnsrCrrc5042 5042;
BA_ "SigType" SG_ 2365394174 Aftrtrtmnt2IntkGsNOxSnsrCrrctnOf 1;
BA_ "SPN" SG_ 2365394174 Aftrtrtmnt2IntkGsNOxSnsrCrrctnOf 5041;
BA_ "SigType" SG_ 2365394430 NOxSnsrATI2OperationHoursCounter 1;
BA_ "SPN" SG_ 2365394430 NOxSnsrATI2OperationHoursCounter 5724;
BA_ "SigType" SG_ 2365394430 Aftrtrtmnt2IntkGsNOxSnsrNwPr5040 1;
BA_ "SPN" SG_ 2365394430 Aftrtrtmnt2IntkGsNOxSnsrNwPr5040 5040;
BA_ "SigType" SG_ 2365394430 Aftrtrtmnt2IntkGsNOxSnsrNwPrtDvt 1;
BA_ "SPN" SG_ 2365394430 Aftrtrtmnt2IntkGsNOxSnsrNwPrtDvt 5039;
BA_ "SigType" SG_ 2365394430 Aftrtrtmnt2IntkGsNOxSnsrHtrRatio 1;
BA_ "SPN" SG_ 2365394430 Aftrtrtmnt2IntkGsNOxSnsrHtrRatio 5038;
BA_ "SigType" SG_ 2566735102 Aftertreatment2FuelPress2Ctrl 1;
BA_ "SPN" SG_ 2566735102 Aftertreatment2FuelPress2Ctrl 5428;
BA_ "SigType" SG_ 2566735102 Aftrtrtmnt2FlFlwDverterValveCtrl 5;
BA_ "SPN" SG_ 2566735102 Aftrtrtmnt2FlFlwDverterValveCtrl 5427;
BA_ "SigType" SG_ 2566735102 Aftertreatment2FuelPumpRelayCtrl 5;
BA_ "SPN" SG_ 2566735102 Aftertreatment2FuelPumpRelayCtrl 5426;
BA_ "SigType" SG_ 2566735102 Aftertreatment2FuelPress2 1;
BA_ "SPN" SG_ 2566735102 Aftertreatment2FuelPress2 4303;
BA_ "SigType" SG_ 2157313790 Aftrtrtmnt2DslPrtcltFltrStStndrd 1;
BA_ "SPN" SG_ 2157313790 Aftrtrtmnt2DslPrtcltFltrStStndrd 5498;
BA_ "SigType" SG_ 2157313790 Aftrtrtmnt2DslPrtcltFltrStMnClbO 1;
BA_ "SPN" SG_ 2157313790 Aftrtrtmnt2DslPrtcltFltrStMnClbO 5497;
BA_ "SigType" SG_ 2566724350 Aftrtrtmnt1WrmUpDslOxdtnCtlystOt 1;
BA_ "SPN" SG_ 2566724350 Aftrtrtmnt1WrmUpDslOxdtnCtlystOt 4810;
BA_ "SigType" SG_ 2566724350 Aftrtrtmnt1WrmUpDslOxdtnCtlystIn 1;
BA_ "SPN" SG_ 2566724350 Aftrtrtmnt1WrmUpDslOxdtnCtlystIn 4809;
BA_ "SPN" SG_ 2566735614 Aftrtrtmnt1ThrWyCtlytcCnvrtrDffP 4294;
BA_ "SPN" SG_ 2566735614 Aftrtrtmnt1ThrWyCtlystOtltTmpPrl 4293;
BA_ "SPN" SG_ 2566735614 Aftrtrtmnt1ThrWyCtlystIntkTmpPrl 4292;
BA_ "SigType" SG_ 2566735614 Aftrtrtmnt1ThrWyCtalystDiffPress 1;
BA_ "SPN" SG_ 2566735614 Aftrtrtmnt1ThrWyCtalystDiffPress 4291;
BA_ "SigType" SG_ 2566735614 Aftrtrtmnt1ThrWyCtlystOutletTemp 1;
BA_ "SPN" SG_ 2566735614 Aftrtrtmnt1ThrWyCtlystOutletTemp 4290;
BA_ "SigType" SG_ 2566735614 Aftrtrtmnt1ThrWyCtlystIntakeTemp 1;
BA_ "SPN" SG_ 2566735614 Aftrtrtmnt1ThrWyCtlystIntakeTemp 4289;
BA_ "SPN" SG_ 2566805246 Aftrtrtmnt1DslExhstFldTnk1HtrPrl 4366;
BA_ "SigType" SG_ 2566805246 Aftrtrtmnt1DslExhstFldTankHeater 1;
BA_ "SPN" SG_ 2566805246 Aftrtrtmnt1DslExhstFldTankHeater 3363;
BA_ "SPN" SG_ 2566805246 AftrtrtmntSCROprtrIndcmntSverity 5246;
BA_ "SPN" SG_ 2566805246 Aftrtrtmnt1DslExhstFldTnk1TmpPrl 4365;
BA_ "SPN" SG_ 2566805246 AftrtrtmntSlctvCtlytcRdctnOprtrI 5245;
BA_ "SPN" SG_ 2566805246 Aftrtrtmnt1DslExhstFldTnkLvlPrlm 3532;
BA_ "SigType" SG_ 2566805246 Aftrtrtmnt1DslExhstFldTankLevel2 1;
BA_ "SPN" SG_ 2566805246 Aftrtrtmnt1DslExhstFldTankLevel2 3517;
BA_ "SigType" SG_ 2566805246 Aftrtrtmnt1DslExhstFluidTankTemp 1;
BA_ "SPN" SG_ 2566805246 Aftrtrtmnt1DslExhstFluidTankTemp 3031;
BA_ "SigType" SG_ 2566805246 Aftrtrtmnt1DslExhstFlidTankLevel 1;
BA_ "SPN" SG_ 2566805246 Aftrtrtmnt1DslExhstFlidTankLevel 1761;
BA_ "SigType" SG_ 2365394686 NOxSnsrATO1SlfdgnosisFinalResult 1;
BA_ "SPN" SG_ 2365394686 NOxSnsrATO1SlfdgnosisFinalResult 5717;
BA_ "SigType" SG_ 2365394686 Aftrtrtmnt1OtltGsNOxSnsrNH3Crrct 1;
BA_ "SPN" SG_ 2365394686 Aftrtrtmnt1OtltGsNOxSnsrNH3Crrct 5037;
BA_ "SigType" SG_ 2365394686 Aftrtrtmnt1OtltGsNOxSnsrNO2Crrct 1;
BA_ "SPN" SG_ 2365394686 Aftrtrtmnt1OtltGsNOxSnsrNO2Crrct 5036;
BA_ "SigType" SG_ 2365394686 Aftrtrtmnt1OtltGsNOxSnsrCrrc5035 1;
BA_ "SPN" SG_ 2365394686 Aftrtrtmnt1OtltGsNOxSnsrCrrc5035 5035;
BA_ "SigType" SG_ 2365394686 Aftrtrtmnt1OtltGsNOxSnsrCrrctnOf 1;
BA_ "SPN" SG_ 2365394686 Aftrtrtmnt1OtltGsNOxSnsrCrrctnOf 5034;
BA_ "SigType" SG_ 2365394942 NOxSnsrATO1OperationHoursCounter 1;
BA_ "SPN" SG_ 2365394942 NOxSnsrATO1OperationHoursCounter 5721;
BA_ "SigType" SG_ 2365394942 Aftrtrtmnt1OtltGsNOxSnsrNwPr5033 1;
BA_ "SPN" SG_ 2365394942 Aftrtrtmnt1OtltGsNOxSnsrNwPr5033 5033;
BA_ "SigType" SG_ 2365394942 Aftrtrtmnt1OtltGsNOxSnsrNwPrtDvt 1;
BA_ "SPN" SG_ 2365394942 Aftrtrtmnt1OtltGsNOxSnsrNwPrtDvt 5032;
BA_ "SigType" SG_ 2365394942 Aftrtrtmnt1OtltGsNOxSnsrHtrRatio 1;
BA_ "SPN" SG_ 2365394942 Aftrtrtmnt1OtltGsNOxSnsrHtrRatio 5031;
BA_ "SigType" SG_ 2365395198 NOxSnsrATI1SlfdgnosisFinalResult 1;
BA_ "SPN" SG_ 2365395198 NOxSnsrATI1SlfdgnosisFinalResult 5718;
BA_ "SigType" SG_ 2365395198 Aftrtrtmnt1IntkGsNOxSnsrNH3Crrct 1;
BA_ "SPN" SG_ 2365395198 Aftrtrtmnt1IntkGsNOxSnsrNH3Crrct 5030;
BA_ "SigType" SG_ 2365395198 Aftrtrtmnt1IntkGsNOxSnsrNO2Crrct 1;
BA_ "SPN" SG_ 2365395198 Aftrtrtmnt1IntkGsNOxSnsrNO2Crrct 5029;
BA_ "SigType" SG_ 2365395198 Aftrtrtmnt1IntkGsNOxSnsrCrrc5028 1;
BA_ "SPN" SG_ 2365395198 Aftrtrtmnt1IntkGsNOxSnsrCrrc5028 5028;
BA_ "SigType" SG_ 2365395198 Aftrtrtmnt1IntkGsNOxSnsrCrrctnOf 1;
BA_ "SPN" SG_ 2365395198 Aftrtrtmnt1IntkGsNOxSnsrCrrctnOf 5027;
BA_ "SigType" SG_ 2365395454 NOxSnsrATI1OperationHoursCounter 1;
BA_ "SPN" SG_ 2365395454 NOxSnsrATI1OperationHoursCounter 5722;
BA_ "SigType" SG_ 2365395454 Aftrtrtmnt1IntkGsNOxSnsrNwPr5026 1;
BA_ "SPN" SG_ 2365395454 Aftrtrtmnt1IntkGsNOxSnsrNwPr5026 5026;
BA_ "SigType" SG_ 2365395454 Aftrtrtmnt1IntkGsNOxSnsrNwPrtDvt 1;
BA_ "SPN" SG_ 2365395454 Aftrtrtmnt1IntkGsNOxSnsrNwPrtDvt 5025;
BA_ "SigType" SG_ 2365395454 Aftrtrtmnt1IntkGsNOxSnsrHtrRatio 1;
BA_ "SPN" SG_ 2365395454 Aftrtrtmnt1IntkGsNOxSnsrHtrRatio 5024;
BA_ "SigType" SG_ 2157248254 Aftrtrtmnt1DslPrtcltFltrStStndrd 1;
BA_ "SPN" SG_ 2157248254 Aftrtrtmnt1DslPrtcltFltrStStndrd 5496;
BA_ "SigType" SG_ 2157248254 Aftrtrtmnt1DslPrtcltFltrStMnClbO 1;
BA_ "SPN" SG_ 2157248254 Aftrtrtmnt1DslPrtcltFltrStMnClbO 5495;
BA_ "SigType" SG_ 2566711806 Armrest2Switch2 5;
BA_ "SPN" SG_ 2566711806 Armrest2Switch2 5494;
BA_ "SigType" SG_ 2566711806 Armrest2Switch1 5;
BA_ "SPN" SG_ 2566711806 Armrest2Switch1 5493;
BA_ "SigType" SG_ 2566711806 Armrest1Switch2 5;
BA_ "SPN" SG_ 2566711806 Armrest1Switch2 5492;
BA_ "SigType" SG_ 2566711806 Armrest1Switch1 5;
BA_ "SPN" SG_ 2566711806 Armrest1Switch1 1503;
BA_ "SigType" SG_ 2364549886 AngularRateMeasurementLatency 1;
BA_ "SPN" SG_ 2364549886 AngularRateMeasurementLatency 4989;
BA_ "SigType" SG_ 2364549886 YawRateExRangeFigureOfMerit 5;
BA_ "SPN" SG_ 2364549886 YawRateExRangeFigureOfMerit 4988;
BA_ "SigType" SG_ 2364549886 RollRateExRangeFigureOfMerit 5;
BA_ "SPN" SG_ 2364549886 RollRateExRangeFigureOfMerit 4987;
BA_ "SigType" SG_ 2364549886 PitchRateExRangeFigureOfMerit 5;
BA_ "SPN" SG_ 2364549886 PitchRateExRangeFigureOfMerit 4986;
BA_ "SigType" SG_ 2364549886 YawRateExRange 1;
BA_ "SPN" SG_ 2364549886 YawRateExRange 4985;
BA_ "SigType" SG_ 2364549886 RollRateExRange 1;
BA_ "SPN" SG_ 2364549886 RollRateExRange 4984;
BA_ "SigType" SG_ 2364549886 PitchRateExRange 1;
BA_ "SPN" SG_ 2364549886 PitchRateExRange 4983;
BA_ "SigType" SG_ 2566712318 Aftrtrtmnt2NOxAdsrbrDSOxRgnrtnSt 5;
BA_ "SPN" SG_ 2566712318 Aftrtrtmnt2NOxAdsrbrDSOxRgnrtnSt 5462;
BA_ "SigType" SG_ 2566712318 Aftrtrtmnt2NOxAdsrbrDNOxRgnrtnSt 5;
BA_ "SPN" SG_ 2566712318 Aftrtrtmnt2NOxAdsrbrDNOxRgnrtnSt 5460;
BA_ "SigType" SG_ 2566712574 Aftrtrtmnt1NOxAdsrbrDSOxRgnrtnSt 5;
BA_ "SPN" SG_ 2566712574 Aftrtrtmnt1NOxAdsrbrDSOxRgnrtnSt 5461;
BA_ "SigType" SG_ 2566712574 Aftrtrtmnt1NOxAdsrbrDNOxRgnrtnSt 5;
BA_ "SPN" SG_ 2566712574 Aftrtrtmnt1NOxAdsrbrDNOxRgnrtnSt 5459;
BA_ "SigType" SG_ 2164078590 Aftrtrtmnt2SCRCnvrsionEfficiency 1;
BA_ "SPN" SG_ 2164078590 Aftrtrtmnt2SCRCnvrsionEfficiency 4419;
BA_ "SigType" SG_ 2164078590 Aftrtrtmnt2SCRCmmnddCtlystDslExh 1;
BA_ "SPN" SG_ 2164078590 Aftrtrtmnt2SCRCmmnddCtlystDslExh 4418;
BA_ "SigType" SG_ 2164078590 Aftrtrtmnt2DslExhstFldAvrgCnsmpt 1;
BA_ "SPN" SG_ 2164078590 Aftrtrtmnt2DslExhstFldAvrgCnsmpt 4417;
BA_ "SPN" SG_ 2566731006 Aftrtrtmnt2DslExhstFldTnk2HtrPrl 4439;
BA_ "SPN" SG_ 2566731006 Aftrtrtmnt2DslExhstFldTnk2Heater 4438;
BA_ "SPN" SG_ 2566731006 Aftrtrtmnt2DslExhstFldTnk2TmpPrl 4437;
BA_ "SPN" SG_ 2566731006 Aftrtrtmnt2DslExhstFldTnk2LvlPrl 4436;
BA_ "SigType" SG_ 2566731006 Aftrtrtmnt2DslExhstFldTnk2Level2 1;
BA_ "SPN" SG_ 2566731006 Aftrtrtmnt2DslExhstFldTnk2Level2 4435;
BA_ "SigType" SG_ 2566731006 Aftrtrtmnt2DslExhstFlidTank2Temp 1;
BA_ "SPN" SG_ 2566731006 Aftrtrtmnt2DslExhstFlidTank2Temp 4434;
BA_ "SigType" SG_ 2566731006 Aftrtrtmnt2DslExhstFldTank2Level 1;
BA_ "SPN" SG_ 2566731006 Aftrtrtmnt2DslExhstFldTank2Level 4433;
BA_ "SPN" SG_ 2566731262 Aftrtrtmnt2DslExhstFldTnk1HtrPrl 4432;
BA_ "SigType" SG_ 2566731262 Aftrtrtmnt2DslExhstFldTankHeater 1;
BA_ "SPN" SG_ 2566731262 Aftrtrtmnt2DslExhstFldTankHeater 4431;
BA_ "SPN" SG_ 2566731262 Aftrtrtmnt2DslExhstFldTnk1TmpPrl 4430;
BA_ "SPN" SG_ 2566731262 Aftrtrtmnt2DslExhstFldTnkLvlPrlm 4429;
BA_ "SigType" SG_ 2566731262 Aftrtrtmnt2DslExhstFldTankLevel2 1;
BA_ "SPN" SG_ 2566731262 Aftrtrtmnt2DslExhstFldTankLevel2 4428;
BA_ "SigType" SG_ 2566731262 Aftrtrtmnt2DslExhstFluidTankTemp 1;
BA_ "SPN" SG_ 2566731262 Aftrtrtmnt2DslExhstFluidTankTemp 4427;
BA_ "SigType" SG_ 2566731262 Aftrtrtmnt2DslExhstFlidTankLevel 1;
BA_ "SPN" SG_ 2566731262 Aftrtrtmnt2DslExhstFlidTankLevel 4426;
BA_ "SigType" SG_ 2566730750 Aftrtrtmnt2DslExhstFldTnkDrnVlvC 1;
BA_ "SPN" SG_ 2566730750 Aftrtrtmnt2DslExhstFldTnkDrnVlvC 5439;
BA_ "SigType" SG_ 2566730750 Aftrtrtmnt2DslExhstFlidPumpState 5;
BA_ "SPN" SG_ 2566730750 Aftrtrtmnt2DslExhstFlidPumpState 5438;
BA_ "SigType" SG_ 2566730750 Aftrtrtmnt2DslExhstFldTnkFllVlvC 1;
BA_ "SPN" SG_ 2566730750 Aftrtrtmnt2DslExhstFldTnkFllVlvC 5437;
BA_ "SigType" SG_ 2566730750 Aftrtrtmnt2DslExhstFldRturnValve 1;
BA_ "SPN" SG_ 2566730750 Aftrtrtmnt2DslExhstFldRturnValve 4442;
BA_ "SigType" SG_ 2566730750 Aftrtrtmnt2DslExhstFldPmpDrvPrcn 1;
BA_ "SPN" SG_ 2566730750 Aftrtrtmnt2DslExhstFldPmpDrvPrcn 4441;
BA_ "SigType" SG_ 2566730750 Aftrtrtmnt2DslExhstFldPmpMtrSped 1;
BA_ "SPN" SG_ 2566730750 Aftrtrtmnt2DslExhstFldPmpMtrSped 4440;
BA_ "SPN" SG_ 2566731518 Aftrtrtmnt2DeselExhaustFluidType 4425;
BA_ "SPN" SG_ 2566731518 Aftrtrtmnt2DslExhstFldPrprtsPrlm 4424;
BA_ "SPN" SG_ 2566731518 Aftrtrtmnt2DslExhstFldTmp2Prlmnr 4423;
BA_ "SigType" SG_ 2566731518 Aftrtrtmnt2DslExhstFldCndctivity 1;
BA_ "SPN" SG_ 2566731518 Aftrtrtmnt2DslExhstFldCndctivity 4422;
BA_ "SigType" SG_ 2566731518 Aftrtrtmnt2DslExhstFldCncntrtion 1;
BA_ "SPN" SG_ 2566731518 Aftrtrtmnt2DslExhstFldCncntrtion 4421;
BA_ "SigType" SG_ 2566731518 Aftrtrtmnt2DselExhaustFluidTemp2 1;
BA_ "SPN" SG_ 2566731518 Aftrtrtmnt2DselExhaustFluidTemp2 4420;
BA_ "SPN" SG_ 2566732030 Aftrtrtmnt2SCRCtlystOtltGsTmpPrl 4416;
BA_ "SigType" SG_ 2566732030 Aftrtrtmnt2SCRCtlystOtletGasTemp 1;
BA_ "SPN" SG_ 2566732030 Aftrtrtmnt2SCRCtlystOtletGasTemp 4415;
BA_ "SPN" SG_ 2566732030 Aftrtrtmnt2SCRCtlystIntkGsTmpPrl 4414;
BA_ "SigType" SG_ 2566732030 Aftrtrtmnt2SCRCtlystIntkeGasTemp 1;
BA_ "SPN" SG_ 2566732030 Aftrtrtmnt2SCRCtlystIntkeGasTemp 4413;
BA_ "SigType" SG_ 2566732286 Aftertreatment2SCRIntakePress 1;
BA_ "SPN" SG_ 2566732286 Aftertreatment2SCRIntakePress 6587;
BA_ "SPN" SG_ 2566732286 Aftrtrtmnt2SCRExhstGsDffPrssPrlm 4412;
BA_ "SigType" SG_ 2566732286 Aftrtrtmnt2SCRExhustGasDiffPress 1;
BA_ "SPN" SG_ 2566732286 Aftrtrtmnt2SCRExhustGasDiffPress 4411;
BA_ "SigType" SG_ 2164079358 Aftrtrtmnt2DslExhstFldTnk2HtrCmd 1;
BA_ "SPN" SG_ 2164079358 Aftrtrtmnt2DslExhstFldTnk2HtrCmd 5415;
BA_ "SigType" SG_ 2164079358 Aftrtrtmnt2DslExhstFldTnkHterCmd 1;
BA_ "SPN" SG_ 2164079358 Aftrtrtmnt2DslExhstFldTnkHterCmd 5138;
BA_ "SigType" SG_ 2164079358 Aftrtrtmnt2DslExhstFldLneHeater4 5;
BA_ "SPN" SG_ 2164079358 Aftrtrtmnt2DslExhstFldLneHeater4 4410;
BA_ "SigType" SG_ 2164079358 Aftrtrtmnt2DslExhstFldLneHeater3 5;
BA_ "SPN" SG_ 2164079358 Aftrtrtmnt2DslExhstFldLneHeater3 4409;
BA_ "SigType" SG_ 2164079358 Aftrtrtmnt2DslExhstFldLneHeater2 5;
BA_ "SPN" SG_ 2164079358 Aftrtrtmnt2DslExhstFldLneHeater2 4408;
BA_ "SigType" SG_ 2164079358 Aftrtrtmnt2DslExhstFldLneHeater1 5;
BA_ "SPN" SG_ 2164079358 Aftrtrtmnt2DslExhstFldLneHeater1 4407;
BA_ "SPN" SG_ 2164079358 Aftrtrtmnt2DslExhstFldDsrHtngMdR 4406;
BA_ "SigType" SG_ 2164079358 Aftrtrtmnt2DslExhstFldDsrFltSppr 5;
BA_ "SPN" SG_ 2164079358 Aftrtrtmnt2DslExhstFldDsrFltSppr 4405;
BA_ "SigType" SG_ 2364549118 Aftrtrtmnt2DslExhstFldRqstdQntty 1;
BA_ "SPN" SG_ 2364549118 Aftrtrtmnt2DslExhstFldRqstdQntty 4403;
BA_ "SigType" SG_ 2364549118 Aftrtrtmnt2DslExhstFldDsngRq6594 1;
BA_ "SPN" SG_ 2364549118 Aftrtrtmnt2DslExhstFldDsngRq6594 6594;
BA_ "SPN" SG_ 2364549118 Aftrtrtmnt2SCRSystmRquestedState 4402;
BA_ "SigType" SG_ 2364549118 Aftrtrtmnt2DslExhstFldDsngRqstdQ 1;
BA_ "SPN" SG_ 2364549118 Aftrtrtmnt2DslExhstFldDsngRqstdQ 4401;
BA_ "SPN" SG_ 2566732798 Aftrtrtmnt2DslExhstFldLnHtr4Prlm 4400;
BA_ "SigType" SG_ 2566732798 Aftrtrtmnt2DslExhstFldLnHtr4Stte 5;
BA_ "SPN" SG_ 2566732798 Aftrtrtmnt2DslExhstFldLnHtr4Stte 4399;
BA_ "SPN" SG_ 2566732798 Aftrtrtmnt2DslExhstFldLnHtr3Prlm 4398;
BA_ "SigType" SG_ 2566732798 Aftrtrtmnt2DslExhstFldLnHtr3Stte 5;
BA_ "SPN" SG_ 2566732798 Aftrtrtmnt2DslExhstFldLnHtr3Stte 4397;
BA_ "SPN" SG_ 2566732798 Aftrtrtmnt2DslExhstFldLnHtr2Prlm 4396;
BA_ "SigType" SG_ 2566732798 Aftrtrtmnt2DslExhstFldLnHtr2Stte 5;
BA_ "SPN" SG_ 2566732798 Aftrtrtmnt2DslExhstFldLnHtr2Stte 4395;
BA_ "SPN" SG_ 2566732798 Aftrtrtmnt2DslExhstFldLnHtr1Prlm 4394;
BA_ "SigType" SG_ 2566732798 Aftrtrtmnt2DslExhstFldLnHtr1Stte 5;
BA_ "SPN" SG_ 2566732798 Aftrtrtmnt2DslExhstFldLnHtr1Stte 4393;
BA_ "SPN" SG_ 2566732798 Aftrtrtmnt2SCRFeedbackCtrlStatus 4392;
BA_ "SPN" SG_ 2566732798 Aftrtrtmnt2SCRDsngVlvExhstTmpRdc 4391;
BA_ "SigType" SG_ 2566732798 Aftrtrtmnt2DslExhstFldDosingTemp 1;
BA_ "SPN" SG_ 2566732798 Aftrtrtmnt2DslExhstFldDosingTemp 4390;
BA_ "SigType" SG_ 2566732798 Aftrtrtmnt2SCRDsngAirAssistValve 1;
BA_ "SPN" SG_ 2566732798 Aftrtrtmnt2SCRDsngAirAssistValve 4389;
BA_ "SigType" SG_ 2566732798 Aftrtrtmnt2SCRDsngArAssstAbsPrss 1;
BA_ "SPN" SG_ 2566732798 Aftrtrtmnt2SCRDsngArAssstAbsPrss 4388;
BA_ "SigType" SG_ 2364548862 Aftrtrtmnt2DslExhstFldActlDs6596 1;
BA_ "SPN" SG_ 2364548862 Aftrtrtmnt2DslExhstFldActlDs6596 6596;
BA_ "SigType" SG_ 2364548862 Aftrtrtmnt2DslExhstFldDsngAbsPrs 1;
BA_ "SPN" SG_ 2364548862 Aftrtrtmnt2DslExhstFldDsngAbsPrs 4387;
BA_ "SigType" SG_ 2364548862 Aftrtrtmnt2DslExhstFldActlQnttyO 1;
BA_ "SPN" SG_ 2364548862 Aftrtrtmnt2DslExhstFldActlQnttyO 4386;
BA_ "SPN" SG_ 2364548862 Aftertreatment2SCRSystemState 4385;
BA_ "SigType" SG_ 2364548862 Aftrtrtmnt2DslExhstFldActlDsngQn 1;
BA_ "SPN" SG_ 2364548862 Aftrtrtmnt2DslExhstFldActlDsngQn 4384;
BA_ "SigType" SG_ 2364549374 Aftrtrtmnt2OtltNH3GsSnsrHterCtrl 5;
BA_ "SPN" SG_ 2364549374 Aftrtrtmnt2OtltNH3GsSnsrHterCtrl 4449;
BA_ "SPN" SG_ 2364549374 Aftrtrtmnt2OtltNH3GsSnsrHtrPrlmn 4448;
BA_ "SigType" SG_ 2364549374 Aftrtrtmnt2OtltNH3GsSensorAtTemp 5;
BA_ "SPN" SG_ 2364549374 Aftrtrtmnt2OtltNH3GsSensorAtTemp 4447;
BA_ "SigType" SG_ 2364549374 Aftrtrtmnt2OtltNH3GsSnsrPwrInRng 5;
BA_ "SPN" SG_ 2364549374 Aftrtrtmnt2OtltNH3GsSnsrPwrInRng 4446;
BA_ "SigType" SG_ 2364549374 Aftrtrtmnt2OtletNH3ReadingStable 5;
BA_ "SPN" SG_ 2364549374 Aftrtrtmnt2OtletNH3ReadingStable 4445;
BA_ "SPN" SG_ 2364549374 Aftrtrtmnt2OtltNH3SnsrPrlmnryFMI 4444;
BA_ "SigType" SG_ 2364549374 Aftertreatment2OutletNH3 1;
BA_ "SPN" SG_ 2364549374 Aftertreatment2OutletNH3 4443;
BA_ "SPN" SG_ 2566726142 Aftrtrtmnt2GsOxdtnCtlystDffPrssP 4764;
BA_ "SPN" SG_ 2566726142 Aftrtrtmnt2GsOxdtnCtlystOtlt4763 4763;
BA_ "SPN" SG_ 2566726142 Aftrtrtmnt2GsOxdtnCtlystIntk4762 4762;
BA_ "SigType" SG_ 2566726142 Aftrtrtmnt2GsOxdtnCtlystDffPress 1;
BA_ "SPN" SG_ 2566726142 Aftrtrtmnt2GsOxdtnCtlystDffPress 4761;
BA_ "SigType" SG_ 2566726142 Aftrtrtmnt2GsOxdtnCtlystOtltGsTm 1;
BA_ "SPN" SG_ 2566726142 Aftrtrtmnt2GsOxdtnCtlystOtltGsTm 4760;
BA_ "SigType" SG_ 2566726142 Aftrtrtmnt2GsOxdtnCtlystIntkGsTm 1;
BA_ "SPN" SG_ 2566726142 Aftrtrtmnt2GsOxdtnCtlystIntkGsTm 4759;
BA_ "SPN" SG_ 2566725630 Aftrtrtmnt2DslOxdtnCtlystDff4776 4776;
BA_ "SPN" SG_ 2566725630 Aftrtrtmnt2DslOxdtnCtlystOtl4775 4775;
BA_ "SPN" SG_ 2566725630 Aftrtrtmnt2DslOxdtnCtlystInt4774 4774;
BA_ "SigType" SG_ 2566725630 Aftrtrtmnt2DslOxdtnCtlystDffPrss 1;
BA_ "SPN" SG_ 2566725630 Aftrtrtmnt2DslOxdtnCtlystDffPrss 4773;
BA_ "SigType" SG_ 2566725630 Aftrtrtmnt2DslOxdtnCtlystOtltGsT 1;
BA_ "SPN" SG_ 2566725630 Aftrtrtmnt2DslOxdtnCtlystOtltGsT 4772;
BA_ "SigType" SG_ 2566725630 Aftrtrtmnt2DslOxdtnCtlystIntkGsT 1;
BA_ "SPN" SG_ 2566725630 Aftrtrtmnt2DslOxdtnCtlystIntkGsT 4771;
BA_ "SPN" SG_ 2566733310 Aftrtrtmnt1DslExhstFldTnk2HtrPrl 4373;
BA_ "SigType" SG_ 2566733310 Aftrtrtmnt1DslExhstFldTnk2Heater 1;
BA_ "SPN" SG_ 2566733310 Aftrtrtmnt1DslExhstFldTnk2Heater 4372;
BA_ "SPN" SG_ 2566733310 Aftrtrtmnt1DslExhstFldTnk2TmpPrl 4371;
BA_ "SPN" SG_ 2566733310 Aftrtrtmnt1DslExhstFldTnk2LvlPrl 4370;
BA_ "SigType" SG_ 2566733310 Aftrtrtmnt1DslExhstFldTnk2Level2 1;
BA_ "SPN" SG_ 2566733310 Aftrtrtmnt1DslExhstFldTnk2Level2 4369;
BA_ "SigType" SG_ 2566733310 Aftrtrtmnt1DslExhstFlidTank2Temp 1;
BA_ "SPN" SG_ 2566733310 Aftrtrtmnt1DslExhstFlidTank2Temp 4368;
BA_ "SigType" SG_ 2566733310 Aftrtrtmnt1DslExhstFldTank2Level 1;
BA_ "SPN" SG_ 2566733310 Aftrtrtmnt1DslExhstFldTank2Level 4367;
BA_ "SigType" SG_ 2566733054 Aftrtrtmnt1DslExhstFldTnkDrnVlvC 1;
BA_ "SPN" SG_ 2566733054 Aftrtrtmnt1DslExhstFldTnkDrnVlvC 5436;
BA_ "SigType" SG_ 2566733054 Aftrtrtmnt1DslExhstFlidPumpState 5;
BA_ "SPN" SG_ 2566733054 Aftrtrtmnt1DslExhstFlidPumpState 5435;
BA_ "SigType" SG_ 2566733054 Aftrtrtmnt1DslExhstFldTnkFllVlvC 1;
BA_ "SPN" SG_ 2566733054 Aftrtrtmnt1DslExhstFldTnkFllVlvC 5434;
BA_ "SigType" SG_ 2566733054 Aftrtrtmnt1DslExhstFldRturnValve 1;
BA_ "SPN" SG_ 2566733054 Aftrtrtmnt1DslExhstFldRturnValve 4376;
BA_ "SigType" SG_ 2566733054 Aftrtrtmnt1DslExhstFldPmpDrvPrcn 1;
BA_ "SPN" SG_ 2566733054 Aftrtrtmnt1DslExhstFldPmpDrvPrcn 4375;
BA_ "SigType" SG_ 2566733054 Aftrtrtmnt1DslExhstFldPmpMtrSped 1;
BA_ "SPN" SG_ 2566733054 Aftrtrtmnt1DslExhstFldPmpMtrSped 4374;
BA_ "SPN" SG_ 2499624702 Aftrtrtmnt1SCRCtlystOtltGsTmpPrl 4362;
BA_ "SigType" SG_ 2499624702 Aftrtrtmnt1SCRCtlystOtletGasTemp 1;
BA_ "SPN" SG_ 2499624702 Aftrtrtmnt1SCRCtlystOtletGasTemp 4363;
BA_ "SPN" SG_ 2499624702 Aftrtrtmnt1SCRCtlystIntkGsTmpPrl 4361;
BA_ "SigType" SG_ 2499624702 Aftrtrtmnt1SCRCtlystIntkeGasTemp 1;
BA_ "SPN" SG_ 2499624702 Aftrtrtmnt1SCRCtlystIntkeGasTemp 4360;
BA_ "SigType" SG_ 2566733822 Aftertreatment1SCRIntakePress 1;
BA_ "SPN" SG_ 2566733822 Aftertreatment1SCRIntakePress 6586;
BA_ "SPN" SG_ 2566733822 Aftrtrtmnt1SCRExhstGsDffPrssPrlm 4359;
BA_ "SigType" SG_ 2566733822 Aftrtrtmnt1SCRExhustGasDiffPress 1;
BA_ "SPN" SG_ 2566733822 Aftrtrtmnt1SCRExhustGasDiffPress 4358;
BA_ "SigType" SG_ 2566734078 Aftrtrtmnt1DslExhstFldPmpHterCmd 1;
BA_ "SPN" SG_ 2566734078 Aftrtrtmnt1DslExhstFldPmpHterCmd 5707;
BA_ "SigType" SG_ 2566734078 Aftrtrtmnt1DslExhstFldTnk2HtrCmd 1;
BA_ "SPN" SG_ 2566734078 Aftrtrtmnt1DslExhstFldTnk2HtrCmd 5414;
BA_ "SigType" SG_ 2566734078 Aftrtrtmnt1DslExhstFldTnkHterCmd 1;
BA_ "SPN" SG_ 2566734078 Aftrtrtmnt1DslExhstFldTnkHterCmd 5137;
BA_ "SigType" SG_ 2566734078 Aftrtrtmnt1DslExhstFldLneHeater4 5;
BA_ "SPN" SG_ 2566734078 Aftrtrtmnt1DslExhstFldLneHeater4 4357;
BA_ "SigType" SG_ 2566734078 Aftrtrtmnt1DslExhstFldLneHeater3 5;
BA_ "SPN" SG_ 2566734078 Aftrtrtmnt1DslExhstFldLneHeater3 4356;
BA_ "SigType" SG_ 2566734078 Aftrtrtmnt1DslExhstFldLneHeater2 5;
BA_ "SPN" SG_ 2566734078 Aftrtrtmnt1DslExhstFldLneHeater2 4355;
BA_ "SigType" SG_ 2566734078 Aftrtrtmnt1DslExhstFldLneHeater1 5;
BA_ "SPN" SG_ 2566734078 Aftrtrtmnt1DslExhstFldLneHeater1 4354;
BA_ "SPN" SG_ 2566734078 Aftrtrtmnt1DslExhstFldDsrHtngMdR 4353;
BA_ "SigType" SG_ 2566734078 Aftrtrtmnt1DslExhstFldDsrFltSppr 5;
BA_ "SPN" SG_ 2566734078 Aftrtrtmnt1DslExhstFldDsrFltSppr 4352;
BA_ "SigType" SG_ 2364548350 Aftrtrtmnt1DslExhstFldDsngRq6593 1;
BA_ "SPN" SG_ 2364548350 Aftrtrtmnt1DslExhstFldDsngRq6593 6593;
BA_ "SigType" SG_ 2364548350 Aftrtrtmnt1DslExhstFldRqstdQntty 1;
BA_ "SPN" SG_ 2364548350 Aftrtrtmnt1DslExhstFldRqstdQntty 4350;
BA_ "SPN" SG_ 2364548350 Aftrtrtmnt1SCRSystmRquestedState 4349;
BA_ "SigType" SG_ 2364548350 Aftrtrtmnt1DslExhstFldDsngRqstdQ 1;
BA_ "SPN" SG_ 2364548350 Aftrtrtmnt1DslExhstFldDsngRqstdQ 4348;
BA_ "SPN" SG_ 2566734334 Aftrtrtmnt1DslExhstFldLnHtr4Prlm 4347;
BA_ "SigType" SG_ 2566734334 Aftrtrtmnt1DslExhstFldLnHtr4Stte 5;
BA_ "SPN" SG_ 2566734334 Aftrtrtmnt1DslExhstFldLnHtr4Stte 4346;
BA_ "SPN" SG_ 2566734334 Aftrtrtmnt1DslExhstFldLnHtr3Prlm 4345;
BA_ "SigType" SG_ 2566734334 Aftrtrtmnt1DslExhstFldLnHtr3Stte 5;
BA_ "SPN" SG_ 2566734334 Aftrtrtmnt1DslExhstFldLnHtr3Stte 4344;
BA_ "SPN" SG_ 2566734334 Aftrtrtmnt1DslExhstFldLnHtr2Prlm 4343;
BA_ "SigType" SG_ 2566734334 Aftrtrtmnt1DslExhstFldLnHtr2Stte 5;
BA_ "SPN" SG_ 2566734334 Aftrtrtmnt1DslExhstFldLnHtr2Stte 4342;
BA_ "SPN" SG_ 2566734334 Aftrtrtmnt1DslExhstFldLnHtr1Prlm 4341;
BA_ "SigType" SG_ 2566734334 Aftrtrtmnt1DslExhstFldLnHtr1Stte 5;
BA_ "SPN" SG_ 2566734334 Aftrtrtmnt1DslExhstFldLnHtr1Stte 4340;
BA_ "SPN" SG_ 2566734334 Aftrtrtmnt1SCRFeedbackCtrlStatus 4339;
BA_ "SPN" SG_ 2566734334 Aftrtrtmnt1SCRDsngVlvExhstTmpRdc 4338;
BA_ "SigType" SG_ 2566734334 Aftrtrtmnt1DslExhstFldDosingTemp 1;
BA_ "SPN" SG_ 2566734334 Aftrtrtmnt1DslExhstFldDosingTemp 4337;
BA_ "SigType" SG_ 2566734334 Aftrtrtmnt1SCRDsngAirAssistValve 1;
BA_ "SPN" SG_ 2566734334 Aftrtrtmnt1SCRDsngAirAssistValve 4336;
BA_ "SigType" SG_ 2566734334 Aftrtrtmnt1SCRDsngArAssstAbsPrss 1;
BA_ "SPN" SG_ 2566734334 Aftrtrtmnt1SCRDsngArAssstAbsPrss 4335;
BA_ "SigType" SG_ 2364548094 Aftrtrtmnt1DslExhstFldDsrAbsPrss 1;
BA_ "SPN" SG_ 2364548094 Aftrtrtmnt1DslExhstFldDsrAbsPrss 4334;
BA_ "SigType" SG_ 2364548094 Aftrtrtmnt1DslExhstFldActlDs6595 1;
BA_ "SPN" SG_ 2364548094 Aftrtrtmnt1DslExhstFldActlDs6595 6595;
BA_ "SigType" SG_ 2364548094 Aftrtrtmnt1DslExhstFldActlQnttyO 1;
BA_ "SPN" SG_ 2364548094 Aftrtrtmnt1DslExhstFldActlQnttyO 4333;
BA_ "SPN" SG_ 2364548094 Aftertreatment1SCRSystemState 4332;
BA_ "SigType" SG_ 2364548094 Aftrtrtmnt1DslExhstFldActlDsngQn 1;
BA_ "SPN" SG_ 2364548094 Aftrtrtmnt1DslExhstFldActlDsngQn 4331;
BA_ "SigType" SG_ 2364548606 Aftrtrtmnt1OtltNH3GsSnsrHterCtrl 5;
BA_ "SPN" SG_ 2364548606 Aftrtrtmnt1OtltNH3GsSnsrHterCtrl 4383;
BA_ "SPN" SG_ 2364548606 Aftrtrtmnt1OtltNH3GsSnsrHtrPrlmn 4382;
BA_ "SigType" SG_ 2364548606 Aftrtrtmnt1OtltNH3GsSensorAtTemp 5;
BA_ "SPN" SG_ 2364548606 Aftrtrtmnt1OtltNH3GsSensorAtTemp 4381;
BA_ "SigType" SG_ 2364548606 Aftrtrtmnt1OtltNH3GsSnsrPwrInRng 5;
BA_ "SPN" SG_ 2364548606 Aftrtrtmnt1OtltNH3GsSnsrPwrInRng 4380;
BA_ "SigType" SG_ 2364548606 Aftrtrtmnt1OtletNH3ReadingStable 5;
BA_ "SPN" SG_ 2364548606 Aftrtrtmnt1OtletNH3ReadingStable 4379;
BA_ "SPN" SG_ 2364548606 Aftrtrtmnt1OtltNH3SnsrPrlmnryFMI 4378;
BA_ "SigType" SG_ 2364548606 Aftertreatment1OutletNH3 1;
BA_ "SPN" SG_ 2364548606 Aftertreatment1OutletNH3 4377;
BA_ "SPN" SG_ 2566726398 Aftrtrtmnt1GsOxdtnCtlystDffPrssP 4758;
BA_ "SPN" SG_ 2566726398 Aftrtrtmnt1GsOxdtnCtlystOtlt4757 4757;
BA_ "SPN" SG_ 2566726398 Aftrtrtmnt1GsOxdtnCtlystIntk4756 4756;
BA_ "SigType" SG_ 2566726398 Aftrtrtmnt1GsOxdtnCtlystDffPress 1;
BA_ "SPN" SG_ 2566726398 Aftrtrtmnt1GsOxdtnCtlystDffPress 4755;
BA_ "SigType" SG_ 2566726398 Aftrtrtmnt1GsOxdtnCtlystOtltGsTm 1;
BA_ "SPN" SG_ 2566726398 Aftrtrtmnt1GsOxdtnCtlystOtltGsTm 4754;
BA_ "SigType" SG_ 2566726398 Aftrtrtmnt1GsOxdtnCtlystIntkGsTm 1;
BA_ "SPN" SG_ 2566726398 Aftrtrtmnt1GsOxdtnCtlystIntkGsTm 4753;
BA_ "SPN" SG_ 2365415678 SPN1 1214;
BA_ "SPN" SG_ 2365415678 FailureModeIdentifier1 1215;
BA_ "SigType" SG_ 2365415678 FailureSpecificB1Counter 1;
BA_ "SPN" SG_ 2365415678 FailureSpecificB1Counter 4147;
BA_ "SigType" SG_ 2365415934 SysGreatestB1Counter 1;
BA_ "SPN" SG_ 2365415934 SysGreatestB1Counter 4146;
BA_ "SigType" SG_ 2365415934 SysCumulativeContinuousMITime 1;
BA_ "SPN" SG_ 2365415934 SysCumulativeContinuousMITime 4145;
BA_ "SigType" SG_ 2365416190 RegulationDescription 8;
BA_ "SPN" SG_ 2365416190 RegulationDescription 4144;
BA_ "SigType" SG_ 2365416446 SysIncompleteMonitorCount 1;
BA_ "SPN" SG_ 2365416446 SysIncompleteMonitorCount 4143;
BA_ "SPN" SG_ 2365416446 SysMalIndActivationMode 4142;
BA_ "SigType" SG_ 2365416446 SysMalIndDisplayStrategy 4;
BA_ "SPN" SG_ 2365416446 SysMalIndDisplayStrategy 4141;
BA_ "SigType" SG_ 2365416446 SysContinuousMalfunctionInd 4;
BA_ "SPN" SG_ 2365416446 SysContinuousMalfunctionInd 4140;
BA_ "SigType" SG_ 2365416446 SysNonRoadworthyCompCount 1;
BA_ "SPN" SG_ 2365416446 SysNonRoadworthyCompCount 4139;
BA_ "SigType" SG_ 2365416702 VehicleCurrentMIAccumTime 1;
BA_ "SPN" SG_ 2365416702 VehicleCurrentMIAccumTime 4138;
BA_ "SigType" SG_ 2365416702 VehicleIncompleteMonitorCount 1;
BA_ "SPN" SG_ 2365416702 VehicleIncompleteMonitorCount 4137;
BA_ "SigType" SG_ 2365416702 VehicleMalfunctionIndActMode 4;
BA_ "SPN" SG_ 2365416702 VehicleMalfunctionIndActMode 4136;
BA_ "SigType" SG_ 2365416702 VehicleMalfunctionIndStrategy 4;
BA_ "SPN" SG_ 2365416702 VehicleMalfunctionIndStrategy 4135;
BA_ "SigType" SG_ 2365416702 VehicleContinuousMalfunctionInd 4;
BA_ "SPN" SG_ 2365416702 VehicleContinuousMalfunctionInd 4134;
BA_ "SigType" SG_ 2365416702 VehicleNonRoadworthyCompCount 1;
BA_ "SPN" SG_ 2365416702 VehicleNonRoadworthyCompCount 4133;
BA_ "SigType" SG_ 2359361278 PMNTEDeficiencyAreaStatus 4;
BA_ "SPN" SG_ 2359361278 PMNTEDeficiencyAreaStatus 4132;
BA_ "SigType" SG_ 2359361278 MnfcPMNTECarveOutAreaStatus 4;
BA_ "SPN" SG_ 2359361278 MnfcPMNTECarveOutAreaStatus 4131;
BA_ "SigType" SG_ 2359361278 PMNTEControlAreaStatus 4;
BA_ "SPN" SG_ 2359361278 PMNTEControlAreaStatus 4130;
BA_ "SigType" SG_ 2359361278 NOxNTEDeficiencyAreaStatus 4;
BA_ "SPN" SG_ 2359361278 NOxNTEDeficiencyAreaStatus 4129;
BA_ "SigType" SG_ 2359361278 MnfcNOxNTECarveOutAreaStatus 4;
BA_ "SPN" SG_ 2359361278 MnfcNOxNTECarveOutAreaStatus 4128;
BA_ "SigType" SG_ 2359361278 NOxNTEControlAreaStatus 4;
BA_ "SPN" SG_ 2359361278 NOxNTEControlAreaStatus 4127;
BA_ "SigType" SG_ 2292317950 AECDEngineHours1Timer2 1;
BA_ "SPN" SG_ 2292317950 AECDEngineHours1Timer2 4126;
BA_ "SigType" SG_ 2292317950 AECDEngineHours1Timer1 1;
BA_ "SPN" SG_ 2292317950 AECDEngineHours1Timer1 4125;
BA_ "SigType" SG_ 2292317950 AECDNumber1 1;
BA_ "SPN" SG_ 2292317950 AECDNumber1 4124;
BA_ "SigType" SG_ 2566809342 BatteryMainSwitchHoldState 4;
BA_ "SPN" SG_ 2566809342 BatteryMainSwitchHoldState 1681;
BA_ "SigType" SG_ 2365446910 Joystick3XAxisDetentPosStatus 4;
BA_ "SPN" SG_ 2365446910 Joystick3XAxisDetentPosStatus 2754;
BA_ "SigType" SG_ 2365446910 Joystick3Button9PressedStatus 4;
BA_ "SPN" SG_ 2365446910 Joystick3Button9PressedStatus 2767;
BA_ "SigType" SG_ 2365446910 Joystick3Button10PressedStatus 4;
BA_ "SPN" SG_ 2365446910 Joystick3Button10PressedStatus 2768;
BA_ "SigType" SG_ 2365446910 Joystick3Button11PressedStatus 4;
BA_ "SPN" SG_ 2365446910 Joystick3Button11PressedStatus 2769;
BA_ "SigType" SG_ 2365446910 Joystick3Button12PressedStatus 4;
BA_ "SPN" SG_ 2365446910 Joystick3Button12PressedStatus 2770;
BA_ "SigType" SG_ 2365446910 Joystick3YAxisDetentPosStatus 4;
BA_ "SPN" SG_ 2365446910 Joystick3YAxisDetentPosStatus 2755;
BA_ "SPN" SG_ 2365446910 Joystick3YAxisPos 2735;
BA_ "SigType" SG_ 2365446910 Jystck3YAxsLvrFrwrdPstvPosStatus 4;
BA_ "SPN" SG_ 2365446910 Jystck3YAxsLvrFrwrdPstvPosStatus 2740;
BA_ "SigType" SG_ 2365446910 Jystck3YAxsLvrBckNgtivePosStatus 4;
BA_ "SPN" SG_ 2365446910 Jystck3YAxsLvrBckNgtivePosStatus 2745;
BA_ "SigType" SG_ 2365446910 Joystick3YAxisNeutralPosStatus 4;
BA_ "SPN" SG_ 2365446910 Joystick3YAxisNeutralPosStatus 2750;
BA_ "SPN" SG_ 2365446910 Joystick3XAxisPos 2734;
BA_ "SigType" SG_ 2365446910 Jystck3XAxsLvrRghtPstvePosStatus 4;
BA_ "SPN" SG_ 2365446910 Jystck3XAxsLvrRghtPstvePosStatus 2739;
BA_ "SigType" SG_ 2365446910 Jystck3XAxsLvrLftNgtivePosStatus 4;
BA_ "SPN" SG_ 2365446910 Jystck3XAxsLvrLftNgtivePosStatus 2744;
BA_ "SigType" SG_ 2365446910 Joystick3XAxisNeutralPosStatus 4;
BA_ "SPN" SG_ 2365446910 Joystick3XAxisNeutralPosStatus 2749;
BA_ "SigType" SG_ 2365446910 Joystick3Button5PressedStatus 4;
BA_ "SPN" SG_ 2365446910 Joystick3Button5PressedStatus 2763;
BA_ "SigType" SG_ 2365446910 Joystick3Button6PressedStatus 4;
BA_ "SPN" SG_ 2365446910 Joystick3Button6PressedStatus 2764;
BA_ "SigType" SG_ 2365446910 Joystick3Button7PressedStatus 4;
BA_ "SPN" SG_ 2365446910 Joystick3Button7PressedStatus 2765;
BA_ "SigType" SG_ 2365446910 Joystick3Button8PressedStatus 4;
BA_ "SPN" SG_ 2365446910 Joystick3Button8PressedStatus 2766;
BA_ "SigType" SG_ 2365446910 Joystick3Button1PressedStatus 4;
BA_ "SPN" SG_ 2365446910 Joystick3Button1PressedStatus 2759;
BA_ "SigType" SG_ 2365446910 Joystick3Button2PressedStatus 4;
BA_ "SPN" SG_ 2365446910 Joystick3Button2PressedStatus 2760;
BA_ "SigType" SG_ 2365446910 Joystick3Button3PressedStatus 4;
BA_ "SPN" SG_ 2365446910 Joystick3Button3PressedStatus 2761;
BA_ "SigType" SG_ 2365446910 Joystick3Button4PressedStatus 4;
BA_ "SPN" SG_ 2365446910 Joystick3Button4PressedStatus 2762;
BA_ "SigType" SG_ 2365446398 Joystick2XAxisDetentPosStatus 4;
BA_ "SPN" SG_ 2365446398 Joystick2XAxisDetentPosStatus 2717;
BA_ "SigType" SG_ 2365446398 Joystick2YAxisDetentPosStatus 4;
BA_ "SPN" SG_ 2365446398 Joystick2YAxisDetentPosStatus 2718;
BA_ "SPN" SG_ 2365446398 Joystick2YAxisPos 2698;
BA_ "SigType" SG_ 2365446398 Jystck2YAxsLvrFrwrdPstvPosStatus 4;
BA_ "SPN" SG_ 2365446398 Jystck2YAxsLvrFrwrdPstvPosStatus 2703;
BA_ "SigType" SG_ 2365446398 Jystck2YAxsLvrBckNgtivePosStatus 4;
BA_ "SPN" SG_ 2365446398 Jystck2YAxsLvrBckNgtivePosStatus 2708;
BA_ "SigType" SG_ 2365446398 Joystick2YAxisNeutralPosStatus 4;
BA_ "SPN" SG_ 2365446398 Joystick2YAxisNeutralPosStatus 2713;
BA_ "SPN" SG_ 2365446398 Joystick2XAxisPos 2697;
BA_ "SigType" SG_ 2365446398 Jystck2XAxsLvrRghtPstvePosStatus 4;
BA_ "SPN" SG_ 2365446398 Jystck2XAxsLvrRghtPstvePosStatus 2702;
BA_ "SigType" SG_ 2365446398 Jystck2XAxsLvrLftNgtivePosStatus 4;
BA_ "SPN" SG_ 2365446398 Jystck2XAxsLvrLftNgtivePosStatus 2707;
BA_ "SigType" SG_ 2365446398 Joystick2XAxisNeutralPosStatus 4;
BA_ "SPN" SG_ 2365446398 Joystick2XAxisNeutralPosStatus 2712;
BA_ "SigType" SG_ 2365446398 Joystick2Button9PressedStatus 4;
BA_ "SPN" SG_ 2365446398 Joystick2Button9PressedStatus 2730;
BA_ "SigType" SG_ 2365446398 Joystick2Button10PressedStatus 4;
BA_ "SPN" SG_ 2365446398 Joystick2Button10PressedStatus 2731;
BA_ "SigType" SG_ 2365446398 Joystick2Button11PressedStatus 4;
BA_ "SPN" SG_ 2365446398 Joystick2Button11PressedStatus 2732;
BA_ "SigType" SG_ 2365446398 Joystick2Button12PressedStatus 4;
BA_ "SPN" SG_ 2365446398 Joystick2Button12PressedStatus 2733;
BA_ "SigType" SG_ 2365446398 Joystick2Button5PressedStatus 4;
BA_ "SPN" SG_ 2365446398 Joystick2Button5PressedStatus 2726;
BA_ "SigType" SG_ 2365446398 Joystick2Button6PressedStatus 4;
BA_ "SPN" SG_ 2365446398 Joystick2Button6PressedStatus 2727;
BA_ "SigType" SG_ 2365446398 Joystick2Button7PressedStatus 4;
BA_ "SPN" SG_ 2365446398 Joystick2Button7PressedStatus 2728;
BA_ "SigType" SG_ 2365446398 Joystick2Button8PressedStatus 4;
BA_ "SPN" SG_ 2365446398 Joystick2Button8PressedStatus 2729;
BA_ "SigType" SG_ 2365446398 Joystick2Button1PressedStatus 4;
BA_ "SPN" SG_ 2365446398 Joystick2Button1PressedStatus 2722;
BA_ "SigType" SG_ 2365446398 Joystick2Button2PressedStatus 4;
BA_ "SPN" SG_ 2365446398 Joystick2Button2PressedStatus 2723;
BA_ "SigType" SG_ 2365446398 Joystick2Button3PressedStatus 4;
BA_ "SPN" SG_ 2365446398 Joystick2Button3PressedStatus 2724;
BA_ "SigType" SG_ 2365446398 Joystick2Button4PressedStatus 4;
BA_ "SPN" SG_ 2365446398 Joystick2Button4PressedStatus 2725;
BA_ "SigType" SG_ 2365445886 Joystick1XAxisDetentPosStatus 4;
BA_ "SPN" SG_ 2365445886 Joystick1XAxisDetentPosStatus 2680;
BA_ "SigType" SG_ 2365445886 Joystick1YAxisDetentPosStatus 4;
BA_ "SPN" SG_ 2365445886 Joystick1YAxisDetentPosStatus 2681;
BA_ "SPN" SG_ 2365445886 Joystick1YAxisPos 2661;
BA_ "SigType" SG_ 2365445886 Jystck1YAxsLvrFrwrdPstvPosStatus 4;
BA_ "SPN" SG_ 2365445886 Jystck1YAxsLvrFrwrdPstvPosStatus 2666;
BA_ "SigType" SG_ 2365445886 Jystck1YAxsLvrBckNgtivePosStatus 4;
BA_ "SPN" SG_ 2365445886 Jystck1YAxsLvrBckNgtivePosStatus 2671;
BA_ "SigType" SG_ 2365445886 Joystick1YAxisNeutralPosStatus 4;
BA_ "SPN" SG_ 2365445886 Joystick1YAxisNeutralPosStatus 2676;
BA_ "SPN" SG_ 2365445886 Joystick1XAxisPos 2660;
BA_ "SigType" SG_ 2365445886 Joystick1Button9PressedStatus 4;
BA_ "SPN" SG_ 2365445886 Joystick1Button9PressedStatus 2693;
BA_ "SigType" SG_ 2365445886 Joystick1Button10PressedStatus 4;
BA_ "SPN" SG_ 2365445886 Joystick1Button10PressedStatus 2694;
BA_ "SigType" SG_ 2365445886 Joystick1Button11PressedStatus 4;
BA_ "SPN" SG_ 2365445886 Joystick1Button11PressedStatus 2695;
BA_ "SigType" SG_ 2365445886 Joystick1Button12PressedStatus 4;
BA_ "SPN" SG_ 2365445886 Joystick1Button12PressedStatus 2696;
BA_ "SigType" SG_ 2365445886 Joystick1Button5PressedStatus 4;
BA_ "SPN" SG_ 2365445886 Joystick1Button5PressedStatus 2689;
BA_ "SigType" SG_ 2365445886 Joystick1Button6PressedStatus 4;
BA_ "SPN" SG_ 2365445886 Joystick1Button6PressedStatus 2690;
BA_ "SigType" SG_ 2365445886 Joystick1Button7PressedStatus 4;
BA_ "SPN" SG_ 2365445886 Joystick1Button7PressedStatus 2691;
BA_ "SigType" SG_ 2365445886 Joystick1Button8PressedStatus 4;
BA_ "SPN" SG_ 2365445886 Joystick1Button8PressedStatus 2692;
BA_ "SigType" SG_ 2365445886 Joystick1Button1PressedStatus 4;
BA_ "SPN" SG_ 2365445886 Joystick1Button1PressedStatus 2685;
BA_ "SigType" SG_ 2365445886 Joystick1Button2PressedStatus 4;
BA_ "SPN" SG_ 2365445886 Joystick1Button2PressedStatus 2686;
BA_ "SigType" SG_ 2365445886 Joystick1Button3PressedStatus 4;
BA_ "SPN" SG_ 2365445886 Joystick1Button3PressedStatus 2687;
BA_ "SigType" SG_ 2365445886 Joystick1Button4PressedStatus 4;
BA_ "SPN" SG_ 2365445886 Joystick1Button4PressedStatus 2688;
BA_ "SigType" SG_ 2365445886 Jystck1XAxsLvrRghtPstvePosStatus 4;
BA_ "SPN" SG_ 2365445886 Jystck1XAxsLvrRghtPstvePosStatus 2665;
BA_ "SigType" SG_ 2365445886 Jystck1XAxsLvrLftNgtivePosStatus 4;
BA_ "SPN" SG_ 2365445886 Jystck1XAxsLvrLftNgtivePosStatus 2670;
BA_ "SigType" SG_ 2365445886 Joystick1XAxisNeutralPosStatus 4;
BA_ "SPN" SG_ 2365445886 Joystick1XAxisNeutralPosStatus 2675;
VAL_ 2365400318 Joystick10Button9PressedStatus 3 "Not Available" 2 "Error Indicator" 1 "Button pressed" 0 "Button not pressed" ;
VAL_ 2365400318 Joystick10Button10PressedStatus 3 "Not Available" 2 "Error Indicator" 1 "Button pressed" 0 "Button not pressed" ;
VAL_ 2365400318 Joystick10Button11PressedStatus 3 "Not Available" 2 "Error Indicator" 1 "Button pressed" 0 "Button not pressed" ;
VAL_ 2365400318 Joystick10Button12PressedStatus 3 "Not Available" 2 "Error Indicator" 1 "Button pressed" 0 "Button not pressed" ;
VAL_ 2365400318 Joystick10Button5PressedStatus 3 "Not Available" 2 "Error Indicator" 1 "Button pressed" 0 "Button not pressed" ;
VAL_ 2365400318 Joystick10Button6PressedStatus 3 "Not Available" 2 "Error Indicator" 1 "Button pressed" 0 "Button not pressed" ;
VAL_ 2365400318 Joystick10Button7PressedStatus 3 "Not Available" 2 "Error Indicator" 1 "Button pressed" 0 "Button not pressed" ;
VAL_ 2365400318 Joystick10Button8PressedStatus 3 "Not Available" 2 "Error Indicator" 1 "Button pressed" 0 "Button not pressed" ;
VAL_ 2365400318 Joystick10Button1PressedStatus 3 "Not Available" 2 "Error Indicator" 1 "Button pressed" 0 "Button not pressed" ;
VAL_ 2365400318 Joystick10Button2PressedStatus 3 "Not Available" 2 "Error Indicator" 1 "Button pressed" 0 "Button not pressed" ;
VAL_ 2365400318 Joystick10Button3PressedStatus 3 "Not Available" 2 "Error Indicator" 1 "Button pressed" 0 "Button not pressed" ;
VAL_ 2365400318 Joystick10Button4PressedStatus 3 "Not Available" 2 "Error Indicator" 1 "Button pressed" 0 "Button not pressed" ;
VAL_ 2365400318 Joystick10XAxisDetentPosStatus 3 "Not Available" 2 "Error Indicator" 1 "In the Detent Position" 0 "Not in the Detent Position" ;
VAL_ 2365400318 Joystick10YAxisDetentPosStatus 3 "Not Available" 2 "Error Indicator" 1 "In the Detent Position" 0 "Not in the Detent Position" ;
VAL_ 2365400318 Jystck10YAxsLvrFrwrdPstvPsStatus 3 "Not Available" 2 "Error Indicator" 1 "On positive side of Neutral" 0 "Not on Positive side of Neutral" ;
VAL_ 2365400318 Jystck10YAxsLvrBckNgtvePosStatus 3 "Not Available" 2 "Error Indicator" 1 "On negative side of Neutral" 0 "Not on negative side of Neutral" ;
VAL_ 2365400318 Joystick10YAxisNeutralPosStatus 3 "Not Available" 2 "Error Indicator" 1 "In Neutral Position" 0 "Not in Neutral Position" ;
VAL_ 2365400318 Jystck10XAxsLvrRghtPstvPosStatus 3 "Not Available" 2 "Error Indicator" 1 "On positive side of Neutral" 0 "Not on Positive side of Neutral" ;
VAL_ 2365400318 Jystck10XAxsLvrLftNgtvePosStatus 3 "Not Available" 2 "Error Indicator" 1 "On negative side of Neutral" 0 "Not on negative side of Neutral" ;
VAL_ 2365400318 Joystick10XAxisNeutralPosStatus 3 "Not Available" 2 "Error Indicator" 1 "In Neutral Position" 0 "Not in Neutral Position" ;
VAL_ 2499614718 PssngrArbgDctivationSwitchStatus 3 "not available" 2 "Error  State of deactivation switch cannot be determined" 1 "passenger airbag deactivated" 0 "passenger airbag activated" ;
VAL_ 2499614718 Beltlock10Status 3 "not available" 2 "Error  Beltlock state cannot be determined" 1 "locked" 0 "unlocked" ;
VAL_ 2499614718 Beltlock9Status 3 "not available" 2 "Error  Beltlock state cannot be determined" 1 "locked" 0 "unlocked" ;
VAL_ 2499614718 Beltlock8Status 3 "not available" 2 "Error  Beltlock state cannot be determined" 1 "locked" 0 "unlocked" ;
VAL_ 2499614718 Beltlock7Status 3 "not available" 2 "Error  Beltlock state cannot be determined" 1 "locked" 0 "unlocked" ;
VAL_ 2499614718 Beltlock6Status 3 "not available" 2 "Error  Beltlock state cannot be determined" 1 "locked" 0 "unlocked" ;
VAL_ 2499614718 Beltlock5Status 3 "not available" 2 "Error  Beltlock state cannot be determined" 1 "locked" 0 "unlocked" ;
VAL_ 2499614718 Beltlock4Status 3 "not available" 2 "Error  Beltlock state cannot be determined" 1 "locked" 0 "unlocked" ;
VAL_ 2499614718 Beltlock3Status 3 "not available" 2 "Error  Beltlock state cannot be determined" 1 "locked" 0 "unlocked" ;
VAL_ 2499614718 PassengerBeltlockStatus 3 "not available" 2 "Error  Beltlock state cannot be determined" 1 "locked" 0 "unlocked" ;
VAL_ 2499614718 DriverBeltlockStatus 3 "not available" 2 "Error  Beltlock state cannot be determined" 1 "locked" 0 "unlocked" ;
VAL_ 2566722814 BatteryCharger2PowerLineState 3 "Not available" 2 "Error" 1 "Connected. The power line is connected to the charger." 0 "Disconnected. The power line is disconnected from the charger." ;
VAL_ 2566722814 BatteryCharger2State 15 "Not available." 14 "Charger failure. An error condition due to the charger state." 13 "Battery failure. An error condition due to the battery state (high temperature, etc.)" 2 "Stand-by or maintaining the battery charge." 1 "Charging the battery." 0 "Idling. The power line or the battery is disconnected from the charger." ;
VAL_ 2566723070 BatteryCharger1PowerLineState 3 "Not available" 2 "Error" 1 "Connected. The power line is connected to the charger." 0 "Disconnected. The power line is disconnected from the charger." ;
VAL_ 2566723070 BatteryCharger1State 15 "Not available." 14 "Charger failure. An error condition due to the charger state." 13 "Battery failure. An error condition due to the battery state (high temperature, etc.)" 2 "Stand-by or maintaining the battery charge." 1 "Charging the battery." 0 "Idling. The power line or the battery is disconnected from the charger." ;
VAL_ 2566735102 Aftrtrtmnt2FlFlwDverterValveCtrl 3 "not available" 2 "reserved for SAE assignment" 1 "on" 0 "off" ;
VAL_ 2566735102 Aftertreatment2FuelPumpRelayCtrl 3 "not available" 2 "reserved for SAE assignment" 1 "on" 0 "off" ;
VAL_ 2566805246 AftrtrtmntSCROprtrIndcmntSverity 7 "Not Available / Not Supported" 6 "Reserved" 5 "Inducement Level 5" 4 "Inducement Level 4" 3 "Inducement Level 3" 2 "Inducement Level 2" 1 "Inducement Level 1" 0 "No Inducement Active" ;
VAL_ 2566805246 AftrtrtmntSlctvCtlytcRdctnOprtrI 5 "reserved for SAE assignment" 3 "reserved for SAE assignment" 2 "reserved for SAE assignment" 7 "not available" 4 "On  fast blink 1 HZ" 6 "reserved for SAE assignment" 1 "On  solid" 0 "Off" ;
VAL_ 2566711806 Armrest2Switch2 3 "Dont care/take no action" 2 "Reserved" 1 "On" 0 "Off" ;
VAL_ 2566711806 Armrest2Switch1 3 "Dont care/take no action" 2 "Reserved" 1 "On" 0 "Off" ;
VAL_ 2566711806 Armrest1Switch2 3 "Dont care/take no action" 2 "Reserved" 1 "On" 0 "Off" ;
VAL_ 2566711806 Armrest1Switch1 3 "Dont care/take no action" 2 "Reserved" 1 "On" 0 "Off" ;
VAL_ 2364549886 YawRateExRangeFigureOfMerit 3 "Not available" 2 "Error" 1 "Yaw rate degraded Data is suspect due to environmental conditions" 0 "Yaw rate fully functional Data is within sensor specification" ;
VAL_ 2364549886 RollRateExRangeFigureOfMerit 3 "Not available" 2 "Error" 1 "Roll rate degraded Data is suspect due to environmental conditions" 0 "Roll rate fully functional Data is within sensor specification" ;
VAL_ 2364549886 PitchRateExRangeFigureOfMerit 3 "Not available" 2 "Error" 1 "Pitch rate degraded Data is suspect due to environmental conditions" 0 "Pitch rate fully functional Data is within sensor specification" ;
VAL_ 2566712318 Aftrtrtmnt2NOxAdsrbrDSOxRgnrtnSt 3 "Not available" 2 "Error indicator" 1 "Active" 0 "Inactive" ;
VAL_ 2566712318 Aftrtrtmnt2NOxAdsrbrDNOxRgnrtnSt 3 "Not available" 2 "Error indicator" 1 "Active" 0 "Inactive" ;
VAL_ 2566712574 Aftrtrtmnt1NOxAdsrbrDSOxRgnrtnSt 3 "Not available" 2 "Error indicator" 1 "Active" 0 "Inactive" ;
VAL_ 2566712574 Aftrtrtmnt1NOxAdsrbrDNOxRgnrtnSt 3 "Not available" 2 "Error indicator" 1 "Active" 0 "Inactive" ;
VAL_ 2566730750 Aftrtrtmnt2DslExhstFlidPumpState 3 "not available" 2 "reserved for SAE assignment" 1 "pump error" 0 "pump operational" ;
VAL_ 2566731518 Aftrtrtmnt2DeselExhaustFluidType 15 "Not available" 14 "Error detected with urea reagent type detection" 13 "Not able to determine catalyst reagent type type unknown" 3 "Catalyst reagent is proper mixture" 2 "Catalyst reagent is diesel" 1 "Catalyst reagent is urea concentration too low" 0 "Catalyst reagent is urea concentration too high" ;
VAL_ 2164079358 Aftrtrtmnt2DslExhstFldLneHeater4 3 "not available" 2 "reserved for future assignment by SAE" 1 "request for heater to be active" 0 "request for heater to be inactive" ;
VAL_ 2164079358 Aftrtrtmnt2DslExhstFldLneHeater3 3 "not available" 2 "reserved for future assignment by SAE" 1 "request for heater to be active" 0 "request for heater to be inactive" ;
VAL_ 2164079358 Aftrtrtmnt2DslExhstFldLneHeater2 3 "not available" 2 "reserved for future assignment by SAE" 1 "request for heater to be active" 0 "request for heater to be inactive" ;
VAL_ 2164079358 Aftrtrtmnt2DslExhstFldLneHeater1 3 "not available" 2 "reserved for future assignment by SAE" 1 "request for heater to be active" 0 "request for heater to be inactive" ;
VAL_ 2164079358 Aftrtrtmnt2DslExhstFldDsrHtngMdR 7 "Not available" 3 "Heater on" 2 "Heater automatic mode" 1 "Heater economy mode" 0 "Heater off" ;
VAL_ 2164079358 Aftrtrtmnt2DslExhstFldDsrFltSppr 3 "Not available" 2 "Reserved" 1 "Error suppression on" 0 "Error suppression off" ;
VAL_ 2364549118 Aftrtrtmnt2SCRSystmRquestedState 15 "Not available" 14 "Error" 10 "Service test mode dosing not allowed" 9 "Service test mode dosing allowed" 8 "Diagnosis afterrun" 7 "Shutoff wait for afterrun" 6 "Protect mode against cold defreeze" 5 "Protect mode against heat pressure buildup" 4 "Reserved for future assignment by SAE" 3 "System error pending" 2 "Normal dosing operation" 1 "Preparing dosing readiness wake up prepare to operate wait for start" 0 "Dormant sleep mode" ;
VAL_ 2566732798 Aftrtrtmnt2DslExhstFldLnHtr4Stte 3 "not available" 2 "error" 1 "heater active" 0 "heater inactive" ;
VAL_ 2566732798 Aftrtrtmnt2DslExhstFldLnHtr3Stte 3 "not available" 2 "error" 1 "heater active" 0 "heater inactive" ;
VAL_ 2566732798 Aftrtrtmnt2DslExhstFldLnHtr2Stte 3 "not available" 2 "error" 1 "heater active" 0 "heater inactive" ;
VAL_ 2566732798 Aftrtrtmnt2DslExhstFldLnHtr1Stte 3 "not available" 2 "error" 1 "heater active" 0 "heater inactive" ;
VAL_ 2566732798 Aftrtrtmnt2SCRFeedbackCtrlStatus 4 "reserved for future assignment by SAE" 3 "reserved for future assignment by SAE" 2 "reserved for future assignment by SAE" 7 "not available" 6 "error" 5 "reserved for future assignment by SAE" 1 "closed loop control active" 0 "open loop control active" ;
VAL_ 2566732798 Aftrtrtmnt2SCRDsngVlvExhstTmpRdc 7 "not available" 6 "error" 5 "reserved for future assignment by SAE" 4 "reserved for future assignment by SAE" 3 "reserved for future assignment by SAE" 2 "reduction request stage 2" 1 "reduction request stage 1" 0 "no request" ;
VAL_ 2364548862 Aftertreatment2SCRSystemState 15 "Not available" 14 "Error" 11 "Ok to Power Down (SCR dosing system has complete housekeeping and power may safely be removed)" 10 "Service test mode, dosing not allowed" 9 "Service test mode, dosing allowed " 8 "Diagnosis (after-run)" 7 "Shutoff (wait for after-run) " 6 "Protect mode against cold (defreeze) " 5 "Protect mode against heat (pressure buildup) " 4 "Reserved for future assignment by SAE" 3 "System error pending" 2 "Normal dosing operation" 1 "Preparing dosing readiness (wake up; prepare to operate; wait for start)" 0 "Dormant (sleep mode)" ;
VAL_ 2364549374 Aftrtrtmnt2OtltNH3GsSnsrHterCtrl 3 "Heater off or Not available" 2 "Preheat 1" 1 "Preheat 2" 0 "Automatic" ;
VAL_ 2364549374 Aftrtrtmnt2OtltNH3GsSensorAtTemp 3 "Not available" 2 "Error" 1 "Heater element is in range" 0 "Heater element is not in range" ;
VAL_ 2364549374 Aftrtrtmnt2OtltNH3GsSnsrPwrInRng 3 "Not available" 2 "Error" 1 "Heater element is in range" 0 "Heater element is not in range" ;
VAL_ 2364549374 Aftrtrtmnt2OtletNH3ReadingStable 3 "Not available" 2 "Error" 1 "Reading is stable" 0 "Reading is not stable" ;
VAL_ 2566733054 Aftrtrtmnt1DslExhstFlidPumpState 3 "not available" 2 "reserved for SAE assignment" 1 "pump error" 0 "pump operational" ;
VAL_ 2566734078 Aftrtrtmnt1DslExhstFldLneHeater4 3 "not available" 2 "reserved for future assignment by SAE" 1 "request for heater to be active" 0 "request for heater to be inactive" ;
VAL_ 2566734078 Aftrtrtmnt1DslExhstFldLneHeater3 3 "not available" 2 "reserved for future assignment by SAE" 1 "request for heater to be active" 0 "request for heater to be inactive" ;
VAL_ 2566734078 Aftrtrtmnt1DslExhstFldLneHeater2 3 "not available" 2 "reserved for future assignment by SAE" 1 "request for heater to be active" 0 "request for heater to be inactive" ;
VAL_ 2566734078 Aftrtrtmnt1DslExhstFldLneHeater1 3 "not available" 2 "reserved for future assignment by SAE" 1 "request for heater to be active" 0 "request for heater to be inactive" ;
VAL_ 2566734078 Aftrtrtmnt1DslExhstFldDsrHtngMdR 7 "Not available" 3 "Heater on" 2 "Heater automatic mode" 1 "Heater economy mode" 0 "Heater off" ;
VAL_ 2566734078 Aftrtrtmnt1DslExhstFldDsrFltSppr 3 "Not available" 2 "Reserved" 1 "Error suppression on" 0 "Error suppression off" ;
VAL_ 2364548350 Aftrtrtmnt1SCRSystmRquestedState 15 "Not available" 14 "Error" 10 "Service test mode dosing not allowed" 9 "Service test mode dosing allowed" 8 "Diagnosis afterrun" 7 "Shutoff wait for afterrun" 6 "Protect mode against cold defreeze" 5 "Protect mode against heat pressure buildup" 4 "Reserved for future assignment by SAE" 3 "System error pending" 2 "Normal dosing operation" 1 "Preparing dosing readiness wake up prepare to operate wait for start" 0 "Dormant sleep mode" ;
VAL_ 2566734334 Aftrtrtmnt1DslExhstFldLnHtr4Stte 3 "not available" 2 "error" 1 "heater active" 0 "heater inactive" ;
VAL_ 2566734334 Aftrtrtmnt1DslExhstFldLnHtr3Stte 3 "not available" 2 "error" 1 "heater active" 0 "heater inactive" ;
VAL_ 2566734334 Aftrtrtmnt1DslExhstFldLnHtr2Stte 3 "not available" 2 "error" 1 "heater active" 0 "heater inactive" ;
VAL_ 2566734334 Aftrtrtmnt1DslExhstFldLnHtr1Stte 3 "not available" 2 "error" 1 "heater active" 0 "heater inactive" ;
VAL_ 2566734334 Aftrtrtmnt1SCRFeedbackCtrlStatus 7 "not available" 4 "reserved for future assignment by SAE" 3 "reserved for future assignment by SAE" 2 "reserved for future assignment by SAE" 6 "error" 5 "reserved for future assignment by SAE" 1 "closed loop control active" 0 "open loop control active" ;
VAL_ 2566734334 Aftrtrtmnt1SCRDsngVlvExhstTmpRdc 7 "not available" 6 "error" 5 "reserved for future assignment by SAE" 4 "reserved for future assignment by SAE" 3 "reserved for future assignment by SAE" 2 "reduction request stage 2" 1 "reduction request stage 1" 0 "no request" ;
VAL_ 2364548094 Aftertreatment1SCRSystemState 15 "Not available" 14 "Error" 11 "Ok to Power Down (SCR dosing system has complete housekeeping and power may safely be removed.)" 10 "Service test mode, dosing not allowed" 9 "Service test mode, dosing allowed " 8 "Diagnosis (after-run)" 7 "Shutoff  (wait for after-run)" 6 "Protect mode against cold  (defreeze)" 5 "Protect mode against heat  (pressure buildup)" 4 "Purging (SCR dosing system is removing residual DEF from system prior to shutdown)" 3 "System error pending" 2 "Normal dosing operation" 1 "Preparing dosing readiness (wake up; prepare to operate; wait for start)" 0 "Dormant (sleep mode)" ;
VAL_ 2364548606 Aftrtrtmnt1OtltNH3GsSnsrHterCtrl 3 "Heater off or not available" 2 "Preheat 1" 1 "Preheat 2" 0 "Automatic" ;
VAL_ 2364548606 Aftrtrtmnt1OtltNH3GsSensorAtTemp 3 "Not available" 2 "Error" 1 "Heater element is in range" 0 "Heater element is not in range" ;
VAL_ 2364548606 Aftrtrtmnt1OtltNH3GsSnsrPwrInRng 3 "Not available" 2 "Error" 1 "Power is in range" 0 "Power is not in range" ;
VAL_ 2364548606 Aftrtrtmnt1OtletNH3ReadingStable 3 "Not available" 2 "Error" 1 "Reading is stable" 0 "Reading is not stable" ;
VAL_ 2365415678 FailureModeIdentifier1 31 "Not available" 19 "Received network data in error" 18 "Below normal (moderately severe)" 17 "Below normal (least severe)" 16 "Above normal (moderately severe)" 15 "Above normal (least severe)" 14 "Special intstructions" 13 "Out of calibration" 12 "Bad intelligent device" 11 "Root cause not known" 10 "Abnormal rate of change" 9 "Abnormal update rate" 8 "Abnormal frequency" 7 "Mechanical system not responding" 6 "Current above normal" 5 "Current below normal" 4 "Voltage below normal" 3 "Voltage above normal" 2 "Data erratic" 1 "Below normal (most severe)" 0 "Above normal (most severe)" ;
VAL_ 2359361278 PMNTEDeficiencyAreaStatus 3 "NotAvailable" 2 "Reserved" 1 "InsideControlArea" 0 "OutsideControlArea" ;
VAL_ 2359361278 MnfcPMNTECarveOutAreaStatus 3 "NotAvailable" 2 "Reserved" 1 "InsideControlArea" 0 "OutsideControlArea" ;
VAL_ 2359361278 PMNTEControlAreaStatus 3 "NotAvailable" 2 "Reserved" 1 "InsideControlArea" 0 "OutsideControlArea" ;
VAL_ 2359361278 NOxNTEDeficiencyAreaStatus 3 "NotAvailable" 2 "Reserved" 1 "InsideControlArea" 0 "OutsideControlArea" ;
VAL_ 2359361278 MnfcNOxNTECarveOutAreaStatus 3 "NotAvailable" 2 "Reserved" 1 "InsideControlArea" 0 "OutsideControlArea" ;
VAL_ 2359361278 NOxNTEControlAreaStatus 3 "NotAvailable" 2 "Reserved" 1 "InsideControlArea" 0 "OutsideControlArea" ;
VAL_ 2566809342 BatteryMainSwitchHoldState 3 "Dont care/take no action" 2 "Reserved" 1 "Battery main switch held" 0 "Battery main switch not held" ;
VAL_ 2365446910 Joystick3XAxisDetentPosStatus 3 "Not Available" 2 "Error Indicator" 1 "In the Detent Position" 0 "Not in the Detent Position" ;
VAL_ 2365446910 Joystick3Button9PressedStatus 3 "Not Available" 2 "Error Indicator" 1 "Button pressed" 0 "Button not pressed" ;
VAL_ 2365446910 Joystick3Button10PressedStatus 3 "Not Available" 2 "Error Indicator" 1 "Button pressed" 0 "Button not pressed" ;
VAL_ 2365446910 Joystick3Button11PressedStatus 3 "Not Available" 2 "Error Indicator" 1 "Button pressed" 0 "Button not pressed" ;
VAL_ 2365446910 Joystick3Button12PressedStatus 3 "Not Available" 2 "Error Indicator" 1 "Button pressed" 0 "Button not pressed" ;
VAL_ 2365446910 Joystick3YAxisDetentPosStatus 3 "Not Available" 2 "Error Indicator" 1 "In the Detent Position" 0 "Not in the Detent Position" ;
VAL_ 2365446910 Jystck3YAxsLvrFrwrdPstvPosStatus 3 "Not Available" 2 "Error Indicator" 1 "On positive side of Neutral" 0 "Not on Positive side of Neutral" ;
VAL_ 2365446910 Jystck3YAxsLvrBckNgtivePosStatus 3 "Not Available" 2 "Error Indicator" 1 "On negative side of Neutral" 0 "Not on negative side of Neutral" ;
VAL_ 2365446910 Joystick3YAxisNeutralPosStatus 3 "Not Available" 2 "Error Indicator" 1 "In Neutral Position" 0 "Not in Neutral Position" ;
VAL_ 2365446910 Jystck3XAxsLvrRghtPstvePosStatus 3 "Not Available" 2 "Error Indicator" 1 "On positive side of Neutral" 0 "Not on Positive side of Neutral" ;
VAL_ 2365446910 Jystck3XAxsLvrLftNgtivePosStatus 3 "Not Available" 2 "Error Indicator" 1 "On negative side of Neutral" 0 "Not on negative side of Neutral" ;
VAL_ 2365446910 Joystick3XAxisNeutralPosStatus 3 "Not Available" 2 "Error Indicator" 1 "In Neutral Position" 0 "Not in Neutral Position" ;
VAL_ 2365446910 Joystick3Button5PressedStatus 3 "Not Available" 2 "Error Indicator" 1 "Button pressed" 0 "Button not pressed" ;
VAL_ 2365446910 Joystick3Button6PressedStatus 3 "Not Available" 2 "Error Indicator" 1 "Button pressed" 0 "Button not pressed" ;
VAL_ 2365446910 Joystick3Button7PressedStatus 3 "Not Available" 2 "Error Indicator" 1 "Button pressed" 0 "Button not pressed" ;
VAL_ 2365446910 Joystick3Button8PressedStatus 3 "Not Available" 2 "Error Indicator" 1 "Button pressed" 0 "Button not pressed" ;
VAL_ 2365446910 Joystick3Button1PressedStatus 3 "Not Available" 2 "Error Indicator" 1 "Button pressed" 0 "Button not pressed" ;
VAL_ 2365446910 Joystick3Button2PressedStatus 3 "Not Available" 2 "Error Indicator" 1 "Button pressed" 0 "Button not pressed" ;
VAL_ 2365446910 Joystick3Button3PressedStatus 3 "Not Available" 2 "Error Indicator" 1 "Button pressed" 0 "Button not pressed" ;
VAL_ 2365446910 Joystick3Button4PressedStatus 3 "Not Available" 2 "Error Indicator" 1 "Button pressed" 0 "Button not pressed" ;
VAL_ 2365446398 Joystick2XAxisDetentPosStatus 3 "Not Available" 2 "Error Indicator" 1 "In the Detent Position" 0 "Not in the Detent Position" ;
VAL_ 2365446398 Joystick2YAxisDetentPosStatus 3 "Not Available" 2 "Error Indicator" 1 "In the Detent Position" 0 "Not in the Detent Position" ;
VAL_ 2365446398 Jystck2YAxsLvrFrwrdPstvPosStatus 3 "Not Available" 2 "Error Indicator" 1 "On positive side of Neutral" 0 "Not on Positive side of Neutral" ;
VAL_ 2365446398 Jystck2YAxsLvrBckNgtivePosStatus 3 "Not Available" 2 "Error Indicator" 1 "On negative side of Neutral" 0 "Not on negative side of Neutral" ;
VAL_ 2365446398 Joystick2YAxisNeutralPosStatus 3 "Not Available" 2 "Error Indicator" 1 "In Neutral Position" 0 "Not in Neutral Position" ;
VAL_ 2365446398 Jystck2XAxsLvrRghtPstvePosStatus 3 "Not Available" 2 "Error Indicator" 1 "On positive side of Neutral" 0 "Not on Positive side of Neutral" ;
VAL_ 2365446398 Jystck2XAxsLvrLftNgtivePosStatus 3 "Not Available" 2 "Error Indicator" 1 "On negative side of Neutral" 0 "Not on negative side of Neutral" ;
VAL_ 2365446398 Joystick2XAxisNeutralPosStatus 3 "Not Available" 2 "Error Indicator" 1 "In Neutral Position" 0 "Not in Neutral Position" ;
VAL_ 2365446398 Joystick2Button9PressedStatus 3 "Not Available" 2 "Error Indicator" 1 "Button pressed" 0 "Button not pressed" ;
VAL_ 2365446398 Joystick2Button10PressedStatus 3 "Not Available" 2 "Error Indicator" 1 "Button pressed" 0 "Button not pressed" ;
VAL_ 2365446398 Joystick2Button11PressedStatus 3 "Not Available" 2 "Error Indicator" 1 "Button pressed" 0 "Button not pressed" ;
VAL_ 2365446398 Joystick2Button12PressedStatus 3 "Not Available" 2 "Error Indicator" 1 "Button pressed" 0 "Button not pressed" ;
VAL_ 2365446398 Joystick2Button5PressedStatus 3 "Not Available" 2 "Error Indicator" 1 "Button pressed" 0 "Button not pressed" ;
VAL_ 2365446398 Joystick2Button6PressedStatus 3 "Not Available" 2 "Error Indicator" 1 "Button pressed" 0 "Button not pressed" ;
VAL_ 2365446398 Joystick2Button7PressedStatus 3 "Not Available" 2 "Error Indicator" 1 "Button pressed" 0 "Button not pressed" ;
VAL_ 2365446398 Joystick2Button8PressedStatus 3 "Not Available" 2 "Error Indicator" 1 "Button pressed" 0 "Button not pressed" ;
VAL_ 2365446398 Joystick2Button1PressedStatus 3 "Not Available" 2 "Error Indicator" 1 "Button pressed" 0 "Button not pressed" ;
VAL_ 2365446398 Joystick2Button2PressedStatus 3 "Not Available" 2 "Error Indicator" 1 "Button pressed" 0 "Button not pressed" ;
VAL_ 2365446398 Joystick2Button3PressedStatus 3 "Not Available" 2 "Error Indicator" 1 "Button pressed" 0 "Button not pressed" ;
VAL_ 2365446398 Joystick2Button4PressedStatus 3 "Not Available" 2 "Error Indicator" 1 "Button pressed" 0 "Button not pressed" ;
VAL_ 2365445886 Joystick1XAxisDetentPosStatus 3 "Not Available" 2 "Error Indicator" 1 "In the Detent Position" 0 "Not in the Detent Position" ;
VAL_ 2365445886 Joystick1YAxisDetentPosStatus 3 "Not Available" 2 "Error Indicator" 1 "In the Detent Position" 0 "Not in the Detent Position" ;
VAL_ 2365445886 Jystck1YAxsLvrFrwrdPstvPosStatus 3 "Not Available" 2 "Error Indicator" 1 "On positive side of Neutral" 0 "Not on Positive side of Neutral" ;
VAL_ 2365445886 Jystck1YAxsLvrBckNgtivePosStatus 3 "Not Available" 2 "Error Indicator" 1 "On negative side of Neutral" 0 "Not on negative side of Neutral" ;
VAL_ 2365445886 Joystick1YAxisNeutralPosStatus 3 "Not Available" 2 "Error Indicator" 1 "In Neutral Position" 0 "Not in Neutral Position" ;
VAL_ 2365445886 Joystick1Button9PressedStatus 3 "Not Available" 2 "Error Indicator" 1 "Button pressed" 0 "Button not pressed" ;
VAL_ 2365445886 Joystick1Button10PressedStatus 3 "Not Available" 2 "Error Indicator" 1 "Button pressed" 0 "Button not pressed" ;
VAL_ 2365445886 Joystick1Button11PressedStatus 3 "Not Available" 2 "Error Indicator" 1 "Button pressed" 0 "Button not pressed" ;
VAL_ 2365445886 Joystick1Button12PressedStatus 3 "Not Available" 2 "Error Indicator" 1 "Button pressed" 0 "Button not pressed" ;
VAL_ 2365445886 Joystick1Button5PressedStatus 3 "Not Available" 2 "Error Indicator" 1 "Button pressed" 0 "Button not pressed" ;
VAL_ 2365445886 Joystick1Button6PressedStatus 3 "Not Available" 2 "Error Indicator" 1 "Button pressed" 0 "Button not pressed" ;
VAL_ 2365445886 Joystick1Button7PressedStatus 3 "Not Available" 2 "Error Indicator" 1 "Button pressed" 0 "Button not pressed" ;
VAL_ 2365445886 Joystick1Button8PressedStatus 3 "Not Available" 2 "Error Indicator" 1 "Button pressed" 0 "Button not pressed" ;
VAL_ 2365445886 Joystick1Button1PressedStatus 3 "Not Available" 2 "Error Indicator" 1 "Button pressed" 0 "Button not pressed" ;
VAL_ 2365445886 Joystick1Button2PressedStatus 3 "Not Available" 2 "Error Indicator" 1 "Button pressed" 0 "Button not pressed" ;
VAL_ 2365445886 Joystick1Button3PressedStatus 3 "Not Available" 2 "Error Indicator" 1 "Button pressed" 0 "Button not pressed" ;
VAL_ 2365445886 Joystick1Button4PressedStatus 3 "Not Available" 2 "Error Indicator" 1 "Button pressed" 0 "Button not pressed" ;
VAL_ 2365445886 Jystck1XAxsLvrRghtPstvePosStatus 3 "Not Available" 2 "Error Indicator" 1 "On positive side of Neutral" 0 "Not on Positive side of Neutral" ;
VAL_ 2365445886 Jystck1XAxsLvrLftNgtivePosStatus 3 "Not Available" 2 "Error Indicator" 1 "On negative side of Neutral" 0 "Not on negative side of Neutral" ;
VAL_ 2365445886 Joystick1XAxisNeutralPosStatus 3 "Not Available" 2 "Error Indicator" 1 "In Neutral Position" 0 "Not in Neutral Position" ;
